VERSION ""

NS_ :

BS_:

BU_: Airbag Allrad EPS Teves_MK60_ESP LWS LWR Teves_MK70_MABS Waehlhebel EPB TRW_ESP ACC_Radar AFS Magne_Ride RKA_Plus Selespeed Waehlhebel_Sele PDC_PLA Lenkhilfe_APA VAQ Daempfer Hybrid_BMS Hybrid_PWR Hybrid_DQ200 EKlimakomp SWA HCA ACC_Lidar Lenkhilfe_ZF_3G FLA AG6 DQ Hybrid_MSG Diesel Otto Gateway_PQ35_A Gateway_PQ46_A Vector_XXX Fzg_CAN

BO_ 3221225472 VECTOR__INDEPENDENT_SIG_MSG: 0 Vector__XXX
 SG_ AL1_Begrenzungsmo : 0|8@1+ (0.39,0) [0|99.06] "%MDI" Vector__XXX
 SG_ BR2_Sta_BrAssi : 0|1@1+ (1,0) [0|1] "" Vector__XXX
 SG_ BR2_Zeitstemp : 0|16@1+ (1,0) [0|65535] "tics" Vector__XXX
 SG_ BR2_TTic_Skal : 0|8@1+ (0.04,0) [0|10.2] "µs" Vector__XXX
 SG_ BR2_Querb_TTic : 0|1@1+ (1,0) [0|1] "" Vector__XXX
 SG_ EP1_Verschleiss : 0|2@1+ (1,0) [0|3] "" Vector__XXX
 SG_ GE1_Code_MSG : 0|1@1+ (1,0) [0|1] "" Vector__XXX
 SG_ GE1_v_halten : 0|1@1+ (1,0) [0|1] "" Vector__XXX
 SG_ GE1_Mrad_Mk2 : 0|8@1+ (0.4,0) [0|101.6] "" Vector__XXX
 SG_ GH1_FreigabeSSK0 : 0|1@1+ (1,0) [0|1] "" Vector__XXX
 SG_ LDW_res_24 : 0|1@1+ (1,0) [0|1] "" Vector__XXX
 SG_ LDW_res_25 : 0|1@1+ (1,0) [0|1] "" Vector__XXX
 SG_ LDW_res_26 : 0|1@1+ (1,0) [0|1] "" Vector__XXX
 SG_ LDW_res_28 : 0|1@1+ (1,0) [0|1] "" Vector__XXX
 SG_ LDW_res_29 : 0|1@1+ (1,0) [0|1] "" Vector__XXX
 SG_ LDW_res_30 : 0|1@1+ (1,0) [0|1] "" Vector__XXX
 SG_ LDW_res_31 : 0|1@1+ (1,0) [0|1] "" Vector__XXX
 SG_ LDW_res_32 : 0|1@1+ (1,0) [0|1] "" Vector__XXX
 SG_ LDW_res_33 : 0|1@1+ (1,0) [0|1] "" Vector__XXX
 SG_ LDW_res_34 : 0|1@1+ (1,0) [0|1] "" Vector__XXX
 SG_ LDW_res_27 : 0|1@1+ (1,0) [0|1] "" Vector__XXX
 SG_ LDW_res_37 : 0|1@1+ (1,0) [0|1] "" Vector__XXX
 SG_ LDW_res_38 : 0|1@1+ (1,0) [0|1] "" Vector__XXX
 SG_ LDW_res_39 : 0|1@1+ (1,0) [0|1] "" Vector__XXX
 SG_ LDW_res_35 : 0|1@1+ (1,0) [0|1] "" Vector__XXX
 SG_ LDW_res_40 : 0|1@1+ (1,0) [0|1] "" Vector__XXX
 SG_ LDW_res_36 : 0|1@1+ (1,0) [0|1] "" Vector__XXX
 SG_ LDW_res_42 : 0|1@1+ (1,0) [0|1] "" Vector__XXX
 SG_ LDW_res_43 : 0|1@1+ (1,0) [0|1] "" Vector__XXX
 SG_ LDW_res_44 : 0|1@1+ (1,0) [0|1] "" Vector__XXX
 SG_ LDW_res_41 : 0|1@1+ (1,0) [0|1] "" Vector__XXX
 SG_ LDW_res_45 : 0|1@1+ (1,0) [0|1] "" Vector__XXX
 SG_ LDW_res_46 : 0|1@1+ (1,0) [0|1] "" Vector__XXX
 SG_ LDW_res_47 : 0|1@1+ (1,0) [0|1] "" Vector__XXX
 SG_ LDW_res_48 : 0|1@1+ (1,0) [0|1] "" Vector__XXX
 SG_ LDW_res_49 : 0|1@1+ (1,0) [0|1] "" Vector__XXX
 SG_ LDW_res_51 : 0|1@1+ (1,0) [0|1] "" Vector__XXX
 SG_ LDW_res_52 : 0|1@1+ (1,0) [0|1] "" Vector__XXX
 SG_ LDW_res_53 : 0|1@1+ (1,0) [0|1] "" Vector__XXX
 SG_ LDW_res_54 : 0|1@1+ (1,0) [0|1] "" Vector__XXX
 SG_ LDW_res_50 : 0|1@1+ (1,0) [0|1] "" Vector__XXX
 SG_ LDW_res_55 : 0|1@1+ (1,0) [0|1] "" Vector__XXX
 SG_ LDW_res_56 : 0|1@1+ (1,0) [0|1] "" Vector__XXX
 SG_ LDW_res_57 : 0|1@1+ (1,0) [0|1] "" Vector__XXX
 SG_ LDW_res_59 : 0|1@1+ (1,0) [0|1] "" Vector__XXX
 SG_ LDW_res_60 : 0|1@1+ (1,0) [0|1] "" Vector__XXX
 SG_ LDW_res_62 : 0|1@1+ (1,0) [0|1] "" Vector__XXX
 SG_ LDW_res_61 : 0|1@1+ (1,0) [0|1] "" Vector__XXX
 SG_ LDW_res_63 : 0|1@1+ (1,0) [0|1] "" Vector__XXX
 SG_ LDW_res_58 : 0|1@1+ (1,0) [0|1] "" Vector__XXX
 SG_ MO2_Freigabe_Sport : 0|1@1+ (1,0) [0|1] "" Vector__XXX
 SG_ MO7_Ladedruck : 0|8@1+ (0.01,0) [0|2.54] "bar" Vector__XXX
 SG_ KO1_Warn_Heiss : 0|1@1+ (1,0) [0|1] "" Vector__XXX
 SG_ KO2_AussT_FehArt : 0|3@1+ (1,0) [0|7] "" Vector__XXX
 SG_ KO2_Sta_KuehlT : 0|1@1+ (1,0) [0|1] "" Vector__XXX
 SG_ KO2_Sta_Oel_T : 0|1@1+ (1,0) [0|1] "" Vector__XXX
 SG_ GK1_RDWarn_VL : 0|1@1+ (1,0) [0|1] "" Vector__XXX
 SG_ GK1_RDWarn_VR : 0|1@1+ (1,0) [0|1] "" Vector__XXX
 SG_ GK1_RDWarn_HR : 0|1@1+ (1,0) [0|1] "" Vector__XXX
 SG_ GK1_RDWarn_Res : 0|1@1+ (1,0) [0|1] "" Vector__XXX
 SG_ GK1_RDWarn_HL : 0|1@1+ (1,0) [0|1] "" Vector__XXX
 SG_ GK1_RDWarn_1 : 0|1@1+ (1,0) [0|1] "" Vector__XXX
 SG_ GK1_RDK_System : 0|1@1+ (1,0) [0|1] "" Vector__XXX
 SG_ GK1_RDWarn_2 : 0|1@1+ (1,0) [0|1] "" Vector__XXX
 SG_ BSL_DFM : 0|8@1+ (0.4,0) [0|101.6] "%" Vector__XXX
 SG_ BSL_U_Start_BATT : 0|8@1+ (0.05,5) [5|17.7] "V" Vector__XXX

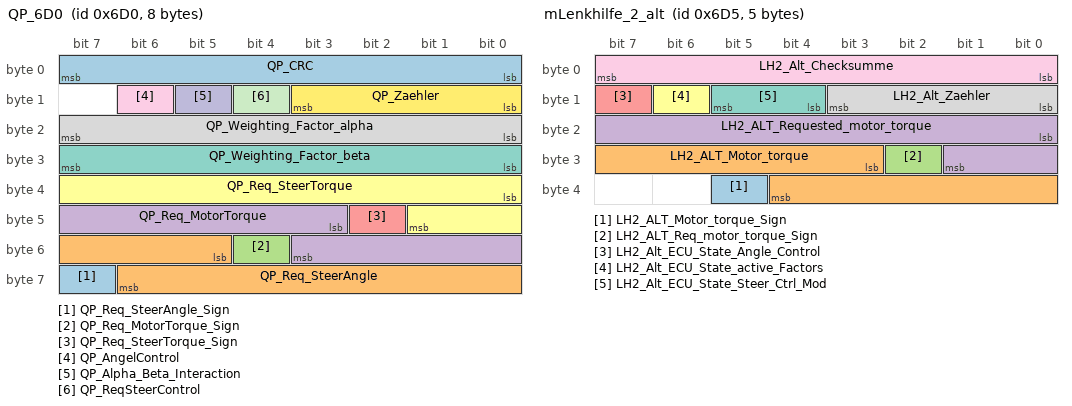
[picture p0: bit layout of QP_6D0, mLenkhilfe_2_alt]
BO_ 1744 QP_6D0: 8 Fzg_CAN
 SG_ QP_Req_SteerAngle_Sign : 63|1@1+ (1,0) [0|1] ""  EPS
 SG_ QP_Req_SteerAngle : 53|10@1+ (1,0) [0|1023] "°"  EPS
 SG_ QP_Req_MotorTorque_Sign : 52|1@1+ (1,0) [0|1] ""  EPS
 SG_ QP_Req_MotorTorque : 43|9@1+ (0.01,0) [0|5.11] "Nm"  EPS
 SG_ QP_Req_SteerTorque_Sign : 42|1@1+ (1,0) [0|1] ""  EPS
 SG_ QP_Req_SteerTorque : 32|10@1+ (0.01,0) [0|10.23] "Nm"  EPS
 SG_ QP_Weighting_Factor_beta : 24|8@1+ (1,0) [0|0] ""  EPS
 SG_ QP_Weighting_Factor_alpha : 16|8@1+ (1,0) [0|0] ""  EPS
 SG_ QP_AngelControl : 14|1@1+ (1,0) [0|0] ""  EPS
 SG_ QP_Alpha_Beta_Interaction : 13|1@1+ (1,0) [0|0] ""  EPS
 SG_ QP_ReqSteerControl : 12|1@1+ (1,0) [0|1] ""  EPS
 SG_ QP_Zaehler : 8|4@1+ (1,0) [0|0] ""  EPS
 SG_ QP_CRC : 0|8@1+ (1,0) [0|0] ""  EPS

 BO_ 1749 mLenkhilfe_2_alt: 5 EPS
 SG_ LH2_ALT_Motor_torque_Sign : 37|1@1+ (1,0) [0|1] ""  Fzg_CAN
 SG_ LH2_ALT_Motor_torque : 27|10@1+ (0.005,0) [0|5.115] "Nm"  Fzg_CAN
 SG_ LH2_ALT_Req_motor_torque_Sign : 26|1@1+ (1,0) [0|1] ""  Fzg_CAN
 SG_ LH2_ALT_Requested_motor_torque : 16|10@1+ (0.006,0) [0|6.138] "Nm"  Fzg_CAN
 SG_ LH2_Alt_ECU_State_Angle_Control : 15|1@1+ (1,0) [0|0] ""  Fzg_CAN
 SG_ LH2_Alt_ECU_State_active_Factors : 14|1@1+ (1,0) [0|0] ""  Fzg_CAN
 SG_ LH2_Alt_ECU_State_Steer_Ctrl_Mod : 12|2@1+ (1,0) [0|0] ""  Fzg_CAN
 SG_ LH2_Alt_Zaehler : 8|4@1+ (1,0) [0|0] ""  Fzg_CAN
 SG_ LH2_Alt_Checksumme : 0|8@1+ (1,0) [0|0] ""  Fzg_CAN

BO_ 80 mAirbag_1: 4 Airbag
 SG_ AB1_Front : 0|1@1+ (1,0) [0|1] ""  Gateway_PQ46_A,Diesel,EPB,TRW_ESP,Gateway_PQ35_A,Hybrid_PWR,Hybrid_BMS,Hybrid_MSG,HCA,SWA,Teves_MK60_ESP
 SG_ AB1_Heck : 1|1@1+ (1,0) [0|1] ""  Gateway_PQ46_A,Diesel,EPB,TRW_ESP,Gateway_PQ35_A,Hybrid_PWR,Hybrid_BMS,Hybrid_MSG,HCA,SWA,Teves_MK60_ESP
 SG_ AB1_Fa_Seite : 2|1@1+ (1,0) [0|1] ""  Gateway_PQ46_A,Diesel,EPB,TRW_ESP,Gateway_PQ35_A,Hybrid_PWR,Hybrid_BMS,Hybrid_MSG,HCA,SWA,Teves_MK60_ESP
 SG_ AB1_Bf_Seite : 3|1@1+ (1,0) [0|1] ""  Gateway_PQ46_A,Diesel,EPB,TRW_ESP,Gateway_PQ35_A,Hybrid_PWR,Hybrid_BMS,Hybrid_MSG,HCA,SWA,Teves_MK60_ESP
 SG_ AB1_Rollover : 4|1@1+ (1,0) [0|1] ""  Gateway_PQ46_A,Diesel,Teves_MK60_ESP,Teves_MK70_MABS,EPB,TRW_ESP,Gateway_PQ35_A,Hybrid_PWR,Hybrid_BMS,Hybrid_MSG,HCA
 SG_ AB1_Status : 9|1@1+ (1,0) [0|1] ""  Gateway_PQ46_A,EPB,TRW_ESP,Gateway_PQ35_A,Hybrid_BMS,Hybrid_MSG,Hybrid_PWR,HCA,Teves_MK60_ESP
 SG_ AB1_Lampe : 8|1@1+ (1,0) [0|1] ""  Gateway_PQ46_A,EPB,TRW_ESP,Gateway_PQ35_A,Hybrid_PWR,Hybrid_BMS,Hybrid_MSG,HCA,Teves_MK60_ESP
 SG_ AB1_Beifahrer : 10|1@1+ (1,0) [0|1] ""  Gateway_PQ46_A,EPB,TRW_ESP,Gateway_PQ35_A,Hybrid_BMS,Hybrid_PWR,Hybrid_MSG,HCA,Teves_MK60_ESP
 SG_ AB1_System : 11|1@1+ (1,0) [0|1] ""  Gateway_PQ46_A,EPB,TRW_ESP,Gateway_PQ35_A,Hybrid_PWR,Hybrid_BMS,Hybrid_MSG,HCA,Teves_MK60_ESP
 SG_ AB1_Gurt_Fa : 12|2@1+ (1,0) [0|3] ""  Gateway_PQ46_A,EPB,TRW_ESP,Gateway_PQ35_A,Hybrid_BMS,Hybrid_MSG,Hybrid_PWR,HCA,Teves_MK60_ESP,Diesel,Otto
 SG_ AB1_Gurt_Bf : 14|2@1+ (1,0) [0|3] ""  Gateway_PQ46_A,EPB,TRW_ESP,Gateway_PQ35_A,Hybrid_BMS,Hybrid_MSG,Hybrid_PWR,HCA,Teves_MK60_ESP
 SG_ AB1_Stellglied : 17|1@1+ (1,0) [0|1] ""  Gateway_PQ46_A,Diesel,EPB,TRW_ESP,Gateway_PQ35_A,Hybrid_BMS,Hybrid_PWR,Hybrid_MSG,HCA,Teves_MK60_ESP,Otto
 SG_ AB1_BF_Warnung : 18|1@1+ (1,0) [0|1] ""  Gateway_PQ46_A,EPB,TRW_ESP,Gateway_PQ35_A,Hybrid_BMS,Hybrid_PWR,Hybrid_MSG,HCA,Teves_MK60_ESP
 SG_ AB1_Diagnose : 16|1@1+ (1,0) [0|1] ""  Gateway_PQ46_A,Gateway_PQ35_A,Hybrid_MSG,HCA,Hybrid_PWR,Hybrid_BMS,TRW_ESP,EPB,Teves_MK60_ESP
 SG_ AB1_Zaehler : 20|4@1+ (1,0) [0|15] ""  Gateway_PQ46_A,Diesel,Otto,EPB,TRW_ESP,Gateway_PQ35_A,Hybrid_MSG,Hybrid_PWR,Hybrid_BMS,HCA,Teves_MK60_ESP
 SG_ AB1_Intens : 5|3@1+ (1,0) [0|7] ""  Gateway_PQ46_A,Diesel,Otto,Teves_MK60_ESP,Teves_MK70_MABS,EPB,TRW_ESP,Gateway_PQ35_A,Hybrid_MSG,Hybrid_PWR,Hybrid_BMS,HCA,SWA
 SG_ AB1_Fehlereintr : 19|1@1+ (1,0) [0|1] ""  Gateway_PQ46_A,EPB,TRW_ESP,Gateway_PQ35_A,Hybrid_BMS,Hybrid_PWR,Hybrid_MSG,HCA,Teves_MK60_ESP
 SG_ AB1_Checksumme : 24|8@1+ (1,0) [0|255] ""  Gateway_PQ46_A,Diesel,Otto,EPB,TRW_ESP,Gateway_PQ35_A,Hybrid_MSG,Hybrid_PWR,Hybrid_BMS,HCA,Teves_MK60_ESP

BO_ 1360 mAirbag_2: 8 Airbag
 SG_ AB2_Beleg_HBF : 10|2@1+ (1,0) [0|3] ""  Gateway_PQ46_A,Gateway_PQ35_A
 SG_ AB2_OOP_BF : 19|3@1+ (1,0) [0|7] ""  Gateway_PQ46_A,Gateway_PQ35_A
 SG_ AB2_Checksum : 0|8@1+ (1,0) [0|255] ""  Gateway_PQ46_A,Gateway_PQ35_A
 SG_ AB2_Beleg_HM : 12|2@1+ (1,0) [0|3] ""  Gateway_PQ46_A,Gateway_PQ35_A
 SG_ AB2_Beleg_HF : 8|2@1+ (1,0) [0|3] ""  Gateway_PQ46_A,Gateway_PQ35_A
 SG_ AB2_Beleg_BF : 14|2@1+ (1,0) [0|3] ""  Gateway_PQ46_A,Gateway_PQ35_A
 SG_ AB2_OOP_Fa : 16|3@1+ (1,0) [0|7] ""  Gateway_PQ46_A,Gateway_PQ35_A
 SG_ AB2_Sta_BF : 22|2@1+ (1,0) [0|3] ""  Gateway_PQ46_A,Gateway_PQ35_A
 SG_ AB2_Gurt_2FaS : 24|2@1+ (1,0) [0|3] ""  Gateway_PQ35_A,Gateway_PQ46_A
 SG_ AB2_Gurt_2BfS : 26|2@1+ (1,0) [0|3] ""  Gateway_PQ35_A,Gateway_PQ46_A
 SG_ AB2_Gurt_2Mi : 28|2@1+ (1,0) [0|3] ""  Gateway_PQ35_A,Gateway_PQ46_A
 SG_ AB2_Gurt_3BfS : 32|2@1+ (1,0) [0|3] ""  Gateway_PQ35_A,Gateway_PQ46_A
 SG_ AB2_Gurt_3FaS : 30|2@1+ (1,0) [0|3] ""  Gateway_PQ35_A,Gateway_PQ46_A
 SG_ AB2_Reserve2 : 36|4@1+ (1,0) [0|15] ""  Gateway_PQ46_A,Gateway_PQ35_A
 SG_ AB2_Gurt_3Mi : 34|2@1+ (1,0) [0|3] ""  Gateway_PQ35_A,Gateway_PQ46_A
 SG_ AB2_Reserve3 : 40|8@1+ (1,0) [0|255] ""  Gateway_PQ46_A,Gateway_PQ35_A
 SG_ AB2_Reserve4 : 48|8@1+ (1,0) [0|255] ""  Gateway_PQ46_A,Gateway_PQ35_A
 SG_ AB2_Reserve5 : 56|8@1+ (1,0) [0|255] ""  Gateway_PQ46_A,Gateway_PQ35_A

BO_ 517 mTP_Er_Airbag: 7 Airbag
 SG_ Airbag_TP_Er : 0|56@1+ (1,0) [0|7.2057594038E+016] ""  Gateway_PQ46_A,Gateway_PQ35_A

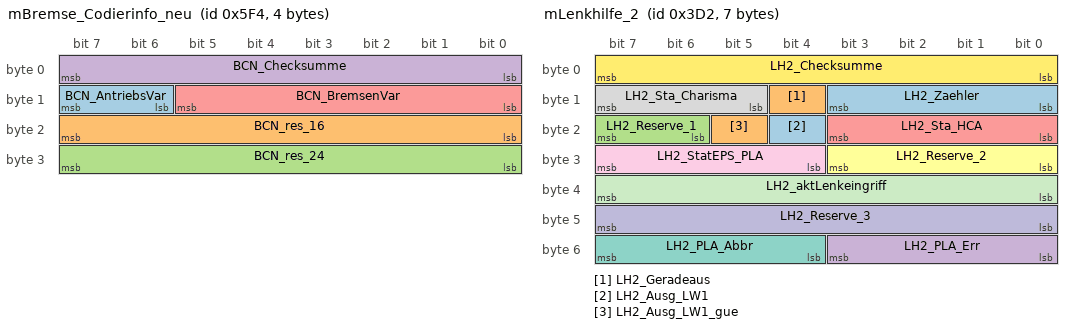
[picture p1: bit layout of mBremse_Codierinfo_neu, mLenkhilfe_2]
BO_ 1524 mBremse_Codierinfo_neu: 4 Airbag
 SG_ BCN_AntriebsVar : 14|2@1+ (1,0) [0|3] ""  Teves_MK60_ESP
 SG_ BCN_res_16 : 16|8@1+ (1,0) [0|255] ""  Teves_MK60_ESP
 SG_ BCN_res_24 : 24|8@1+ (1,0) [0|255] ""  Teves_MK60_ESP
 SG_ BCN_Checksumme : 0|8@1+ (1,0) [0|255] ""  Teves_MK60_ESP
 SG_ BCN_BremsenVar : 8|6@1+ (1,0) [0|63] ""  Teves_MK60_ESP

BO_ 1919 ISO_Airbag_01_Resp: 8 Airbag
 SG_ ISO_Airbag_01_Resp_Data : 0|64@1+ (1,0) [0|1.8446744074E+019] ""  Gateway_PQ46_A,Gateway_PQ35_A

BO_ 2041 Resp_Airbag_Deployment: 8 Airbag
 SG_ Resp_Airbag_Deployment : 0|64@1+ (1,0) [0|1.8446744074E+019] ""  Gateway_PQ46_A,Gateway_PQ35_A

BO_ 522 mTP_Er_Allrad: 7 Allrad
 SG_ Allrad_TP_Er : 0|56@1+ (1,0) [0|7.2057594038E+016] ""  Gateway_PQ46_A,Gateway_PQ35_A

BO_ 704 mAllrad_1: 8 Allrad
 SG_ AL1_Sta_Kup : 2|1@1+ (1,0) [0|1] ""  Gateway_PQ46_A,TRW_ESP,Gateway_PQ35_A,Teves_MK60_ESP
 SG_ AL1_Uebertemp : 1|1@1+ (1,0) [0|1] ""  Gateway_PQ46_A,TRW_ESP,Gateway_PQ35_A
 SG_ AL1_Kup_offen : 3|1@1+ (1,0) [0|1] ""  Gateway_PQ46_A,TRW_ESP,Gateway_PQ35_A,RKA_Plus
 SG_ AL1_Fehler : 0|1@1+ (1,0) [0|1] ""  Gateway_PQ46_A,TRW_ESP,Gateway_PQ35_A,RKA_Plus,Teves_MK60_ESP
 SG_ AL1_Einheit M : 7|1@1+ (1,0) [0|1] ""  Gateway_PQ46_A,Teves_MK60_ESP,Teves_MK70_MABS,TRW_ESP,Gateway_PQ35_A,RKA_Plus
 SG_ AL1_Warnlampe : 5|1@1+ (1,0) [0|1] ""  Gateway_PQ46_A,TRW_ESP,Gateway_PQ35_A
 SG_ AL1_Limiter : 6|1@1+ (1,0) [0|1] ""  Gateway_PQ46_A,Gateway_PQ35_A
 SG_ AL1_Ist_Proz m1 : 8|8@1+ (0.794,-101.632) [0|100.044] "%"  Gateway_PQ46_A,Teves_MK60_ESP,Teves_MK70_MABS,TRW_ESP,Gateway_PQ35_A,RKA_Plus
 SG_ AL1_Notlauf : 4|1@1+ (1,0) [0|1] ""  Gateway_PQ46_A,TRW_ESP,Gateway_PQ35_A
 SG_ AL1_Sta_PNG : 16|3@1+ (1,0) [0|7] ""  Gateway_PQ46_A,Gateway_PQ35_A,AFS,Teves_MK60_ESP
 SG_ AL1_Schalten : 24|1@1+ (1,0) [0|1] ""  Gateway_PQ46_A,Gateway_PQ35_A
 SG_ AL1_Quersp_Sta : 46|2@1+ (1,0) [0|3] ""  Gateway_PQ46_A,Gateway_PQ35_A
 SG_ AL1_Vorwarnung : 25|1@1+ (1,0) [0|1] ""  Gateway_PQ46_A,Gateway_PQ35_A
 SG_ AL1_Fehlereintr : 31|1@1+ (1,0) [0|1] ""  Gateway_PQ46_A,Gateway_PQ35_A
 SG_ AL1_Anz_blinken : 19|1@1+ (1,0) [0|1] ""  Gateway_PQ46_A,Gateway_PQ35_A
 SG_ AL1_Sta_Laengssp : 20|2@1+ (1,0) [0|3] ""  Gateway_PQ46_A,Gateway_PQ35_A
 SG_ AL1_Ist_Nm m0 : 8|8@1+ (7,-896) [-896|882] "Nm"  Gateway_PQ46_A,TRW_ESP,Gateway_PQ35_A,RKA_Plus
 SG_ AL1_Diff_Verbau : 56|1@1+ (1,0) [0|1] ""  Gateway_PQ46_A,Gateway_PQ35_A
 SG_ AL1_AnfVerteiler : 27|1@1+ (1,0) [0|1] ""  Gateway_PQ46_A,Gateway_PQ35_A
 SG_ AL1_FaWu_Laengs : 40|2@1+ (1,0) [0|3] ""  Gateway_PQ46_A,Gateway_PQ35_A
 SG_ AL1_FaWu_HA : 42|2@1+ (1,0) [0|3] ""  Gateway_PQ46_A,Gateway_PQ35_A
 SG_ AL1_Limit_maxkmh : 48|8@1+ (1,0) [0|254] ""  Gateway_PQ46_A,Gateway_PQ35_A
 SG_ AL1_KupSteifig_F : 30|1@1+ (1,0) [0|1] ""  Gateway_PQ46_A,Gateway_PQ35_A
 SG_ AL1_FaWu_VA : 44|2@1+ (1,0) [0|3] ""  Gateway_PQ46_A,Gateway_PQ35_A
 SG_ AL1_Sta_VA : 28|2@1+ (1,0) [0|3] ""  Gateway_PQ46_A,Gateway_PQ35_A
 SG_ AL1_Sta_Quersp : 22|2@1+ (1,0) [0|3] ""  Gateway_PQ46_A,Gateway_PQ35_A
 SG_ AL1_Warnton : 59|1@1+ (1,0) [0|1] ""  Gateway_PQ46_A,Gateway_PQ35_A
 SG_ AL1_Stellung_Getr : 26|1@1+ (1,0) [0|1] ""  Gateway_PQ46_A,Gateway_PQ35_A,Teves_MK60_ESP
 SG_ AL1_KupplTemp : 32|8@1+ (1,-60) [-60|193] "°C"  Gateway_PQ46_A,Gateway_PQ35_A
 SG_ AL1_Diff_Lampe : 57|1@1+ (1,0) [0|1] ""  Gateway_PQ46_A,Gateway_PQ35_A
 SG_ AL1_Zaehler : 60|4@1+ (1,0) [0|15] ""  Gateway_PQ46_A,Gateway_PQ35_A,TRW_ESP
 SG_ AL1_Diff_Gong : 58|1@1+ (1,0) [0|1] ""  Gateway_PQ46_A,Gateway_PQ35_A

BO_ 978 mLenkhilfe_2: 7 EPS
 SG_ LH2_Zaehler : 8|4@1+ (1,0) [0|15] ""  PDC_PLA,HCA
 SG_ LH2_Geradeaus : 12|1@1+ (1,0) [0|1] ""  LWS,Magne_Ride,PDC_PLA,HCA
 SG_ LH2_Reserve_1 : 22|2@1+ (1,0) [0|3] ""  HCA,PDC_PLA
 SG_ LH2_PLA_Err : 48|4@1+ (1,0) [0|15] ""  PDC_PLA,HCA
 SG_ LH2_Sta_HCA : 16|4@1+ (1,0) [0|15] ""  PDC_PLA,HCA
 SG_ LH2_Reserve_2 : 24|4@1+ (1,0) [0|15] ""  HCA,PDC_PLA
 SG_ LH2_PLA_Abbr : 52|4@1+ (1,0) [0|15] ""  PDC_PLA,HCA
 SG_ LH2_Sta_Charisma : 13|3@1+ (1,0) [0|3] ""  PDC_PLA,HCA
 SG_ LH2_StatEPS_PLA : 28|4@1+ (1,0) [0|15] ""  PDC_PLA,HCA
 SG_ LH2_Reserve_3 : 40|8@1+ (1,0) [0|255] ""  HCA,PDC_PLA
 SG_ LH2_aktLenkeingriff : 32|8@1+ (1,0) [0|255] ""  PDC_PLA,HCA
 SG_ LH2_Checksumme : 0|8@1+ (1,0) [0|255] ""  PDC_PLA,HCA
 SG_ LH2_Ausg_LW1 : 20|1@1+ (1,0) [0|1] "" Vector__XXX
 SG_ LH2_Ausg_LW1_gue : 21|1@1+ (1,0) [0|1] "" Vector__XXX

BO_ 976 mLenkhilfe_1: 6 EPS
 SG_ LH1_Sicherheitslamp : 8|1@1+ (1,0) [0|1] ""  Gateway_PQ46_A,Gateway_PQ35_A
 SG_ LH1_Lastinfo : 0|7@1+ (1,0) [0|127] "A"  Gateway_PQ46_A,Gateway_PQ35_A
 SG_ LH1_Reserve1 : 22|2@1+ (1,0) [0|3] ""  Gateway_PQ46_A,Gateway_PQ35_A
 SG_ LH1_Fehlereintr : 15|1@1+ (1,0) [0|1] ""  Gateway_PQ46_A,Gateway_PQ35_A
 SG_ LH1_SleepInd : 14|1@1+ (1,0) [0|1] ""  Gateway_PQ46_A,Gateway_PQ35_A
 SG_ LH1_Fehler_LI : 7|1@1+ (1,0) [0|1] ""  Gateway_PQ46_A,Gateway_PQ35_A
 SG_ LH1_Akustiksign : 13|1@1+ (1,0) [0|1] ""  Gateway_PQ46_A,Gateway_PQ35_A
 SG_ LH1_ULeistung : 32|8@1+ (0.5,0) [0|100] "%"  Gateway_PQ46_A,Gateway_PQ35_A
 SG_ LH1_NL_LeistDichte : 31|1@1+ (1,0) [0|1] ""  Gateway_PQ46_A,Gateway_PQ35_A
 SG_ LH1_EPS_Diagmode : 16|1@1+ (1,0) [0|1] ""  Gateway_PQ46_A,Gateway_PQ35_A
 SG_ LH1_NL_ECU : 29|1@1+ (1,0) [0|1] ""  Gateway_PQ46_A,Gateway_PQ35_A
 SG_ LH1_Textbits : 10|3@1+ (1,0) [0|7] ""  Gateway_PQ46_A,Gateway_PQ35_A
 SG_ LH1_NL_Motor : 30|1@1+ (1,0) [0|1] ""  Gateway_PQ46_A,Gateway_PQ35_A
 SG_ LH1_NL_CAN_SS : 28|1@1+ (1,0) [0|1] ""  Gateway_PQ46_A,Gateway_PQ35_A
 SG_ LH1_NL_Sensor : 27|1@1+ (1,0) [0|1] ""  Gateway_PQ46_A,Gateway_PQ35_A
 SG_ LH1_NL_Uebertemp : 26|1@1+ (1,0) [0|1] ""  Gateway_PQ46_A,Gateway_PQ35_A
 SG_ LH1_NL_Uebersp : 25|1@1+ (1,0) [0|1] ""  Gateway_PQ46_A,Gateway_PQ35_A
 SG_ LH1_NL_Untersp : 24|1@1+ (1,0) [0|1] ""  Gateway_PQ46_A,Gateway_PQ35_A
 SG_ LH1_res_18 : 18|1@1+ (1,0) [0|1] ""  Gateway_PQ46_A,Gateway_PQ35_A
 SG_ LH1_Fehlerlampe : 9|1@1+ (1,0) [0|1] ""  Gateway_PQ46_A,Gateway_PQ35_A
 SG_ LH1_res_17 : 17|1@1+ (1,0) [0|1] ""  Gateway_PQ46_A,Gateway_PQ35_A
 SG_ LH1_gue_ECU_Temp : 19|1@1+ (1,0) [0|1] ""  Gateway_PQ46_A,Gateway_PQ35_A
 SG_ LH1_Kuehlung : 20|1@1+ (1,0) [0|1] ""  Gateway_PQ46_A,Gateway_PQ35_A
 SG_ LH1_ECU_Temp : 40|8@1+ (1,-70) [-70|185] "°C"  Gateway_PQ46_A,Gateway_PQ35_A
 SG_ LH1_Mode_Hybrid : 21|1@1+ (1,0) [0|1] ""  Gateway_PQ46_A,Gateway_PQ35_A

BO_ 521 mTP_Er_Lenkhilfe: 7 EPS
 SG_ Lenkhilfe_TP_Er : 0|56@1+ (1,0) [0|7.2057594038E+016] ""  Gateway_PQ46_A,Gateway_PQ35_A

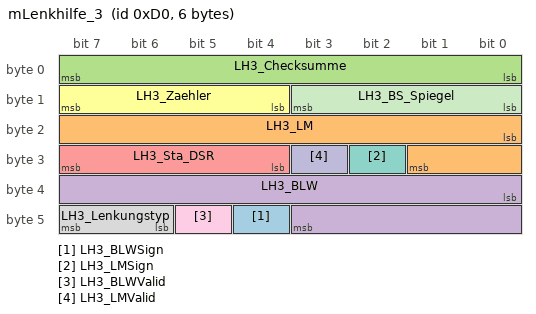
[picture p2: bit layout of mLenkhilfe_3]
BO_ 208 mLenkhilfe_3: 6 EPS
 SG_ LH3_BLWSign : 44|1@1+ (1,0) [0|1] ""  Teves_MK60_ESP,TRW_ESP,HCA,PDC_PLA
 SG_ LH3_LM : 16|10@1+ (0.0147,0) [0|15.0381] "Nm"  Teves_MK60_ESP,TRW_ESP,PDC_PLA,HCA,Diesel,Otto
 SG_ LH3_Checksumme : 0|8@1+ (1,0) [0|255] ""  Teves_MK60_ESP,TRW_ESP,HCA,PDC_PLA
 SG_ LH3_BLW : 32|12@1+ (0.15,0) [0|614.25] "°"  Teves_MK60_ESP,TRW_ESP,HCA,PDC_PLA
 SG_ LH3_Sta_DSR : 28|4@1+ (1,0) [0|15] ""  Teves_MK60_ESP,TRW_ESP,HCA,PDC_PLA
 SG_ LH3_Zaehler : 12|4@1+ (1,0) [0|15] ""  Teves_MK60_ESP,TRW_ESP,HCA,PDC_PLA
 SG_ LH3_LMSign : 26|1@1+ (1,0) [0|1] ""  Teves_MK60_ESP,TRW_ESP,HCA,PDC_PLA,Diesel,Otto
 SG_ LH3_Lenkungstyp : 46|2@1+ (1,0) [0|3] ""  Teves_MK60_ESP,TRW_ESP,HCA,PDC_PLA
 SG_ LH3_BLWValid : 45|1@1+ (1,0) [0|1] ""  Teves_MK60_ESP,TRW_ESP,HCA,PDC_PLA
 SG_ LH3_LMValid : 27|1@1+ (1,0) [0|1] ""  Teves_MK60_ESP,TRW_ESP,HCA,PDC_PLA,Diesel,Otto
 SG_ LH3_BS_Spiegel : 8|4@1+ (1,0) [0|15] ""  Teves_MK60_ESP,TRW_ESP,HCA,PDC_PLA

BO_ 416 mBremse_1: 8 Teves_MK60_ESP
 SG_ BR1_MSR_Anf M : 1|1@1+ (1,0) [0|1] ""  Airbag,Gateway_PQ46_A,Diesel,Otto,DQ,ACC_Radar,Gateway_PQ35_A,RKA_Plus,PDC_PLA,Hybrid_MSG,Hybrid_DQ200,ACC_Lidar,Lenkhilfe_APA
 SG_ BR1_ESP_Eingr : 4|1@1+ (1,0) [0|1] ""  AG6,Airbag,Gateway_PQ46_A,Allrad,Diesel,Otto,DQ,EPB,ACC_Radar,AFS,Gateway_PQ35_A,RKA_Plus,PDC_PLA,Daempfer,Hybrid_MSG,Hybrid_DQ200,HCA,SWA,Selespeed,ACC_Lidar,Lenkhilfe_APA,EPS,Lenkhilfe_ZF_3G
 SG_ BR1_ABS_Brems : 2|1@1+ (1,0) [0|1] ""  Airbag,Gateway_PQ46_A,Allrad,Diesel,DQ,EPB,ACC_Radar,Gateway_PQ35_A,Magne_Ride,RKA_Plus,PDC_PLA,Daempfer,Hybrid_DQ200,HCA,ACC_Lidar,Lenkhilfe_APA
 SG_ BR1_ASR_Anf : 0|1@1+ (1,0) [0|1] ""  Airbag,Gateway_PQ46_A,Diesel,Otto,DQ,ACC_Radar,Gateway_PQ35_A,RKA_Plus,PDC_PLA,Hybrid_MSG,Hybrid_DQ200,ACC_Lidar,Lenkhilfe_APA
 SG_ BR1_ASR_Eingr : 5|2@1+ (1,0) [0|3] ""  AG6,Gateway_PQ46_A,DQ,Gateway_PQ35_A,Hybrid_DQ200,Lenkhilfe_APA
 SG_ BR1_EBV_Eingr : 7|1@1+ (1,0) [0|1] ""  Gateway_PQ46_A,Gateway_PQ35_A,RKA_Plus,Daempfer,Lenkhilfe_APA
 SG_ BR1_StaDruckschw : 12|1@1+ (1,0) [0|1] ""  Gateway_PQ46_A,Diesel,Otto,Gateway_PQ35_A,Hybrid_MSG
 SG_ BR1_Lampe_ASR : 9|1@1+ (1,0) [0|1] ""  Gateway_PQ46_A,Gateway_PQ35_A
 SG_ BR1_Lampe_BK : 10|1@1+ (1,0) [0|1] ""  Gateway_PQ46_A,Gateway_PQ35_A
 SG_ BR1_Lichtschalt : 11|1@1+ (1,0) [0|1] ""  Gateway_PQ46_A,Diesel,Otto,AFS,Gateway_PQ35_A,RKA_Plus,Hybrid_MSG,Lenkhilfe_APA,EPS,Lenkhilfe_ZF_3G
 SG_ BR1_Lampe_ABS : 8|1@1+ (1,0) [0|1] ""  Gateway_PQ46_A,Gateway_PQ35_A
 SG_ BR1_MAD : 13|1@1+ (1,0) [0|1] ""  Gateway_PQ46_A,Gateway_PQ35_A
 SG_ BR1_Sta_MAD : 14|1@1+ (1,0) [0|1] ""  Gateway_PQ46_A,Gateway_PQ35_A
 SG_ BR1_ASRMo_sl : 32|8@1+ (0.39,0) [0|99.06] "%MDI"  Gateway_PQ46_A,Otto,Gateway_PQ35_A,Hybrid_MSG
 SG_ BR1_Diagnose : 15|1@1+ (1,0) [0|1] ""  Gateway_PQ46_A,Gateway_PQ35_A,Airbag
 SG_ BR1_ASRMo_fa m0 : 40|8@1+ (0.39,0) [0|99.06] "%MDI"  Gateway_PQ46_A,Diesel,Otto,Gateway_PQ35_A,Hybrid_MSG
 SG_ BR1_MSR_Mo : 48|8@1+ (0.39,0) [0|99.06] "%MDI"  Gateway_PQ46_A,Diesel,Otto,Gateway_PQ35_A,Hybrid_MSG
 SG_ BR1_BKV_aktiv : 16|1@1+ (1,0) [0|1] ""  Gateway_PQ46_A,Gateway_PQ35_A,Otto,Diesel,Hybrid_MSG
 SG_ BR1_Rad_kmh : 17|15@1+ (0.01,0) [0|326.39] "km/h"  AG6,Airbag,Gateway_PQ46_A,Diesel,EPS,Otto,EPB,ACC_Radar,Gateway_PQ35_A,Magne_Ride,PDC_PLA,Lenkhilfe_APA,Daempfer,Hybrid_MSG,Hybrid_BMS,HCA,SWA,Selespeed,ACC_Lidar,Lenkhilfe_ZF_3G,Hybrid_PWR,FLA
 SG_ BR1_ESPASR_passiv : 61|1@1+ (1,0) [0|1] ""  Gateway_PQ46_A,DQ,ACC_Radar,Gateway_PQ35_A,Magne_Ride,PDC_PLA,Hybrid_DQ200,Selespeed,HCA,ACC_Lidar,Otto,Diesel
 SG_ BR1_Sta_ESP : 62|1@1+ (1,0) [0|1] ""  AG6,Gateway_PQ46_A,Diesel,DQ,ACC_Radar,Gateway_PQ35_A,Magne_Ride,RKA_Plus,Hybrid_DQ200,PDC_PLA,Otto,ACC_Lidar
 SG_ BR1_ASR_ESP : 60|1@1+ (1,0) [0|1] ""  Gateway_PQ46_A,Otto,Gateway_PQ35_A,Hybrid_MSG,Diesel
 SG_ BR1_Zaehler : 56|4@1+ (1,0) [0|15] ""  AG6,Airbag,Gateway_PQ46_A,Diesel,Otto,EPB,ACC_Radar,Gateway_PQ35_A,Magne_Ride,PDC_PLA,Daempfer,Hybrid_MSG,HCA,SWA,ACC_Lidar,Lenkhilfe_APA,EPS,Lenkhilfe_ZF_3G
 SG_ BR1_Ersatz_Kmh : 63|1@1+ (1,0) [0|1] ""  Airbag,Gateway_PQ46_A,Otto,Gateway_PQ35_A,PDC_PLA,Hybrid_MSG,HCA,Lenkhilfe_APA,EPS,Lenkhilfe_ZF_3G
 SG_ BR1_MSR_Mo_inv m1 : 40|8@1+ (-0.39,99.45) [0|99.06] "%MDI"  Gateway_PQ46_A,Diesel,Otto,Gateway_PQ35_A,Hybrid_MSG
 SG_ BR1_EDS_Eingr : 3|1@1+ (1,0) [0|1] ""  Airbag,Gateway_PQ46_A,Diesel,DQ,ACC_Radar,Gateway_PQ35_A,RKA_Plus,PDC_PLA,Daempfer,Hybrid_DQ200,ACC_Lidar,Lenkhilfe_APA

BO_ 1440 mBremse_2: 8 Teves_MK60_ESP
 SG_ BR2_mi_Radgeschw : 9|15@1+ (0.002,0) [0|65.278] "1/s"  Gateway_PQ46_A,DQ,Gateway_PQ35_A,Hybrid_DQ200
 SG_ BR2_QB_Querbeschl m0 : 54|1@1+ (1,0) [0|1] ""  Gateway_PQ46_A,Gateway_PQ35_A,Magne_Ride,RKA_Plus,Allrad,HCA,Diesel,Otto
 SG_ BR2_Querb_Zahn M : 8|1@1+ (1,0) [0|1] ""  Gateway_PQ46_A,Diesel,DQ,Gateway_PQ35_A,Magne_Ride,RKA_Plus,PDC_PLA,Daempfer,Hybrid_DQ200,Otto,HCA,Selespeed,Allrad
 SG_ BR2_Querbeschl m0 : 0|8@1+ (0.01,-1.27) [-1.27|1.27] "g"  Gateway_PQ46_A,Diesel,DQ,Gateway_PQ35_A,Magne_Ride,RKA_Plus,Daempfer,Hybrid_DQ200,Otto,HCA,Selespeed,Allrad
 SG_ BR2_Ueberl_Imp : 51|1@1+ (1,0) [0|1] ""  Gateway_PQ46_A,ACC_Radar,Gateway_PQ35_A,SWA,ACC_Lidar
 SG_ BR2_Fehlereintr : 52|1@1+ (1,0) [0|1] ""  Gateway_PQ46_A,Gateway_PQ35_A
 SG_ BR2_Impulszahl : 56|6@1+ (1,0) [0|63] ""  Gateway_PQ46_A,Gateway_PQ35_A,SWA
 SG_ BR2_LampeHDC : 53|1@1+ (1,0) [0|1] ""  Gateway_PQ46_A,Gateway_PQ35_A
 SG_ BR2_Sta_Imp : 55|1@1+ (1,0) [0|1] ""  Gateway_PQ46_A,ACC_Radar,Gateway_PQ35_A,SWA,ACC_Lidar
 SG_ BR2_Lampe_ASR : 25|1@1+ (1,0) [0|1] ""  Gateway_PQ46_A,Gateway_PQ35_A
 SG_ BR2_SleepInd : 62|1@1+ (1,0) [0|1] ""  Gateway_PQ46_A,Gateway_PQ35_A
 SG_ BR2_Sta_Quer : 63|1@1+ (1,0) [0|1] ""  Gateway_PQ46_A,DQ,Gateway_PQ35_A,Hybrid_DQ200
 SG_ BR2_Wegimpulse : 40|11@1+ (1,0) [0|2047] ""  Gateway_PQ46_A,ACC_Radar,Gateway_PQ35_A,SWA,ACC_Lidar
 SG_ BR2_Aku_Warn : 36|2@1+ (1,0) [0|3] ""  Gateway_PQ46_A,Gateway_PQ35_A
 SG_ BR2_Zahnzahl m1 : 0|6@1+ (1,0) [0|63] ""  Gateway_PQ46_A,Gateway_PQ35_A,RKA_Plus,PDC_PLA
 SG_ BR2_Lampe_ABS : 24|1@1+ (1,0) [0|1] ""  Gateway_PQ46_A,Gateway_PQ35_A,Airbag
 SG_ BR2_Lampe_BK : 26|1@1+ (1,0) [0|1] ""  Gateway_PQ46_A,Gateway_PQ35_A
 SG_ BR2_HDC_aktiv : 38|1@1+ (1,0) [0|1] ""  Gateway_PQ46_A,Diesel,Otto,Gateway_PQ35_A,Hybrid_MSG
 SG_ BR2_Lampe_RKA : 27|1@1+ (1,0) [0|1] ""  Gateway_PQ46_A,Gateway_PQ35_A
 SG_ BR2_Zaehler : 28|4@1+ (1,0) [0|15] ""  Gateway_PQ46_A,Gateway_PQ35_A,Magne_Ride,Daempfer,HCA
 SG_ BR2_Blinkmode : 39|1@1+ (1,0) [0|1] ""  Gateway_PQ46_A,Gateway_PQ35_A
 SG_ BR2_Text : 32|4@1+ (1,0) [0|15] ""  Gateway_PQ46_A,Gateway_PQ35_A

BO_TX_BU_ 978 : Lenkhilfe_ZF_3G,Lenkhilfe_APA,EPS;
BO_TX_BU_ 976 : Lenkhilfe_ZF_3G,Lenkhilfe_APA,EPS;
BO_TX_BU_ 521 : Lenkhilfe_APA,EPS;
BO_TX_BU_ 208 : Lenkhilfe_ZF_3G,Lenkhilfe_APA,EPS;
BO_TX_BU_ 416 : TRW_ESP,Teves_MK70_MABS,Teves_MK60_ESP;
BO_TX_BU_ 1440 : TRW_ESP,Teves_MK70_MABS,Teves_MK60_ESP;

CM_ BO_ 3221225472 "This is a message for not used signals, created by Vector CANdb++ DBC OLE DB Provider.";
CM_ SG_ 3221225472 AL1_Begrenzungsmo "Verteiler Begrenzungsmoment
Der Wert ist gültig, wenn das Bit Verteiler-Anforderung (Byte 4, Bit 3) gesetzt ist. Zum Schutze des VA-Getriebes gibt dieser Wert das max. zulässige Motormoment vor.  Diese Momentenvorgabe  soll analog zum Motoreingriff durch ESP oder Getriebe  in die Min-Auswertung der Motorsteueurng einfließen. ";
CM_ SG_ 3221225472 BR2_Sta_BrAssi "Status Bremsassistent
Textbit: Bremsassistent ausgefallen (nicht VW D1, nicht PQ35/46, nicht D1GP/BY61x) (abwärtskompatibel im Colorado/Colorado GP)Textbit: ´Anfahrhilfe Fehler Werkstatt´ (nur noch T5 alt)";
CM_ SG_ 3221225472 BR2_Zeitstemp "Zeitstempel
Zeitstempel für Geschwindigkeit (mittlere Raddrehzahl) in Timer Tics, z. B. von 20 MHz abgeleitet, und für die Wegimpulse (nur D1GP/BY61x und MK70 alt)";
CM_ SG_ 3221225472 BR2_TTic_Skal "Timer-Skalierung
Wenn Byte 2, Bit 0 = 1: Skalierung des Zeitstempels in den Byte 4 und 5 (nur D1GP/BY61x und MK70 alt)";
CM_ SG_ 3221225472 BR2_Querb_TTic "Querbeschl./TimerTic
Byte 1 hat in der Hochlaufphase eine alternative Bedeutung zur Skalierung des Zeitstempels in den Bytes 4 und 5 (nur D1GP/BY61x und MK70 alt)";
CM_ SG_ 3221225472 EP1_Verschleiss "Verschleissanzeige
00: Belagstärke > x mm10: Belagstärke < y mmes wird der höhere Verschleiss zur Anzeige gebracht (nur Audi D3)";
CM_ SG_ 3221225472 GE1_Code_MSG "Kodierung im MSG
Getriebe-Kodierung im Motor-Steuergerät ist in Ordnung";
CM_ SG_ 3221225472 GE1_v_halten "Geschwindigkeit halten
Bremse verhindert, dass das Fahrzeug beim Schalten des Längsgetriebes zu schnell wird. Nur Colorado!";
CM_ SG_ 3221225472 GE1_Mrad_Mk2 "Übertragungsfunktion
Mrad / Mkurbelwelle für Colorado";
CM_ SG_ 3221225472 GH1_FreigabeSSK0 "Freigabe schnelles Schließen K0
PL71 Hybrid: GSG zeigt an, dass K0 bei Wiederstart schnell geschlossen werden soll (Zweck: Verwendung des folgenden DZ-Sprunges zur Synchronisierung)";
CM_ SG_ 3221225472 LDW_res_24 " 
 ";
CM_ SG_ 3221225472 LDW_res_25 " 
 ";
CM_ SG_ 3221225472 LDW_res_26 " 
 ";
CM_ SG_ 3221225472 LDW_res_28 " 
 ";
CM_ SG_ 3221225472 LDW_res_29 " 
 ";
CM_ SG_ 3221225472 LDW_res_30 " 
 ";
CM_ SG_ 3221225472 LDW_res_31 " 
 ";
CM_ SG_ 3221225472 LDW_res_32 " 
 ";
CM_ SG_ 3221225472 LDW_res_33 " 
 ";
CM_ SG_ 3221225472 LDW_res_34 " 
 ";
CM_ SG_ 3221225472 LDW_res_27 " 
 ";
CM_ SG_ 3221225472 LDW_res_37 " 
 ";
CM_ SG_ 3221225472 LDW_res_38 " 
 ";
CM_ SG_ 3221225472 LDW_res_39 " 
 ";
CM_ SG_ 3221225472 LDW_res_35 " 
 ";
CM_ SG_ 3221225472 LDW_res_40 " 
 ";
CM_ SG_ 3221225472 LDW_res_36 " 
 ";
CM_ SG_ 3221225472 LDW_res_42 " 
 ";
CM_ SG_ 3221225472 LDW_res_43 " 
 ";
CM_ SG_ 3221225472 LDW_res_44 " 
 ";
CM_ SG_ 3221225472 LDW_res_41 " 
 ";
CM_ SG_ 3221225472 LDW_res_45 " 
 ";
CM_ SG_ 3221225472 LDW_res_46 " 
 ";
CM_ SG_ 3221225472 LDW_res_47 " 
 ";
CM_ SG_ 3221225472 LDW_res_48 " 
 ";
CM_ SG_ 3221225472 LDW_res_49 " 
 ";
CM_ SG_ 3221225472 LDW_res_51 " 
 ";
CM_ SG_ 3221225472 LDW_res_52 " 
 ";
CM_ SG_ 3221225472 LDW_res_53 " 
 ";
CM_ SG_ 3221225472 LDW_res_54 " 
 ";
CM_ SG_ 3221225472 LDW_res_50 " 
 ";
CM_ SG_ 3221225472 LDW_res_55 " 
 ";
CM_ SG_ 3221225472 LDW_res_56 " 
 ";
CM_ SG_ 3221225472 LDW_res_57 " 
 ";
CM_ SG_ 3221225472 LDW_res_59 " 
 ";
CM_ SG_ 3221225472 LDW_res_60 " 
 ";
CM_ SG_ 3221225472 LDW_res_62 " 
 ";
CM_ SG_ 3221225472 LDW_res_61 " 
 ";
CM_ SG_ 3221225472 LDW_res_63 " 
 ";
CM_ SG_ 3221225472 LDW_res_58 " 
 ";
CM_ SG_ 3221225472 MO2_Freigabe_Sport "Freigabe Sport
Bit wird gesetzt, wenn die Funktion ´Sport´ bei fehlerfreiem System durch das Motor SG realisiert werden kann (nur Otto im Porsche Cayenne)";
CM_ SG_ 3221225472 MO7_Ladedruck "Ladedruck
Zur Anzeige im Kombi (z.Zt. nur Porsche Colorado, PQ35 Bi-Turbo, Audi RS6)Kombi im PQ35-Bi-Turbo und Audi RS6 interpretiert die normierten CAN-Werte (0-254) als 0-100% der Anzeigeskala";
CM_ SG_ 3221225472 KO1_Warn_Heiss "Heißleuchten-Vorwarnung
Heißleuchtenvorwarnung 5 Grad (applizierbar) vor Erreichen der Warnschwelle für die Heißleuchte (nur PQ24/25/T5)";
CM_ SG_ 3221225472 KO2_AussT_FehArt "Fehlerart Aussentemperatur
Die Motorsteuerung muss bei einem Sensorfehler zwischen Min-Fehler (Kurzschluss gegen Masse) und Max-Fehler (Kurzschluss UBat oder Unterbrechung) unterscheiden können (CARB-Forderung)(Porsche Cayenne)";
CM_ SG_ 3221225472 KO2_Sta_KuehlT "Fehlerstatus Kühlmitteltemperatur (Kombi 2)
n.i.O. steht für Fehlerwert, außerhalb des Meßbereichs (ungenau); nicht verbaut oder noch kein aktueller Wert (nur Porsche Cayenne, BY61x abwärtskompatibel)";
CM_ SG_ 3221225472 KO2_Sta_Oel_T "Fehlerstatus Öltemperatur
n.i.O. steht für Fehlerwert, außerhalb des Meßbereichs (ungenau), nicht verbaut oder noch kein aktueller Wert (nur Porsche Cayenne, BY61x abwärtskompatibel)";
CM_ SG_ 3221225472 GK1_RDWarn_VL "Reifendruckwarnung vorne links
Info aus 'mRDK2/mRDK_Status, Byte 1, Bit 0'";
CM_ SG_ 3221225472 GK1_RDWarn_VR "Reifendruckwarnung vorne rechts
Info aus 'mRDK2/mRDK_Status, Byte 1, Bit 1'";
CM_ SG_ 3221225472 GK1_RDWarn_HR "Reifendruckwarnung Hinten rechts
Info aus 'mRDK2/mRDK_Status, Byte 1, Bit 3'";
CM_ SG_ 3221225472 GK1_RDWarn_Res "Reifendruckwarnung Reserverad
Info aus 'mRDK2/mRDK_Status, Byte 1, Bit 4'";
CM_ SG_ 3221225472 GK1_RDWarn_HL "Reifendruckwarnung Hinten links
Info aus 'mRDK2/mRDK_Status, Byte 1, Bit 2'";
CM_ SG_ 3221225472 GK1_RDWarn_1 "RDK-Warnstufe 1
Info aus 'mRDK2/mRDK_Status, Byte 1, Bit 6'; Warnung erster Priorität";
CM_ SG_ 3221225472 GK1_RDK_System "RDK-Systemfehler
Info aus 'mRDK2/mRDK_Status, Byte 1, Bit 7'";
CM_ SG_ 3221225472 GK1_RDWarn_2 "RDK-Warnstufe 2
Info aus 'mRDK2/mRDK_Status, Byte 1, Bit 5'; Warnung zweiter Priorität";
CM_ SG_ 3221225472 BSL_DFM "Klemme DFM
Messwert Tastverhältnis DFM-Signal (z. Zt. nur Cayenne/Touareg GP, D1GP/BY61x, Phaeton ab MJ07) Info aus mBSG_3, Byte 5";
CM_ SG_ 3221225472 BSL_U_Start_BATT "Starter_Batterie_Spannung
Spannungsmessung vom Lastmanagement (Starterbatterie) (im Touareg GP für V10TDI; Phaeton ab MJ07) Info aus mBSG_2, Byte 3";
CM_ SG_ 80 AB1_Front "Front-Crash
Bit wird bei Überschreitung der Gurtstraffer, US-Schwelle und RDW-Schwelle gesetzt";
CM_ SG_ 80 AB1_Heck "Heck-Crash
wird für neu anlaufende Projekte umgesetzt: AB8.4, Audi8/VW8";
CM_ SG_ 80 AB1_Fa_Seite "Seiten-Crash Fahrer
z. Zt. Nur in Verbindung mit Crash-Intensität 100b (Kraftstoffpumpenabsch.) verwendet";
CM_ SG_ 80 AB1_Bf_Seite "Seiten-Crash Beifahrer
z. Zt. Nur in Verbindung mit Crash-Intensität 100b (Kraftstoffpumpenabsch.) verwendet";
CM_ SG_ 80 AB1_Rollover "Rollover
wird im B6 Cabrio und New Beetle Cabrio, Touareg GP und VW465 bedient";
CM_ SG_ 80 AB1_Status "Airbag deaktiviert
Airbag oder Gurtstraffer wurden per Anpassung deaktiviert: Aktualisierung erst nach Selbsttest";
CM_ SG_ 80 AB1_Lampe "Airbag-Lampe
Sicherheitswarnlampe im Kombi wird vom Airbag-SG angesteuert; Zustand der Lampe wird auf dem CAN-Bus ausgegeben (auch Blinkinformation)";
CM_ SG_ 80 AB1_Beifahrer "Beifahrerairbag deaktiviert
Als Option vorgehalten, Beifahrerairbag wurden per Schlüsselschalter oder Insassenerkennung deaktiviert";
CM_ SG_ 80 AB1_System "Airbag-Systemfehler
Warnlampe (Byte 2, Bit 0) wird dauernd angeschaltet";
CM_ SG_ 80 AB1_Gurt_Fa "Gurtschlossabfrage Fahrer
über Schalter im Gurtschloss";
CM_ SG_ 80 AB1_Gurt_Bf "Gurtschlossabfrage Beifahrer
über Schalter im Gurtschloss";
CM_ SG_ 80 AB1_Stellglied "Airbag im Stellgliedtest
zur Unterdrückung einer Notrufauslösung";
CM_ SG_ 80 AB1_BF_Warnung "Gurtwarnung Beifahrer
im Kombi wird eine Gurtwarnung für den Beifahrer ausgelöst (z. B. Beifahrersitz belegt, Gurt nicht angelegt)";
CM_ SG_ 80 AB1_Diagnose "Airbag in Diagnose
Bei Diagnose über UDS nicht mehr bedient";
CM_ SG_ 80 AB1_Zaehler "Zähler (Airbag 1)
überlaufender Botschaftszähler zur Lebenderkennung";
CM_ SG_ 80 AB1_Intens "Crash-Intensität (Airbag 1)
Die folgende Auswertung ist bei VW geplant: ; >= 001: ZV auf, Innenlicht u. Warnblinker ein ; >= 010: Notruf ausgelöst ; >= 100: Kraftstoffabschaltung (mit RDW-Schwelle aktiviert, d.h.Bit 7 = 1);  ; Information bleibt bei jeder Schwellwert-überschreitung für ca. 10 sec bestehen(Achtung: Energiereserve bei abgetrennter Batterie reicht worstcase nur für 150 msec)Anmerkung: Bosch gibt bei Überschreitung der RDW-Schwelle 111b aus";
CM_ SG_ 80 AB1_Fehlereintr "Fehlerspeichereintrag (Airbag 1)
Bei gesetztem Bit ist mindestens ein Kundendienstfehler eingetragen";
CM_ SG_ 80 AB1_Checksumme "Checksumme (Airbag 1)
Prüfsumme, Definition im CAN Lastenheft";
CM_ SG_ 1360 AB2_Beleg_HBF "Belegungserkennung hinten Beifahrer
über Gurt-Wickelband";
CM_ SG_ 1360 AB2_OOP_BF "OOP Beifahrer (reserviert)
00000101X (z.Zt. Vorhalt)100 Ausl. mit 100 %101 Ausl. mit 70 %110 Ausl. mit 30 %111 (z.Zt. Vorhalt)";
CM_ SG_ 1360 AB2_Checksum "Checksumme
Prüfsumme, Definition im CAN Lastenheft";
CM_ SG_ 1360 AB2_Beleg_HM "Belegungserkennung hinten Mitte
über Gurt-Wickelband";
CM_ SG_ 1360 AB2_Beleg_HF "Belegungserkennung hinten Fahrer
über Gurt-Wickelband";
CM_ SG_ 1360 AB2_Beleg_BF "Belegungserkennung Beifahrersitz
Wird in US-Steuergeräten Audi8R/VW8R/AB8.4E++ bedient, optional bei der RdW, falls SBE-EuroNCAP entschieden wird";
CM_ SG_ 1360 AB2_OOP_Fa "OOP Fahrer (reserviert)
00000101X (z.Zt. Vorhalt)100 Ausl. mit 100 %101 Ausl. mit 70 %110 Ausl. mit 30 %111 (z.Zt. Vorhalt)";
CM_ SG_ 1360 AB2_Sta_BF "Aufmerksamkeitserhöhung Beifahrerairbagstatus
Der Fahrer soll bei einem Statuswechsel des Beifahrerairbags (ausgelöst durch die Beifahrerinsassenerkennung oder den Schlüsselschloßschalter) aufmerksam gemacht werden durch eine Anzeige im Kombi!Nur Audi, gültig für: AB2 (4-Türer AU352), B7, C6, D3";
CM_ SG_ 1360 AB2_Gurt_2FaS "Gurtschlossabfrage 2. Reihe Fahrerseite
Gurtwarnung 2. Reihe Fahrerseite für EuroNCAP 6. Stern";
CM_ SG_ 1360 AB2_Gurt_2BfS "Gurtschlossabfrage 2. Reihe Beifahrerseite
Gurtwarnung 2. Reihe Beifahrerseite für EuroNCAP 6. Stern";
CM_ SG_ 1360 AB2_Gurt_2Mi "Gurtschlossabfrage 2. Reihe Mitte
Gurtwarnung 2. Reihe Mitte für EuroNCAP 6. Stern";
CM_ SG_ 1360 AB2_Gurt_3BfS "Gurtschlossabfrage 3. Reihe Beifahrerseite
Gurtwarnung 3. Reihe Beifahrerseite für EuroNCAP 6. Stern";
CM_ SG_ 1360 AB2_Gurt_3FaS "Gurtschlossabfrage 3. Reihe Fahrerseite
Gurtwarnung 3. Reihe Fahrerseite für EuroNCAP 6. Stern";
CM_ SG_ 1360 AB2_Reserve2 " 
 ";
CM_ SG_ 1360 AB2_Gurt_3Mi "Gurtschlossabfrage 3. Reihe Mitte
Gurtwarnung 3. Reihe Mitte für EuroNCAP 6. Stern";
CM_ SG_ 1360 AB2_Reserve3 " 
 ";
CM_ SG_ 1360 AB2_Reserve4 " 
 ";
CM_ SG_ 1360 AB2_Reserve5 " 
 ";
CM_ SG_ 517 Airbag_TP_Er "TP 2.0 Eroeffnungskanal
 ";
CM_ SG_ 1524 BCN_AntriebsVar "Antriebsvariante
Ausgegeben wird die Antriebsvariante zur Codierplausibilisierung im ESP-Steuergerät";
CM_ SG_ 1524 BCN_res_16 " 
 ";
CM_ SG_ 1524 BCN_res_24 " 
 ";
CM_ SG_ 1524 BCN_Checksumme "Checksumme (Bremse Codierinfo neu)
Prüfsumme, Definition im CAN-Lastenheft";
CM_ SG_ 1524 BCN_BremsenVar "Bremsenvariante
Bremsenvariante00H  keine Variante hinterlegt";
CM_ SG_ 1919 ISO_Airbag_01_Resp_Data "ISO Response Kanal
 ";
CM_ SG_ 2041 Resp_Airbag_Deployment " 
 ";
CM_ SG_ 522 Allrad_TP_Er "TP 2.0 Eroeffnungskanal
 ";
CM_ SG_ 704 AL1_Sta_Kup "Fehlerstatus Kupplungssteifigkeit
Vorgabe des ABS-Steuergerätes ist zur Zeit nicht ausführbar, weil ein Fehler vorliegt oder die aktuelle Vorgabe nicht möglich ist:wird gesetzt, wenn Kupplung fehlerhaft nicht öffnet (nur dann) oder Bremse 4-Botschaft nicht empfangen wird";
CM_ SG_ 704 AL1_Uebertemp "Übertemperaturschutz (Allrad 1)
Kupplung wegen Übertemperatur geöffnet (Elektronikschutz)";
CM_ SG_ 704 AL1_Kup_offen "Kupplung komplett offen
Ventil ist vollständig geöffnet";
CM_ SG_ 704 AL1_Fehler "Fehler Allrad-Kupplung
Systemfehler (Sammelmeldung für alle statischen Fehlerzustände)";
CM_ SG_ 704 AL1_Einheit "Einheit des Kupplungs-Wertes
Kupplungsmoment in Byte 2 erhält eine andere Einheit";
CM_ SG_ 704 AL1_Warnlampe "Allrad-Warnlampe
Vorhalt für zukünftige Projekte (auch für PNG)RPU: Als Kontroll-Symbol Längssperre genutzt";
CM_ SG_ 704 AL1_Limiter "Geschwindigkeitsbegrenzung
Begrenzung der Fahrzeuggeschwindigkeit durch das Motor-SG (Wert muß im MSG appliziert sein). ; Grund kann z.B. verringerte Fahrzeugstabilität bei Geländeuntersetzung sein (nicht PQ35/46)";
CM_ SG_ 704 AL1_Ist_Proz "Kupplungssteifigkeit Mitte (Ist-Wert)
nur wenn Einheit der Kupplungssteifigkeit in Prozente";
CM_ SG_ 704 AL1_Notlauf "Notlauf
Bit wird gesetzt, wenn Irgendein Problem erkannt wurde (auch Time Out-Fehler)";
CM_ SG_ 704 AL1_Sta_PNG "PNG-Status
Als Info für andere Systeme (ADR, 4CL, ...) ob die Geländeuntersetzung aktiv ist.";
CM_ SG_ 704 AL1_Schalten "Schaltung aktiv (Allrad 1)
Aktion wird ausgeführt (nicht bei Audi)";
CM_ SG_ 704 AL1_Quersp_Sta "Quersperren-Status
Quersperre nur im Haldex T5 an Allrad angeschlossen (Init im T5/PQ35/PQ46: 3)";
CM_ SG_ 704 AL1_Vorwarnung "Schaltung Vorwarnung
Schaltung wird demnächst eingeleitet; Bit bleibt bis zum Ende der Schaltung gesetzt (nicht bei Audi)";
CM_ SG_ 704 AL1_Fehlereintr "Fehlerspeichereintrag (Allrad 1)
Bei gesetztem Bit ist mindestens ein Kundendienstfehler eingetragen";
CM_ SG_ 704 AL1_Anz_blinken "PNG-Anzeige blinkend
Vorhalt für PNGRPU: Längssperren-Symbole blinken";
CM_ SG_ 704 AL1_Sta_Laengssp "Längssperren Status
Gibt den Status der Längssperre für andere Systeme an (z.B. ESP, ACC,..)";
CM_ SG_ 704 AL1_Ist_Nm "Kupplungsmoment (Ist-Wert)
Ist-Moment berechnet aus der Drucksensorinformation; 'Kupplung schnell offen heißt, daß der Befehl vom Bremsen-Steuergerät ausgeführt wird (d.h. Sollzustand, kein Istwert !), ; der Arbeitsbereich geht von 0 (=80H) Nm (Kupplung gesteuert offen) bis 882 (=FEH) Nm (gant geschlossen); ; negativer Wertebereich praktisch nicht möglichACHTUNG im T5GP noch alte Auflösung: aus der Radgeschwindigkeitsdifferenz Vorder- zu Hinterachse, der Ventilspannung und der Temperatur errechneter Wert";
CM_ SG_ 704 AL1_Diff_Verbau "Differentialsperre verbaut
Nur im T5: Differentialsperre ist an Allrad-SG angeschlossen (Init im T5/PQ35/PQ46: 1)";
CM_ SG_ 704 AL1_AnfVerteiler "Verteiler-Anforderung
Im PQ35/46 mit 0 belegt, wenn in Byte 5 die Kupplungstemperatur gesendet wird.Wenn dieses Bit gesetzt ist, soll das Motormoment auf den im Byte 5 gesendeten Wert reduziert werden.";
CM_ SG_ 704 AL1_FaWu_Laengs "Fahrerwunsch Längssperre
Während im Längssperren Status (Byte 3) der tatsächliche Sperrenzustand angegeben wird, werden diese Bits gesetzt, sobald der Fahrwerksschalter entsprechend bedient wird.";
CM_ SG_ 704 AL1_FaWu_HA "Fahrerwunsch Hinterachssperre
Während im Hinterachs Status (Byte 3) der tatsächliche Sperrenzustand angegeben wird, werden diese Bits gesetzt, sobald der Fahrwerksschalter entsprechend bedient wird.";
CM_ SG_ 704 AL1_Limit_maxkmh "Zulässige Geschwindigkeit bei Begrenzung
Höchstgeschwindigkeitsbegrenzung im Motorsteuergerät, aktiviert durch Bit 6 in Byte 1(Signalbeschreibung muß nachgereicht werden)";
CM_ SG_ 704 AL1_KupSteifig_F "Kupplungssteifigkeit im Fehlerzustand
Zusatzinfo, falls im Byte 2 der Fehlerwert FFhex gesendet wird (nur bei Colorado)";
CM_ SG_ 704 AL1_FaWu_VA "Fahrerwunsch Vorderachssperre
Während im Vorderachs Status (Byte 4) der tatsächliche Sperrenzustand angegeben wird, werden diese Bits gesetzt, sobald der Fahrwerksschalter entsprechend bedient wird.";
CM_ SG_ 704 AL1_Sta_VA "Vorderachs Status
Gibt den Status der Vorderachs-Quersperre für andere Systeme an (z.B. ESP, ACC,..)(zur Zeit nur Vorhalt)";
CM_ SG_ 704 AL1_Sta_Quersp "Hinterachs Status
Gibt den Status der Hinterachs-Quersperre für andere Systeme an (z.B. ESP, ACC,..)";
CM_ SG_ 704 AL1_Warnton "Warnton
Warnton Längssperre im RPU0 = kein Warnton1 = Warnton (Summer 2 bzw. Gong1000 als Dauerton)";
CM_ SG_ 704 AL1_Stellung_Getr "Schaltung Neutralstellung
Neutralinformation wird vom Verteilergetriebe eingelesen";
CM_ SG_ 704 AL1_KupplTemp "Kupplungstemperatur
Der Wert ist gültig, wenn das Bit 'Verteiler-Anforderung' (Byte 4, Bit 3) mit 0 belegt ist:Sensorwert Kupplungsöltemperatur";
CM_ SG_ 704 AL1_Diff_Lampe "Differentialsperren-Lampe
Nur im T5 (Init im T5/PQ35/PQ46: 1)";
CM_ SG_ 704 AL1_Zaehler "Botschaftszähler
Botschaftszähler, Definition im CAN-Lastenheft";
CM_ SG_ 704 AL1_Diff_Gong "Differentialsperren-Gong
Bei v > 45 km/h wird Gong angesteuert, wenn Differentialsperre eingelegt ist";
CM_ SG_ 978 LH2_Zaehler "Botschaftszähler
Freilaufender Botschaftszähler, Definition nach CAN-Lastenheft";
CM_ SG_ 978 LH2_Geradeaus "Geradeausfahrt
Geradeausfahrt wird angezeigt, wenn sichergestellt ist, dass sich der Lenkwinkel im Sektor +-180° befindet (Mittensektoranzeige)(nur der LWS empfängt dieses Bit noch)";
CM_ SG_ 978 LH2_Reserve_1 " 
 ";
CM_ SG_ 978 LH2_PLA_Err "PLA Fehler ohne Eintrag
Art des Fehlers ohne Eintrag, 16 Werte möglich (siehe LH EPS/PLA)";
CM_ SG_ 978 LH2_Sta_HCA "Status HCA
Bedeutung der Status-Indizes:0: HCA in der EPS deaktiviert1: HCA Anforderung nicht ausführbar aufgrund von Init-Phase o.Ä. ohne Fehlerspeichereintrag in der Lenkung (Initialisierung, Ausschaltphase, &)2: HCA Anforderung nicht ausführbar aufgrund eines Fehlers mit Fehlerspeichereintrag in der Lenkung (z.B. Kommunikation zum HCA-SG gestört, &)3: EPS bzgl. HCA funktionsbereit4: HCA Anforderung abgewiesen5: HCA Momenteneingriff aktiv, Active Return aktiv7: HCA Momenteneingriff aktiv, Active Return ";
CM_ SG_ 978 LH2_Reserve_2 " 
 ";
CM_ SG_ 978 LH2_PLA_Abbr "PLA Abbruch
Grund des PLA-Abbruchs, 16 Werte möglich (siehe LH EPS/PLA) ";
CM_ SG_ 978 LH2_Sta_Charisma "Status Charisma
Bedeutung der Status-Indices:0: Charisma in der EPS deaktiviert1: Sonderkennung mit Komfort-Charakteristik2: Default: Standardkennung der EPS3: Sonderkennung mit Sport-Charakteristik";
CM_ SG_ 978 LH2_StatEPS_PLA "Status EPS PLA
16 Statuswerte (siehe LH PLA/EPS)";
CM_ SG_ 978 LH2_Reserve_3 " 
 ";
CM_ SG_ 978 LH2_aktLenkeingriff "Lenkeingriff aktiv
Indikation, welcher Eingriff in dieMomentenschnittstelle der EPS in der Umsetzung ist.Bitfeldreihenfolge entspricht Priorität, EPS priorisiert bei zeitgleicher AnforderungBit 0: kein EingriffBit 1: DSRBit 3: Heading ControlBit 5: Torque SteerBit 6: PLA";
CM_ SG_ 978 LH2_Checksumme "Checksumme
Prüfsumme, Definition im CAN-Lastenheft";
CM_ SG_ 978 LH2_Ausg_LW1 "Ausgabe LW1
Steht dieser Wert auf 1, gibt die Lenkhilfe die Lenkwinkelbotschaft Lenkwinkel1 aus. Die Ausgabe ist über den Tester aktivierbar. Dies setzt voraus, dass der Lenkstockschalter diese Botschaft nicht ausgibt.";
CM_ SG_ 978 LH2_Ausg_LW1_gue "Gültigkeit Ausgabe LW1
Signal Ausgabe LW1 darf nur ausgewertet warden, wenn das Gültigkeitsbit gesetzt ist.";
CM_ SG_ 976 LH1_Sicherheitslamp "Sicherheits-Warnlampe Lenkhilfe rot
steuert direkt die Sicherheitswarnlampe Lenkhilfe (rot) an";
CM_ SG_ 976 LH1_Lastinfo "Lastinformation
reale Auflösung z. Zt. 5 Ampere";
CM_ SG_ 976 LH1_Reserve1 " 
 ";
CM_ SG_ 976 LH1_Fehlereintr "Fehlerspeichereintrag (Lenkhilfe 1)
Bei gesetztem Bit ist mindestens ein Kundendienstfehler eingetragen";
CM_ SG_ 976 LH1_SleepInd "Sleep-Indication (Lenkhilfe 1)
Die Sleep-Bereitschaft wird nach Klemme 15 aus durch Setzen dieses Bits signalisiertNMHigh-Teilnehmer der PQ35/46 müssen das Signal nach Kl.-15 aus weiterhin bedienen oder dauerhaft auf 1 = Sleep bereit setzen!";
CM_ SG_ 976 LH1_Fehler_LI "Fehlerstatus Lastinformation
n.i.O. steht für Fehlerwert oder Lastinformation noch nicht verfügbar ";
CM_ SG_ 976 LH1_Akustiksign "Akustiksignal
Ansteuerung eines Akustiksignals (Summer) im Kombi (optional vorgehalten)";
CM_ SG_ 976 LH1_ULeistung "Unterstützungsleistung
Die Unterstützungsleistung gibt prozentual an, in welchem Verhältnis die tatsächlich abgegebene Leistung zur Nominalleistung steht, d.h.:0%    : keine Servounterstützung100%: maximale Servounterstützung (Nominalleistung)0% < Unterstützungsleistung < 100%: Leistungsreduzierungaufgrund eines NotlaufprogrammesHier muß mindestens ein Bit im Bit-Feld Notlauf gesetzt sein";
CM_ SG_ 976 LH1_NL_LeistDichte "Notlauf Leistungsdichte
Bit-Feld zeigt an, dass sich die Lenkhilfe in einem Notlaufprogramm befindet und durch welche Ursache dieses aktiviert wurde:0: ist nicht Auslöser eines Notlaufes1: ist Auslöser eines NotlaufesDas Betriebsverhalten der Lenkhilfe wird an das bestehende Defizit angepasst.1 -> Leistungsdichtebegrenzung bei Mißbrauch";
CM_ SG_ 976 LH1_EPS_Diagmode "EPS Diagnosemode
Anzeige, ob sich die Lenkhilfe in einem Diagnose Mode befindet.";
CM_ SG_ 976 LH1_NL_ECU "Notlauf ECU intern
Bit-Feld zeigt an, dass sich die Lenkhilfe in einem Notlaufprogramm befindet und durch welche Ursache dieses aktiviert wurde:0: ist nicht Auslöser eines Notlaufes1: ist Auslöser eines NotlaufesDas Betriebsverhalten der Lenkhilfe wird an das bestehende Defizit angepasst.1 -> Steuergeräteinterner Defekt";
CM_ SG_ 976 LH1_Textbits "Textbits
Diese Textbits werden verwendet, um im Kombi Texte oder Bilder für die Lenkhilfe darzustellenHybrid:Text 1 (ID_TXT_1026.1): Ausfall LenkunterstützungText 2 (ID_TXT_1026.2): Fehler LenkunterstützungText 3 (ID_TXT_1026.3): Kurzzeitige Störung Lenkunterstützung";
CM_ SG_ 976 LH1_NL_Motor "Notlauf Motor
Bit-Feld zeigt an, dass sich die Lenkhilfe in einem Notlaufprogramm befindet und durch welche Ursache dieses aktiviert wurde:0: ist nicht Auslöser eines Notlaufes1: ist Auslöser eines NotlaufesDas Betriebsverhalten der Lenkhilfe wird an das bestehende Defizit angepasst.1 -> Defekt am Lenkhilfe-Servo-Motor";
CM_ SG_ 976 LH1_NL_CAN_SS "Notlauf CAN-Schnittstelle
Bit-Feld zeigt an, dass sich die Lenkhilfe in einem Notlaufprogramm befindet und durch welche Ursache dieses aktiviert wurde:0: ist nicht Auslöser eines Notlaufes1: ist Auslöser eines NotlaufesDas Betriebsverhalten der Lenkhilfe wird an das bestehende Defizit angepasst.1 -> Die notwendigen Daten aus der CAN-Schnittstelle werden nicht empfangen oder sind fehlerhaft/ungültig.";
CM_ SG_ 976 LH1_NL_Sensor "Notlauf Sensorik
Bit-Feld zeigt an, dass sich die Lenkhilfe in einem Notlaufprogramm befindet und durch welche Ursache dieses aktiviert wurde:0: ist nicht Auslöser eines Notlaufes1: ist Auslöser eines NotlaufesDas Betriebsverhalten der Lenkhilfe wird an das bestehende Defizit angepasst.1 -> Interne Sensorik (z.B. Momentensensor) liefert keine gültigen oder eingeschränkt gültige Signale";
CM_ SG_ 976 LH1_NL_Uebertemp "Notlauf Übertemperatur
Bit-Feld zeigt an, dass sich die Lenkhilfe in einem Notlaufprogramm befindet und durch welche Ursache dieses aktiviert wurde:0: ist nicht Auslöser eines Notlaufes1: ist Auslöser eines NotlaufesDas Betriebsverhalten der Lenkhilfe wird an das bestehende Defizit angepasst.1 -> Interner Temperatursensor hat Überschreitung der zulässigen Höchsttemperatur erkannt";
CM_ SG_ 976 LH1_NL_Uebersp "Notlauf Überspannung
Bit-Feld zeigt an, dass sich die Lenkhilfe in einem Notlaufprogramm befindet und durch welche Ursache dieses aktiviert wurde:0: ist nicht Auslöser eines Notlaufes1: ist Auslöser eines NotlaufesDas Betriebsverhalten der Lenkhilfe wird an das bestehende Defizit angepasst.1 -> Versorgungsspannung Lenkhilfe hat Schwelle Überspannung überschritten";
CM_ SG_ 976 LH1_NL_Untersp "Notlauf Unterspannung
Bit-Feld zeigt an, dass sich die Lenkhilfe in einem Notlaufprogramm befindet und durch welche Ursache dieses aktiviert wurde:0: ist nicht Auslöser eines Notlaufes1: ist Auslöser eines NotlaufesDas Betriebsverhalten der Lenkhilfe wird an das bestehende Defizit angepasst.1 -> Versorgungsspannung Lenkhilfe hat Schwelle Unterspannung unterschritten";
CM_ SG_ 976 LH1_res_18 " 
(war Batterie ab gültig)";
CM_ SG_ 976 LH1_Fehlerlampe "Fehlerlampe Lenkhilfe gelb
steuert direkt die Fehlerlampe Lenkhilfe (gelb); kein Aufprüfen bei Neustart, keine Rückleseinformation in Kombi-Botschaft";
CM_ SG_ 976 LH1_res_17 " 
(war Batterie ab)";
CM_ SG_ 976 LH1_gue_ECU_Temp "ECU-Temperatur Valid
(war: Bordnetzwelligkeit gültig)Gültigkeit der Signale ECU-Temperatur";
CM_ SG_ 976 LH1_Kuehlung "Anforderung Kühlung
nach Überschreiten einer oberen Grenztemperatur fordert die EPS die Zuschaltung einer externen Kühlung, z. B. durch den Kühlerlüfter";
CM_ SG_ 976 LH1_ECU_Temp "ECU_Temperatur
(war: Bordnetzwelligkeit)Temperatur innerhalb der ECU";
CM_ SG_ 976 LH1_Mode_Hybrid "Mode Hybrid-Antrieb
Reserviert für Hybrid-Modus (kodierbar)";
CM_ SG_ 521 Lenkhilfe_TP_Er "TP 2.0 Eroeffnungskanal
 ";
CM_ SG_ 208 LH3_BLWSign "BLW Sign
Vorzeichen ´Berechneter Lenkwinkel´";
CM_ SG_ 208 LH3_LM "Lenkmoment
Gibt das durch den Momentensensor detektiertes Lenkhandmoment (Absolutmoment) aus";
CM_ SG_ 208 LH3_Checksumme "Checksumme (Lenkhilfe 3)
Prüfsumme, Definition im CAN-Lastenheft";
CM_ SG_ 208 LH3_BLW "BLW
Berechneter Lenkradwinkel (BLW)Ausgabe des berechneten Lenkwinkel mit Geradeauslaufkorrektur aus der Position des Lenkmotors (Absolutwert)(nur zur festgelegten Nutzung im ESP, PLA, HCA freigegeben)";
CM_ SG_ 208 LH3_Sta_DSR "Status DSR
0 DSR deaktiviert1 DSR Anforderung nicht ausführbar (ESP Fehlerstatus)2 Kommunikation zum ESP-SG gestört3 EPS bzgl. DSR funktionsbereit4 DSR Anforderung abgewiesen5 externer Momenteneingriff aktiv6 externer Lenkwinkeleingriff aktiv7 externer Momenten und Lenkwinkeleingriff aktiv8..15 reserviert";
CM_ SG_ 208 LH3_Zaehler "Botschaftszähler (Lenkhilfe 3)
Freilaufender Botschaftszähler, dient als Quelle des Botschaftsspiegels in Lenkhilfe_3 Botschaft";
CM_ SG_ 208 LH3_LMSign "Lenkmoment Sign
Vorzeichen Lenkhandmoment";
CM_ SG_ 208 LH3_Lenkungstyp "Lenkungstyp
0 Elektrik Power Steering mit DSR1 (Version ab KW22/05)1 Achsparalleler Antrieb2 Active Dynamik Steering3 Elektrik Power Steering mit DSR2 (Version ab KW22/07)";
CM_ SG_ 208 LH3_BLWValid "BLW Valid
Gültigkeit der Signale ´Berechneter Lenkwinkel´ (BLW und BLW Sign)";
CM_ SG_ 208 LH3_LMValid "Lenkmoment Valid
Gültigkeit der Signale Lenkhandmoment und Vorzeichen Lenkhandmoment";
CM_ SG_ 208 LH3_BS_Spiegel "Botschaftsspiegel
Der Botschaftsspiegel reflektiert die zuletzt empfangene Botschaft der mBremse_9, d. h. der zuletzt empfangene Wert des Botschaftszählers aus der mBremse_9 wird zurückgesendet";
CM_ SG_ 416 BR1_MSR_Anf "MSR Anforderung
Anforderung in Byte 7 ist auszuführen; Byte 6 ändert seine Bedeutung, wenn dieses Bit gesetzt ist";
CM_ SG_ 416 BR1_ESP_Eingr "ESP Eingriff
Fahrdynamikregelung";
CM_ SG_ 416 BR1_ABS_Brems "ABS Bremsung
Antiblockiersystem, Bit zeigt auch Druckabbau an (z.B. ESP hat zuviel Druck aufgebaut oder ungebremste Regelung auf Bahnübergang)";
CM_ SG_ 416 BR1_ASR_Anf "ASR Anforderung
Anforderungen in Byte 5 und 6 sind auszuführen";
CM_ SG_ 416 BR1_ASR_Eingr "ASR-Schaltbeeinflussung
Wunsch an das Getriebe während einer ASR Regelung, bei Audi nur 00 und 01 genutzt";
CM_ SG_ 416 BR1_EBV_Eingr "EBV Eingriff
Elektronische Bremskraftverteilung, aktueller Eingriff (Druckhalten, Druckabbau), kein ABS / ESP-Eingriff";
CM_ SG_ 416 BR1_StaDruckschw "Bremstestschalter / Druckschwellenstatus nicht verfügbar / Status aktiver BKV
beim Bosch-ABS wird der Bremstestschalter (0 kein Bremsen, 1 Bremse betätigt) übertragen (D1GP/BY61x u. T5GP/RPU(MK25A XT)ab PQ46: Druckschwelleninformation (Byte 2, Bit 3) kann noch nicht oder aufgrund eines Fehlers nicht ausgegeben werden (nicht Colorado)Bei einem aktiven BKV wird im angesteuerten Zustand (z.B. bei ESP-Eingriff oder ADR-Bremsung) ohne Beeinflussung des Fahrers das Bremspedal betätigt. In Byte 2, Bit 3 ist ersi";
CM_ SG_ 416 BR1_Lampe_ASR "Lampe ASR / ESP
Zustand der Lampe wird auf dem CAN-Bus ausgegeben (auch Blinkinformation)Fahrzeuge mit ASR/ESP/MABS-Funktionalität bedienen die SicherheitswarnlampeInit: 0/1(SILA)";
CM_ SG_ 416 BR1_Lampe_BK "Bremskontroll-Lampe
rote Lampe wird angesteuert, z. B. bei EBV-Ausfall(Sicherheitswarnlampe im Audi C6/D3, AU716 mit Initwert 1)";
CM_ SG_ 416 BR1_Lichtschalt "Bremslichtschalter / Bremsdruckschwelle überschritten
ohne aktiven BKV wird hier der Bremslichtschalter (0 kein Bremsen, 1 Bremse betätigt) übertragen (ESP5.7, ESP 8, Mk60, T5GP/RPU(MK25A XT));ab PQ46 (mit Einsatz des einkanaligen Hall-BLS):  Fahrer hat durch Pedalbetätigung die Bremsdruckschwelle überschritten (nicht ACC oder EPB-Bremsung)Im Colorado: Info wird erkannt, wenn der Fahrer einen aktiven BKV übertritt (Löseschalterinformation plus Plausibilität); Nur im Porsche Cayenne wird das Bit auch bei G";
CM_ SG_ 416 BR1_Lampe_ABS "Lampe ABS
Sicherheitswarnlampe";
CM_ SG_ 416 BR1_MAD "Schlechtwegausblendung
OBD-Funktion (MAD-Signal), wird bei Teves / TRW z.Zt. nicht ausgegeben";
CM_ SG_ 416 BR1_Sta_MAD "Fehlerstatus Schlechtwegausblendung
ESP 5.7: Im ESP-Fehlerfall ist Bit ´ungültig´ESP 8: Im ESP-Fehler ist Bit weiterhin ´gültig´Initwert 1 wird gesendet, wenn Funktion nicht umgesetzt";
CM_ SG_ 416 BR1_ASRMo_sl "ASR Eingriffsmoment langsam
wird im PQ46 nicht bedient (PQ46 sendet 0)Hybrid:Interpretiert als Reduktion Summenmoment VM+EM";
CM_ SG_ 416 BR1_Diagnose "ABS-Diagnose
Kombi unterdrückt z.B. den Gong";
CM_ SG_ 416 BR1_ASRMo_fa "ASR Eingriffsmoment schnell
falls Byte 1, Bit 1 gleich 0Achtung: Fehlerwert FFH wird nur benutzt, wenn es ein ASR-Eingriffsmoment ist - nicht beim bitinvertierten MSR-MomentHinweis T5GP/RPU: Bei zweikanaliger Anforderung muss Bremsensteuergerät die Zündwinkelreserve aus mMotor_2 Byte 8 auswerten.Hybrid:Interpretiert als Reduktion Summenmoment VM+EM";
CM_ SG_ 416 BR1_MSR_Mo "MSR Eingriffsmoment
Hybrid:Interpretiert als Summenmoment VM+EM";
CM_ SG_ 416 BR1_BKV_aktiv "Aktiver Bremskraftverstärker
neues Status-Bit zur Vermeidung von Problemen während der Übergangszeit auf die neue Definition (BKV) und zur Darstellung des Fehlerzustandes: nur noch in T5 und im Colorado";
CM_ SG_ 416 BR1_Rad_kmh "Geschwindigkeit (Bremse 1)
Low Byte 3, High Byte 4 (Auflösung 1,28 km/h);  ; Bremse holt sich den Radumfang aus der Botschaft 'Kombi_3; ; generell wird Mittelwert (alle außer B6/D3) der permanent angetriebenen Räder ausgegeben (d.h. bei Frontantrieb und gesteuertem Allrad (Haldex) Mittelwert der Vorderräder, bei Allrad Mittelwert der 4 Räder) oder bei Audi B6/D3 die Geschwindigkeit des linken Vorderrades, bei MSR oder ABS Eingriffen wird die ABS-Referenzgeschwindigkeit für >=200 msec eingespiegelt (Zeit ";
CM_ SG_ 416 BR1_ESPASR_passiv "ESP_ASR Passiv getastet
ESP oder ASR (oder beides, oder Teilfunktionen, solange Fahrer nicht bremst) vom Fahrer passiv getastet";
CM_ SG_ 416 BR1_Sta_ESP "ESP-Systemstatus
Fehler steht für Stillegung ESP mit Fehlereintrag";
CM_ SG_ 416 BR1_ASR_ESP "ASR/ESP-Steuergerät
Kombi kann ggfs. die Lampe ansteuern";
CM_ SG_ 416 BR1_Zaehler "Zähler (Bremse 1)
überlaufender Botschaftszähler, um Eingriffsmoment als aktualisiert zu kennzeichnen";
CM_ SG_ 416 BR1_Ersatz_Kmh "Geschwindigkeits-Ersatzwert
Geschwindigkeit wird als Ersatzwert ausgegeben (z.B. ein Sensor defekt, kein Radumfang gelernt, kein oder fehlerhafter Radumfang vom Kombi empfangen oder bei Contiteves und passiven Sensoren wird Hinterrad eingespiegelt)";
CM_ SG_ 416 BR1_MSR_Mo_inv "inverses MSR Eingriffsmoment
falls Byte 1, Bit 1 gleich 1";
CM_ SG_ 416 BR1_EDS_Eingr "EDS Eingriff
Elektronische Differentialsperre";
CM_ SG_ 1440 BR2_mi_Radgeschw "mittlere Raddrehzahl (Bremse 2)
Radumdrehungen / Sekunde sind Eingangsgröße für die Geschwin-digkeitsberechnung im Kombi; es wird der Mittelwert der permanent angetriebenen Räder (alle außer Audi B6/D3) ausgegeben oder bei Audi B6/D3 die Geschwindigkeit des linken Vorderrades; im Kombi wird aus dieser Raddrehzahl und dem Radumfang die Fahrzeuggeschwindigkeit errechnetRPU: 4*2 Mittelwert HA , 4*4 zuschaltbar (starr) Mittelwert der HA , 4*4 Torsen Mittelwert aller RäderT5GP: 4*2 Mittelwert VA, 4*4 Haldex Mi";
CM_ SG_ 1440 BR2_QB_Querbeschl "Qualifizierungsbit Querbeschleunigung
Definition nach CAN-LastenheftHinweis zu CT-ESP: Bit wird auch gesetzt, wenn Querbeschl. bei ESP errechnet statt gemessen wird (nicht Colorado/Colorado GP, nicht D1GP/BY61x)(ACHTUNG: war Summer Reifendruckwarnung RB im PQ24)";
CM_ SG_ 1440 BR2_Querb_Zahn "Querbeschl./Zähnezahl
Byte 1 hat in der Hochlaufphase (Boschsystem: ca. 2s, Contisystem: ca. 1,7s) eine alternative Bedeutung: Zähnezahl der Impulsräder werden übertragen";
CM_ SG_ 1440 BR2_Querbeschl "Querbeschleunigung
Wenn Byte 2, Bit 0 = 0: errechnete Größe (vorläufig) zur Kurvenfahrterkennung für das Getriebe, oder gemessener Sensorwert (siehe Byte 8, Bit 7) (im PQ35 kein Rohwert). Bei Linkskurve positives Vorzeichen.Achtung: Die Güte bei errechneten Größen (z. B. bei MK70 neu) kann situationsbedingt sehr schlecht sein!FFH bedeutet hier die Größe kann nicht berechnet werden, oder Sensor defekt";
CM_ SG_ 1440 BR2_Ueberl_Imp "Wegimpulszählerstatus
der Wegimpuls-Zähler ist mindestens einmal übergelaufen (Reset des ABS-Steuergerätes) kann damit erkannt werden ";
CM_ SG_ 1440 BR2_Fehlereintr "Fehlerspeichereintrag (Bremse 2)
Bei gesetztem Bit ist mindestens ein Kundendienstfehler eingetragen";
CM_ SG_ 1440 BR2_Impulszahl "Impulszahl
Zähnezahl des verwendeten ImpulsradesBei Neuentwicklungen muss die Impulszahl aus Byte 1 (Ausgabe während der Hochlaufphase) verwendet werden";
CM_ SG_ 1440 BR2_LampeHDC "Funktionslampe HDC
Funktionslampe Bergabfahrassistent (HDC nur im VW416 / im RPU geplant)(ACHTUNG: war Lampe Reifendruckwarnung RB im PQ24)";
CM_ SG_ 1440 BR2_Sta_Imp "Fehlerstatus Wegimpulse
Fehler wird gesetzt, wenn beide ABS-Drehzahlfühler an der Vorderachse defekt sind";
CM_ SG_ 1440 BR2_Lampe_ASR "Lampe ASR / ESP
Zustand der Lampe wird auf dem CAN-Bus ausgegeben (auch Blinkinformation)Fahrzeuge mit ASR/ESP/MABS-Funktionalität bedienen die SicherheitswarnlampeInit: 0 (ABS)/1 (ASR/ESP SILA), siehe Bremse_1 Byte 2, Bit 1 (nicht D1GP/BY61x/MK70 alt)";
CM_ SG_ 1440 BR2_SleepInd "Sleep-Indication
Die Sleep-Bereitschaft wird nach Klemme 15 aus durch Setzen dieses Bits signalisiert (nicht VW D1/Colorado, nicht D1GP/BY61x, nicht RB PQ25)NMHigh-Teilnehmer der PQ35/46 müssen das Signal nach Kl.-15 aus weiterhin bedienen oder dauerhaft auf 1 = Sleep bereit setzen!";
CM_ SG_ 1440 BR2_Sta_Quer "gemessene Querbeschleunigung
Querbeschleunigung in Byte 1 wird errechnet oder beim ESP gemessen";
CM_ SG_ 1440 BR2_Wegimpulse "Wegimpulse Vorderachse
Low Byte 6, High Byte 7 (3 Bits genutzt); Anzahl der Raddrehzahl-impulse (steigende und fallende Flanke) der Vorderachse (gemittelt) zur Wegstreckenzählung; bei Ausfall eines Drehzahlfühlers wird der funktionsfähige Sensor zur Ausgabe verwendet";
CM_ SG_ 1440 BR2_Aku_Warn "Akustische Warnung
1: Bremse steuert den Gong im Kombi ein Mal an (nicht VW)2: Bremse steuert den Gong (Summer bei VW) im Kombi drei Mal an, z. Zt. nur in Kombination mit Text ´Werkstatt Bremse´ (Ausfall der EBV)3: Summeransteuerung ist durch Kombi auf 1 Sekunde festgelegt. Auslösung durch 0 -> 1 Flanke. (bei VW: gelbe Warnung)(nicht D1GP/BY61x/MK70 alt)";
CM_ SG_ 1440 BR2_Zahnzahl "Zähnezahl
Wenn Byte 2, Bit 0 = 1: Zähnezahl des verwendeten Impulsrades";
CM_ SG_ 1440 BR2_Lampe_ABS "Lampe ABS
Sicherheitswarnlampe, siehe Bremse_1 Byte 2, Bit 0 (nicht D1GP/BY61x/MK70 alt)";
CM_ SG_ 1440 BR2_Lampe_BK "Bremskontroll-Lampe
(Blinktakt wird nur bei Audi wie bisher vom Kombi generiert)Separate Bremskontroll-Lampe (Audi ab D3/C6) wird als Sicherheitswarnlampe aufgeprüft (Initwert 1); Kombinierte Bremskontroll-Lampe (VW) wird aufgeprüft, siehe Bremse_1 Byte 2, Bit 2 Zustand der Lampe wird auf dem CAN-Bus ausgegeben (auch Blinkinformation)Fahrzeuge mit ASR/ESP/MABS-Funktionalität bedienen die SicherheitswarnlampeInit: 0 (ABS)/1 (ASR/ESP SILA), siehe Bremse_1 Byte 2, Bit 1 (nicht D1GP/BY61x/MK70 alt)";
CM_ SG_ 1440 BR2_HDC_aktiv "HDC aktiv
Die Funktion Bergabfahrassistent ist bei gesetztem Bit aktiv. Das Motor SG nutzt Info zum Umschalten der GRA Funktion. (nur im VW416 / im RPU geplant)(nicht D1GP/BY61x)";
CM_ SG_ 1440 BR2_Lampe_RKA "Warnlampe RKA
Reifen-Kontroll-Anzeige (indirekt messende Reifendrucküberwachung): siehe Bremse_4 Byte 4, Bit 0 Zustand der Lampe wird auf dem CAN-Bus ausgegeben (auch Blinkinformation)Fahrzeuge mit ASR/ESP/MABS-Funktionalität bedienen die SicherheitswarnlampeInit: 0 (ABS)/1 (ASR/ESP SILA), siehe Bremse_1 Byte 2, Bit 1 (nicht D1GP/BY61x/MK70 alt)";
CM_ SG_ 1440 BR2_Zaehler "Zähler Bremse2
Überlaufender Zähler (nicht D1GP/BY61x/MK70 alt)";
CM_ SG_ 1440 BR2_Blinkmode "Bremskontroll-Blinkmode
Bremskontroll-Lampe soll im Warnfall mit 1Hz blinken, wenn das Bit gesetzt ist (z. Zt. nur bei VW)  (nicht D1GP/BY61x/MK70 alt)";
CM_ SG_ 1440 BR2_Text "Textausgabe
0 Kein Text1 ´ESP Störung´2 ´ABS Störung´3 ´ESP/ABS Störung´4 ´Werkstatt Bremse´5 ´ASR Störung´6 ´ESP Deaktiviert´7 ´ASR Deaktiviert´8 ´ESP Aktiviert´9 ´Störung Hillholder´ (PQ46) ´Anfahrhilfe Fehler Werkstatt´ (T5GP)10 ´Keine Bremskraftverstärkung´11 ´ASR aktiviert´12 ´ABS/ASR Störung´13 ´Bitte Reifen prüfen´14...15 Reserviert(nicht D1GP/BY61x/MK70 alt)";
BA_DEF_  "NmType" STRING ;
BA_DEF_  "NmBaseAddress" HEX 0 2047;
BA_DEF_  "NmhBaseAddress" HEX 0 2047;
BA_DEF_  "Manufacturer" STRING ;
BA_DEF_  "NmMessageCount" INT 1 255;
BA_DEF_  "NmhMessageCount" INT 1 255;
BA_DEF_ BU_  "NmStationAddress" HEX 0 99;
BA_DEF_ BU_  "NmNode" ENUM  "No","Yes";
BA_DEF_ BU_  "NmhNode" ENUM  "No","Yes";
BA_DEF_ BU_  "NodeLayerModules" STRING ;
BA_DEF_ BU_  "GenNodSleepTime" INT 0 1000000;
BA_DEF_ BU_  "GenNodAutoGenSnd" ENUM  "Yes","No";
BA_DEF_ BU_  "GenNodAutoGenDsp" ENUM  "Yes","No";
BA_DEF_ BU_  "VAGTP20_TargetAddress" HEX 0 127;
BA_DEF_ BO_  "VAGTP20_API" HEX 0 255;
BA_DEF_ BO_  "VAGTP20_StatConnection" ENUM  "No","Yes";
BA_DEF_ BO_  "VAGTP20_DynConnection" ENUM  "No","Yes";
BA_DEF_ BO_  "VAGTP20_DynSetup" ENUM  "No","Yes";
BA_DEF_ BO_  "NmMessage" ENUM  "No","Yes";
BA_DEF_ BO_  "NmhMessage" ENUM  "No","Yes";
BA_DEF_ BO_  "GenMsgCycleTime" INT 0 65535;
BA_DEF_ BO_  "GenMsgSendType" ENUM  "cyclicX","spontanX","cyclicIfActiveX","spontanWithDelay","cyclicAndSpontanX","cyclicAndSpontanWithDelay","spontanWithRepitition","cyclicIfActiveAndSpontanWD","NoMsgSendType","cyclicWithRepeatOnDemand";
BA_DEF_ BO_  "GenMsgCycleTimeFast" INT 0 65535;
BA_DEF_ BO_  "GenMsgNrOfRepetition" INT 0 255;
BA_DEF_ BO_  "GenMsgDelayTime" INT 0 100000;
BA_DEF_ BO_  "GenMsgILSupport" ENUM  "No","Yes";
BA_DEF_ BO_  "GenMsgTimeoutTime" INT 0 100000;
BA_DEF_ BO_  "GenMsgAutoGenDsp" ENUM  "No","Yes";
BA_DEF_ BO_  "GenMsgAutoGenSnd" ENUM  "No","Yes";
BA_DEF_ BO_  "DiagRequest" ENUM  "No","Yes";
BA_DEF_ BO_  "DiagResponse" ENUM  "No","Yes";
BA_DEF_ BO_  "DiagState" ENUM  "No","Yes";
BA_DEF_ SG_  "GenSigSendType" ENUM  "Cyclic","OnWrite","OnWriteWithRepetition","OnChange","OnChangeWithRepetition","IfActive","IfActiveWithRepetition","NoSigSendType";
BA_DEF_ SG_  "GenSigStartValue" INT 0 4294967295;
BA_DEF_ SG_  "GenSigInactiveValue" INT 0 2147483647;
BA_DEF_ SG_  "GenSigAutoGenDsp" ENUM  "No","Yes";
BA_DEF_ SG_  "GenSigAutoGenSnd" ENUM  "No","Yes";
BA_DEF_ SG_  "GenSigEnvVarType" STRING ;
BA_DEF_ SG_  "GenSigFuncType" ENUM  "NoFunction","MsgCounter","CRC-8","XOR","XOR-2","DatedBit","SW-Kl15","CHK","Constant","Protokoll";
BA_DEF_ SG_  "NWM-WakeUpAllowed" ENUM  "No","Yes";
BA_DEF_ SG_  "INIT" STRING ;
BA_DEF_ SG_  "GenSigTimeoutMsg_Airbag" HEX 0 2047;
BA_DEF_ SG_  "GenSigTimeoutTime_Airbag" INT 0 65535;
BA_DEF_ SG_  "GenSigTimeoutMsg_Allrad" HEX 0 2047;
BA_DEF_ SG_  "GenSigTimeoutTime_Allrad" INT 0 65535;
BA_DEF_ SG_  "GenSigTimeoutMsg_Lenkhilfe_ZF_2" HEX 0 2047;
BA_DEF_ SG_  "GenSigTimeoutTime_Lenkhilfe_ZF_2" INT 0 65535;
BA_DEF_ SG_  "GenSigTimeoutMsg_Teves_MK60_ESP" HEX 0 2047;
BA_DEF_ SG_  "GenSigTimeoutTime_Teves_MK60_ESP" INT 0 65535;
BA_DEF_ SG_  "GenSigTimeoutMsg_LWS" HEX 0 2047;
BA_DEF_ SG_  "GenSigTimeoutTime_LWS" INT 0 65535;
BA_DEF_ SG_  "GenSigTimeoutMsg_LWR" HEX 0 2047;
BA_DEF_ SG_  "GenSigTimeoutTime_LWR" INT 0 65535;
BA_DEF_ SG_  "GenSigTimeoutMsg_Teves_MK70_MAB" HEX 0 2047;
BA_DEF_ SG_  "GenSigTimeoutTime_Teves_MK70_MAB" INT 0 65535;
BA_DEF_ SG_  "GenSigTimeoutMsg_Waehlhebel" HEX 0 2047;
BA_DEF_ SG_  "GenSigTimeoutTime_Waehlhebel" INT 0 65535;
BA_DEF_ SG_  "GenSigTimeoutMsg_EPB" HEX 0 2047;
BA_DEF_ SG_  "GenSigTimeoutTime_EPB" INT 0 65535;
BA_DEF_ SG_  "GenSigTimeoutMsg_TRW_ESP" HEX 0 2047;
BA_DEF_ SG_  "GenSigTimeoutTime_TRW_ESP" INT 0 65535;
BA_DEF_ SG_  "GenSigTimeoutMsg_ACC_Radar" HEX 0 2047;
BA_DEF_ SG_  "GenSigTimeoutTime_ACC_Radar" INT 0 65535;
BA_DEF_ SG_  "GenSigTimeoutMsg_AFS" HEX 0 2047;
BA_DEF_ SG_  "GenSigTimeoutTime_AFS" INT 0 65535;
BA_DEF_ SG_  "GenSigTimeoutMsg_Magne_Ride" HEX 0 2047;
BA_DEF_ SG_  "GenSigTimeoutTime_Magne_Ride" INT 0 65535;
BA_DEF_ SG_  "GenSigTimeoutMsg_RKA_Plus" HEX 0 2047;
BA_DEF_ SG_  "GenSigTimeoutTime_RKA_Plus" INT 0 65535;
BA_DEF_ SG_  "GenSigTimeoutMsg_Selespeed" HEX 0 2047;
BA_DEF_ SG_  "GenSigTimeoutTime_Selespeed" INT 0 65535;
BA_DEF_ SG_  "GenSigTimeoutMsg_Waehlhebel_Sel" HEX 0 2047;
BA_DEF_ SG_  "GenSigTimeoutTime_Waehlhebel_Sel" INT 0 65535;
BA_DEF_ SG_  "GenSigTimeoutMsg_PDC_PLA" HEX 0 2047;
BA_DEF_ SG_  "GenSigTimeoutTime_PDC_PLA" INT 0 65535;
BA_DEF_ SG_  "GenSigTimeoutMsg_Lenkhilfe_APA" HEX 0 2047;
BA_DEF_ SG_  "GenSigTimeoutTime_Lenkhilfe_APA" INT 0 65535;
BA_DEF_ SG_  "GenSigTimeoutMsg_VAQ" HEX 0 2047;
BA_DEF_ SG_  "GenSigTimeoutTime_VAQ" INT 0 65535;
BA_DEF_ SG_  "GenSigTimeoutMsg_Daempfer" HEX 0 2047;
BA_DEF_ SG_  "GenSigTimeoutTime_Daempfer" INT 0 65535;
BA_DEF_ SG_  "GenSigTimeoutMsg_Hybrid_BMS" HEX 0 2047;
BA_DEF_ SG_  "GenSigTimeoutTime_Hybrid_BMS" INT 0 65535;
BA_DEF_ SG_  "GenSigTimeoutMsg_Hybrid_PWR" HEX 0 2047;
BA_DEF_ SG_  "GenSigTimeoutTime_Hybrid_PWR" INT 0 65535;
BA_DEF_ SG_  "GenSigTimeoutMsg_Hybrid_DQ200" HEX 0 2047;
BA_DEF_ SG_  "GenSigTimeoutTime_Hybrid_DQ200" INT 0 65535;
BA_DEF_ SG_  "GenSigTimeoutMsg_EKlimakomp" HEX 0 2047;
BA_DEF_ SG_  "GenSigTimeoutTime_EKlimakomp" INT 0 65535;
BA_DEF_ SG_  "GenSigTimeoutMsg_SWA" HEX 0 2047;
BA_DEF_ SG_  "GenSigTimeoutTime_SWA" INT 0 65535;
BA_DEF_ SG_  "GenSigTimeoutMsg_HCA" HEX 0 2047;
BA_DEF_ SG_  "GenSigTimeoutTime_HCA" INT 0 65535;
BA_DEF_ SG_  "GenSigTimeoutMsg_ACC_Lidar" HEX 0 2047;
BA_DEF_ SG_  "GenSigTimeoutTime_ACC_Lidar" INT 0 65535;
BA_DEF_ SG_  "GenSigTimeoutMsg_Lenkhilfe_ZF_3" HEX 0 2047;
BA_DEF_ SG_  "GenSigTimeoutTime_Lenkhilfe_ZF_3" INT 0 65535;
BA_DEF_ SG_  "GenSigTimeoutMsg_FLA" HEX 0 2047;
BA_DEF_ SG_  "GenSigTimeoutTime_FLA" INT 0 65535;
BA_DEF_ SG_  "GenSigTimeoutMsg_AG6" HEX 0 2047;
BA_DEF_ SG_  "GenSigTimeoutTime_AG6" INT 0 65535;
BA_DEF_ SG_  "GenSigTimeoutMsg_DQ" HEX 0 2047;
BA_DEF_ SG_  "GenSigTimeoutTime_DQ" INT 0 65535;
BA_DEF_ SG_  "GenSigTimeoutMsg_Hybrid_MSG" HEX 0 2047;
BA_DEF_ SG_  "GenSigTimeoutTime_Hybrid_MSG" INT 0 65535;
BA_DEF_ SG_  "GenSigTimeoutMsg_Diesel" HEX 0 2047;
BA_DEF_ SG_  "GenSigTimeoutTime_Diesel" INT 0 65535;
BA_DEF_ SG_  "GenSigTimeoutMsg_Otto" HEX 0 2047;
BA_DEF_ SG_  "GenSigTimeoutTime_Otto" INT 0 65535;
BA_DEF_ SG_  "GenSigTimeoutMsg_Gateway_PQ35_A" HEX 0 2047;
BA_DEF_ SG_  "GenSigTimeoutTime_Gateway_PQ35_A" INT 0 65535;
BA_DEF_ SG_  "GenSigTimeoutMsg_Gateway_PQ46_A" HEX 0 2047;
BA_DEF_ SG_  "GenSigTimeoutTime_Gateway_PQ46_A" INT 0 65535;
BA_DEF_DEF_  "NmType" "None";
BA_DEF_DEF_  "NmBaseAddress" 1024;
BA_DEF_DEF_  "NmhBaseAddress" 1824;
BA_DEF_DEF_  "Manufacturer" "VAG";
BA_DEF_DEF_  "NmMessageCount" 64;
BA_DEF_DEF_  "NmhMessageCount" 32;
BA_DEF_DEF_  "NmStationAddress" 0;
BA_DEF_DEF_  "NmNode" "No";
BA_DEF_DEF_  "NmhNode" "No";
BA_DEF_DEF_  "NodeLayerModules" "";
BA_DEF_DEF_  "GenNodSleepTime" 5000;
BA_DEF_DEF_  "GenNodAutoGenSnd" "Yes";
BA_DEF_DEF_  "GenNodAutoGenDsp" "Yes";
BA_DEF_DEF_  "VAGTP20_TargetAddress" 0;
BA_DEF_DEF_  "VAGTP20_API" 0;
BA_DEF_DEF_  "VAGTP20_StatConnection" "No";
BA_DEF_DEF_  "VAGTP20_DynConnection" "No";
BA_DEF_DEF_  "VAGTP20_DynSetup" "No";
BA_DEF_DEF_  "NmMessage" "No";
BA_DEF_DEF_  "NmhMessage" "No";
BA_DEF_DEF_  "GenMsgCycleTime" 0;
BA_DEF_DEF_  "GenMsgSendType" "NoMsgSendType";
BA_DEF_DEF_  "GenMsgCycleTimeFast" 0;
BA_DEF_DEF_  "GenMsgNrOfRepetition" 0;
BA_DEF_DEF_  "GenMsgDelayTime" 0;
BA_DEF_DEF_  "GenMsgILSupport" "No";
BA_DEF_DEF_  "GenMsgTimeoutTime" 0;
BA_DEF_DEF_  "GenMsgAutoGenDsp" "Yes";
BA_DEF_DEF_  "GenMsgAutoGenSnd" "Yes";
BA_DEF_DEF_  "DiagRequest" "No";
BA_DEF_DEF_  "DiagResponse" "No";
BA_DEF_DEF_  "DiagState" "No";
BA_DEF_DEF_  "GenSigSendType" "NoSigSendType";
BA_DEF_DEF_  "GenSigStartValue" 0;
BA_DEF_DEF_  "GenSigInactiveValue" 0;
BA_DEF_DEF_  "GenSigAutoGenDsp" "Yes";
BA_DEF_DEF_  "GenSigAutoGenSnd" "Yes";
BA_DEF_DEF_  "GenSigEnvVarType" "Undef";
BA_DEF_DEF_  "GenSigFuncType" "NoFunction";
BA_DEF_DEF_  "NWM-WakeUpAllowed" "No";
BA_DEF_DEF_  "INIT" "";
BA_DEF_DEF_  "GenSigTimeoutMsg_Airbag" 0;
BA_DEF_DEF_  "GenSigTimeoutTime_Airbag" 0;
BA_DEF_DEF_  "GenSigTimeoutMsg_Allrad" 0;
BA_DEF_DEF_  "GenSigTimeoutTime_Allrad" 0;
BA_DEF_DEF_  "GenSigTimeoutMsg_Lenkhilfe_ZF_2" 0;
BA_DEF_DEF_  "GenSigTimeoutTime_Lenkhilfe_ZF_2" 0;
BA_DEF_DEF_  "GenSigTimeoutMsg_Teves_MK60_ESP" 0;
BA_DEF_DEF_  "GenSigTimeoutTime_Teves_MK60_ESP" 0;
BA_DEF_DEF_  "GenSigTimeoutMsg_LWS" 0;
BA_DEF_DEF_  "GenSigTimeoutTime_LWS" 0;
BA_DEF_DEF_  "GenSigTimeoutMsg_LWR" 0;
BA_DEF_DEF_  "GenSigTimeoutTime_LWR" 0;
BA_DEF_DEF_  "GenSigTimeoutMsg_Teves_MK70_MAB" 0;
BA_DEF_DEF_  "GenSigTimeoutTime_Teves_MK70_MAB" 0;
BA_DEF_DEF_  "GenSigTimeoutMsg_Waehlhebel" 0;
BA_DEF_DEF_  "GenSigTimeoutTime_Waehlhebel" 0;
BA_DEF_DEF_  "GenSigTimeoutMsg_EPB" 0;
BA_DEF_DEF_  "GenSigTimeoutTime_EPB" 0;
BA_DEF_DEF_  "GenSigTimeoutMsg_TRW_ESP" 0;
BA_DEF_DEF_  "GenSigTimeoutTime_TRW_ESP" 0;
BA_DEF_DEF_  "GenSigTimeoutMsg_ACC_Radar" 0;
BA_DEF_DEF_  "GenSigTimeoutTime_ACC_Radar" 0;
BA_DEF_DEF_  "GenSigTimeoutMsg_AFS" 0;
BA_DEF_DEF_  "GenSigTimeoutTime_AFS" 0;
BA_DEF_DEF_  "GenSigTimeoutMsg_Magne_Ride" 0;
BA_DEF_DEF_  "GenSigTimeoutTime_Magne_Ride" 0;
BA_DEF_DEF_  "GenSigTimeoutMsg_RKA_Plus" 0;
BA_DEF_DEF_  "GenSigTimeoutTime_RKA_Plus" 0;
BA_DEF_DEF_  "GenSigTimeoutMsg_Selespeed" 0;
BA_DEF_DEF_  "GenSigTimeoutTime_Selespeed" 0;
BA_DEF_DEF_  "GenSigTimeoutMsg_Waehlhebel_Sel" 0;
BA_DEF_DEF_  "GenSigTimeoutTime_Waehlhebel_Sel" 0;
BA_DEF_DEF_  "GenSigTimeoutMsg_PDC_PLA" 0;
BA_DEF_DEF_  "GenSigTimeoutTime_PDC_PLA" 0;
BA_DEF_DEF_  "GenSigTimeoutMsg_Lenkhilfe_APA" 0;
BA_DEF_DEF_  "GenSigTimeoutTime_Lenkhilfe_APA" 0;
BA_DEF_DEF_  "GenSigTimeoutMsg_VAQ" 0;
BA_DEF_DEF_  "GenSigTimeoutTime_VAQ" 0;
BA_DEF_DEF_  "GenSigTimeoutMsg_Daempfer" 0;
BA_DEF_DEF_  "GenSigTimeoutTime_Daempfer" 0;
BA_DEF_DEF_  "GenSigTimeoutMsg_Hybrid_BMS" 0;
BA_DEF_DEF_  "GenSigTimeoutTime_Hybrid_BMS" 0;
BA_DEF_DEF_  "GenSigTimeoutMsg_Hybrid_PWR" 0;
BA_DEF_DEF_  "GenSigTimeoutTime_Hybrid_PWR" 0;
BA_DEF_DEF_  "GenSigTimeoutMsg_Hybrid_DQ200" 0;
BA_DEF_DEF_  "GenSigTimeoutTime_Hybrid_DQ200" 0;
BA_DEF_DEF_  "GenSigTimeoutMsg_EKlimakomp" 0;
BA_DEF_DEF_  "GenSigTimeoutTime_EKlimakomp" 0;
BA_DEF_DEF_  "GenSigTimeoutMsg_SWA" 0;
BA_DEF_DEF_  "GenSigTimeoutTime_SWA" 0;
BA_DEF_DEF_  "GenSigTimeoutMsg_HCA" 0;
BA_DEF_DEF_  "GenSigTimeoutTime_HCA" 0;
BA_DEF_DEF_  "GenSigTimeoutMsg_ACC_Lidar" 0;
BA_DEF_DEF_  "GenSigTimeoutTime_ACC_Lidar" 0;
BA_DEF_DEF_  "GenSigTimeoutMsg_Lenkhilfe_ZF_3" 0;
BA_DEF_DEF_  "GenSigTimeoutTime_Lenkhilfe_ZF_3" 0;
BA_DEF_DEF_  "GenSigTimeoutMsg_FLA" 0;
BA_DEF_DEF_  "GenSigTimeoutTime_FLA" 0;
BA_DEF_DEF_  "GenSigTimeoutMsg_AG6" 0;
BA_DEF_DEF_  "GenSigTimeoutTime_AG6" 0;
BA_DEF_DEF_  "GenSigTimeoutMsg_DQ" 0;
BA_DEF_DEF_  "GenSigTimeoutTime_DQ" 0;
BA_DEF_DEF_  "GenSigTimeoutMsg_Hybrid_MSG" 0;
BA_DEF_DEF_  "GenSigTimeoutTime_Hybrid_MSG" 0;
BA_DEF_DEF_  "GenSigTimeoutMsg_Diesel" 0;
BA_DEF_DEF_  "GenSigTimeoutTime_Diesel" 0;
BA_DEF_DEF_  "GenSigTimeoutMsg_Otto" 0;
BA_DEF_DEF_  "GenSigTimeoutTime_Otto" 0;
BA_DEF_DEF_  "GenSigTimeoutMsg_Gateway_PQ35_A" 0;
BA_DEF_DEF_  "GenSigTimeoutTime_Gateway_PQ35_A" 0;
BA_DEF_DEF_  "GenSigTimeoutMsg_Gateway_PQ46_A" 0;
BA_DEF_DEF_  "GenSigTimeoutTime_Gateway_PQ46_A" 0;
BA_ "NmType" "NM-High";
BA_ "VAGTP20_TargetAddress" BU_ Airbag 5;
BA_ "NodeLayerModules" BU_ Airbag "CANoeILNLVAG.dll";
BA_ "VAGTP20_TargetAddress" BU_ Allrad 10;
BA_ "NodeLayerModules" BU_ Allrad "CANoeILNLVAG.dll";
BA_ "VAGTP20_TargetAddress" BU_ EPS 9;
BA_ "NodeLayerModules" BU_ EPS "CANoeILNLVAG.dll";
BA_ "VAGTP20_TargetAddress" BU_ Teves_MK60_ESP 3;
BA_ "NodeLayerModules" BU_ Teves_MK60_ESP "CANoeILNLVAG.dll,NMHigh.dll";
BA_ "NmhNode" BU_ Teves_MK60_ESP 1;
BA_ "VAGTP20_TargetAddress" BU_ LWS 19;
BA_ "NodeLayerModules" BU_ LWS "CANoeILNLVAG.dll";
BA_ "VAGTP20_TargetAddress" BU_ LWR 6;
BA_ "NodeLayerModules" BU_ LWR "CANoeILNLVAG.dll";
BA_ "VAGTP20_TargetAddress" BU_ Teves_MK70_MABS 3;
BA_ "NodeLayerModules" BU_ Teves_MK70_MABS "CANoeILNLVAG.dll,NMHigh.dll";
BA_ "NmhNode" BU_ Teves_MK70_MABS 1;
BA_ "NodeLayerModules" BU_ Waehlhebel "CANoeILNLVAG.dll";
BA_ "VAGTP20_TargetAddress" BU_ EPB 25;
BA_ "NodeLayerModules" BU_ EPB "CANoeILNLVAG.dll";
BA_ "VAGTP20_TargetAddress" BU_ TRW_ESP 3;
BA_ "NodeLayerModules" BU_ TRW_ESP "CANoeILNLVAG.dll,NMHigh.dll";
BA_ "NmhNode" BU_ TRW_ESP 1;
BA_ "VAGTP20_TargetAddress" BU_ ACC_Radar 11;
BA_ "NodeLayerModules" BU_ ACC_Radar "CANoeILNLVAG.dll";
BA_ "VAGTP20_TargetAddress" BU_ AFS 6;
BA_ "NodeLayerModules" BU_ AFS "CANoeILNLVAG.dll";
BA_ "VAGTP20_TargetAddress" BU_ Magne_Ride 12;
BA_ "NodeLayerModules" BU_ Magne_Ride "CANoeILNLVAG.dll";
BA_ "VAGTP20_TargetAddress" BU_ RKA_Plus 8;
BA_ "NodeLayerModules" BU_ RKA_Plus "CANoeILNLVAG.dll";
BA_ "VAGTP20_TargetAddress" BU_ Selespeed 2;
BA_ "NodeLayerModules" BU_ Selespeed "CANoeILNLVAG.dll";
BA_ "NodeLayerModules" BU_ Waehlhebel_Sele "CANoeILNLVAG.dll";
BA_ "VAGTP20_TargetAddress" BU_ PDC_PLA 29;
BA_ "NodeLayerModules" BU_ PDC_PLA "CANoeILNLVAG.dll";
BA_ "VAGTP20_TargetAddress" BU_ Lenkhilfe_APA 9;
BA_ "NodeLayerModules" BU_ Lenkhilfe_APA "CANoeILNLVAG.dll";
BA_ "VAGTP20_TargetAddress" BU_ VAQ 24;
BA_ "NodeLayerModules" BU_ VAQ "CANoeILNLVAG.dll";
BA_ "VAGTP20_TargetAddress" BU_ Daempfer 12;
BA_ "NodeLayerModules" BU_ Daempfer "CANoeILNLVAG.dll";
BA_ "NodeLayerModules" BU_ Hybrid_BMS "CANoeILNLVAG.dll";
BA_ "NodeLayerModules" BU_ Hybrid_PWR "CANoeILNLVAG.dll";
BA_ "VAGTP20_TargetAddress" BU_ Hybrid_DQ200 2;
BA_ "NodeLayerModules" BU_ Hybrid_DQ200 "CANoeILNLVAG.dll";
BA_ "NodeLayerModules" BU_ EKlimakomp "CANoeILNLVAG.dll";
BA_ "VAGTP20_TargetAddress" BU_ SWA 28;
BA_ "NodeLayerModules" BU_ SWA "CANoeILNLVAG.dll";
BA_ "VAGTP20_TargetAddress" BU_ HCA 26;
BA_ "NodeLayerModules" BU_ HCA "CANoeILNLVAG.dll";
BA_ "NodeLayerModules" BU_ ACC_Lidar "CANoeILNLVAG.dll";
BA_ "NodeLayerModules" BU_ Lenkhilfe_ZF_3G "CANoeILNLVAG.dll";
BA_ "VAGTP20_TargetAddress" BU_ FLA 22;
BA_ "NodeLayerModules" BU_ FLA "CANoeILNLVAG.dll";
BA_ "VAGTP20_TargetAddress" BU_ AG6 2;
BA_ "NodeLayerModules" BU_ AG6 "CANoeILNLVAG.dll";
BA_ "VAGTP20_TargetAddress" BU_ DQ 2;
BA_ "NodeLayerModules" BU_ DQ "CANoeILNLVAG.dll";
BA_ "VAGTP20_TargetAddress" BU_ Hybrid_MSG 1;
BA_ "NodeLayerModules" BU_ Hybrid_MSG "CANoeILNLVAG.dll";
BA_ "VAGTP20_TargetAddress" BU_ Diesel 1;
BA_ "NodeLayerModules" BU_ Diesel "CANoeILNLVAG.dll";
BA_ "VAGTP20_TargetAddress" BU_ Otto 1;
BA_ "NodeLayerModules" BU_ Otto "CANoeILNLVAG.dll";
BA_ "NodeLayerModules" BU_ Gateway_PQ35_A "CANoeILNLVAG.dll,NMHigh.dll";
BA_ "NmhNode" BU_ Gateway_PQ35_A 1;
BA_ "NodeLayerModules" BU_ Gateway_PQ46_A "CANoeILNLVAG.dll,NMHigh.dll";
BA_ "NmhNode" BU_ Gateway_PQ46_A 1;
BA_ "GenMsgTimeoutTime" BO_ 80 500;
BA_ "GenMsgSendType" BO_ 80 5;
BA_ "GenMsgCycleTime" BO_ 80 20;
BA_ "GenMsgTimeoutTime" BO_ 1360 2000;
BA_ "GenMsgSendType" BO_ 1360 0;
BA_ "GenMsgCycleTime" BO_ 1360 200;
BA_ "GenMsgSendType" BO_ 517 1;
BA_ "VAGTP20_DynSetup" BO_ 517 1;
BA_ "GenMsgTimeoutTime" BO_ 1524 5000;
BA_ "GenMsgSendType" BO_ 1524 0;
BA_ "GenMsgCycleTime" BO_ 1524 1000;
BA_ "DiagResponse" BO_ 1919 1;
BA_ "GenMsgSendType" BO_ 1919 1;
BA_ "GenMsgSendType" BO_ 2041 1;
BA_ "GenMsgSendType" BO_ 522 1;
BA_ "VAGTP20_DynSetup" BO_ 522 1;
BA_ "GenMsgTimeoutTime" BO_ 704 500;
BA_ "GenMsgSendType" BO_ 704 0;
BA_ "GenMsgCycleTime" BO_ 704 10;
BA_ "GenMsgTimeoutTime" BO_ 978 500;
BA_ "GenMsgSendType" BO_ 978 0;
BA_ "GenMsgCycleTime" BO_ 978 50;
BA_ "GenMsgTimeoutTime" BO_ 976 500;
BA_ "GenMsgSendType" BO_ 976 0;
BA_ "GenMsgCycleTime" BO_ 976 20;
BA_ "GenMsgSendType" BO_ 521 1;
BA_ "VAGTP20_DynSetup" BO_ 521 1;
BA_ "GenMsgTimeoutTime" BO_ 208 500;
BA_ "GenMsgSendType" BO_ 208 0;
BA_ "GenMsgCycleTime" BO_ 208 10;
BA_ "GenMsgTimeoutTime" BO_ 416 500;
BA_ "GenMsgSendType" BO_ 416 0;
BA_ "GenMsgCycleTime" BO_ 416 10;
BA_ "GenMsgTimeoutTime" BO_ 1440 500;
BA_ "GenMsgSendType" BO_ 1440 0;
BA_ "GenMsgCycleTime" BO_ 1440 20;
BA_ "GenSigSendType" SG_ 3221225472 AL1_Begrenzungsmo 0;
BA_ "GenSigStartValue" SG_ 3221225472 AL1_Begrenzungsmo 254;
BA_ "GenSigSendType" SG_ 3221225472 BR2_Sta_BrAssi 0;
BA_ "GenSigSendType" SG_ 3221225472 BR2_Zeitstemp 0;
BA_ "GenSigSendType" SG_ 3221225472 BR2_TTic_Skal 0;
BA_ "GenSigSendType" SG_ 3221225472 BR2_Querb_TTic 0;
BA_ "GenSigStartValue" SG_ 3221225472 BR2_Querb_TTic 1;
BA_ "GenSigSendType" SG_ 3221225472 EP1_Verschleiss 0;
BA_ "INIT" SG_ 3221225472 EP1_Verschleiss "alt";
BA_ "GenSigTimeoutTime_TRW_ESP" SG_ 3221225472 GE1_Code_MSG 500;
BA_ "GenSigTimeoutMsg_TRW_ESP" SG_ 3221225472 GE1_Code_MSG 1088;
BA_ "GenSigTimeoutTime_Diesel" SG_ 3221225472 GE1_Code_MSG 500;
BA_ "GenSigTimeoutMsg_Diesel" SG_ 3221225472 GE1_Code_MSG 1088;
BA_ "GenSigSendType" SG_ 3221225472 GE1_Code_MSG 0;
BA_ "GenSigSendType" SG_ 3221225472 GE1_v_halten 0;
BA_ "GenSigSendType" SG_ 3221225472 GE1_Mrad_Mk2 0;
BA_ "GenSigSendType" SG_ 3221225472 GH1_FreigabeSSK0 0;
BA_ "GenSigSendType" SG_ 3221225472 LDW_res_24 0;
BA_ "GenSigSendType" SG_ 3221225472 LDW_res_25 0;
BA_ "GenSigSendType" SG_ 3221225472 LDW_res_26 0;
BA_ "GenSigSendType" SG_ 3221225472 LDW_res_28 0;
BA_ "GenSigSendType" SG_ 3221225472 LDW_res_29 0;
BA_ "GenSigSendType" SG_ 3221225472 LDW_res_30 0;
BA_ "GenSigSendType" SG_ 3221225472 LDW_res_31 0;
BA_ "GenSigSendType" SG_ 3221225472 LDW_res_32 0;
BA_ "GenSigSendType" SG_ 3221225472 LDW_res_33 0;
BA_ "GenSigSendType" SG_ 3221225472 LDW_res_34 0;
BA_ "GenSigSendType" SG_ 3221225472 LDW_res_27 0;
BA_ "GenSigSendType" SG_ 3221225472 LDW_res_37 0;
BA_ "GenSigSendType" SG_ 3221225472 LDW_res_38 0;
BA_ "GenSigSendType" SG_ 3221225472 LDW_res_39 0;
BA_ "GenSigSendType" SG_ 3221225472 LDW_res_35 0;
BA_ "GenSigSendType" SG_ 3221225472 LDW_res_40 0;
BA_ "GenSigSendType" SG_ 3221225472 LDW_res_36 0;
BA_ "GenSigSendType" SG_ 3221225472 LDW_res_42 0;
BA_ "GenSigSendType" SG_ 3221225472 LDW_res_43 0;
BA_ "GenSigSendType" SG_ 3221225472 LDW_res_44 0;
BA_ "GenSigSendType" SG_ 3221225472 LDW_res_41 0;
BA_ "GenSigSendType" SG_ 3221225472 LDW_res_45 0;
BA_ "GenSigSendType" SG_ 3221225472 LDW_res_46 0;
BA_ "GenSigSendType" SG_ 3221225472 LDW_res_47 0;
BA_ "GenSigSendType" SG_ 3221225472 LDW_res_48 0;
BA_ "GenSigSendType" SG_ 3221225472 LDW_res_49 0;
BA_ "GenSigSendType" SG_ 3221225472 LDW_res_51 0;
BA_ "GenSigSendType" SG_ 3221225472 LDW_res_52 0;
BA_ "GenSigSendType" SG_ 3221225472 LDW_res_53 0;
BA_ "GenSigSendType" SG_ 3221225472 LDW_res_54 0;
BA_ "GenSigSendType" SG_ 3221225472 LDW_res_50 0;
BA_ "GenSigSendType" SG_ 3221225472 LDW_res_55 0;
BA_ "GenSigSendType" SG_ 3221225472 LDW_res_56 0;
BA_ "GenSigSendType" SG_ 3221225472 LDW_res_57 0;
BA_ "GenSigSendType" SG_ 3221225472 LDW_res_59 0;
BA_ "GenSigSendType" SG_ 3221225472 LDW_res_60 0;
BA_ "GenSigSendType" SG_ 3221225472 LDW_res_62 0;
BA_ "GenSigSendType" SG_ 3221225472 LDW_res_61 0;
BA_ "GenSigSendType" SG_ 3221225472 LDW_res_63 0;
BA_ "GenSigSendType" SG_ 3221225472 LDW_res_58 0;
BA_ "GenSigSendType" SG_ 3221225472 MO2_Freigabe_Sport 0;
BA_ "GenSigSendType" SG_ 3221225472 MO7_Ladedruck 0;
BA_ "GenSigSendType" SG_ 3221225472 KO1_Warn_Heiss 0;
BA_ "GenSigSendType" SG_ 3221225472 KO2_AussT_FehArt 0;
BA_ "GenSigSendType" SG_ 3221225472 KO2_Sta_KuehlT 0;
BA_ "INIT" SG_ 3221225472 KO2_Sta_KuehlT "0/1";
BA_ "GenSigSendType" SG_ 3221225472 KO2_Sta_Oel_T 0;
BA_ "INIT" SG_ 3221225472 KO2_Sta_Oel_T "0/1";
BA_ "GenSigSendType" SG_ 3221225472 GK1_RDWarn_VL 0;
BA_ "GenSigSendType" SG_ 3221225472 GK1_RDWarn_VR 0;
BA_ "GenSigSendType" SG_ 3221225472 GK1_RDWarn_HR 0;
BA_ "GenSigSendType" SG_ 3221225472 GK1_RDWarn_Res 0;
BA_ "GenSigSendType" SG_ 3221225472 GK1_RDWarn_HL 0;
BA_ "GenSigSendType" SG_ 3221225472 GK1_RDWarn_1 0;
BA_ "GenSigSendType" SG_ 3221225472 GK1_RDK_System 0;
BA_ "GenSigSendType" SG_ 3221225472 GK1_RDWarn_2 0;
BA_ "GenSigSendType" SG_ 3221225472 BSL_DFM 0;
BA_ "GenSigSendType" SG_ 3221225472 BSL_U_Start_BATT 0;
BA_ "GenSigTimeoutTime_Teves_MK60_ESP" SG_ 80 AB1_Front 500;
BA_ "GenSigTimeoutMsg_Teves_MK60_ESP" SG_ 80 AB1_Front 80;
BA_ "GenSigTimeoutTime_SWA" SG_ 80 AB1_Front 500;
BA_ "GenSigTimeoutMsg_SWA" SG_ 80 AB1_Front 80;
BA_ "GenSigTimeoutTime_HCA" SG_ 80 AB1_Front 500;
BA_ "GenSigTimeoutMsg_HCA" SG_ 80 AB1_Front 80;
BA_ "GenSigTimeoutTime_Hybrid_MSG" SG_ 80 AB1_Front 500;
BA_ "GenSigTimeoutMsg_Hybrid_MSG" SG_ 80 AB1_Front 80;
BA_ "GenSigTimeoutTime_Hybrid_BMS" SG_ 80 AB1_Front 500;
BA_ "GenSigTimeoutMsg_Hybrid_BMS" SG_ 80 AB1_Front 80;
BA_ "GenSigTimeoutTime_Hybrid_PWR" SG_ 80 AB1_Front 500;
BA_ "GenSigTimeoutMsg_Hybrid_PWR" SG_ 80 AB1_Front 80;
BA_ "GenSigTimeoutTime_Gateway_PQ35_A" SG_ 80 AB1_Front 500;
BA_ "GenSigTimeoutMsg_Gateway_PQ35_A" SG_ 80 AB1_Front 80;
BA_ "GenSigTimeoutTime_TRW_ESP" SG_ 80 AB1_Front 500;
BA_ "GenSigTimeoutMsg_TRW_ESP" SG_ 80 AB1_Front 80;
BA_ "GenSigTimeoutTime_EPB" SG_ 80 AB1_Front 500;
BA_ "GenSigTimeoutMsg_EPB" SG_ 80 AB1_Front 80;
BA_ "GenSigTimeoutTime_Diesel" SG_ 80 AB1_Front 500;
BA_ "GenSigTimeoutMsg_Diesel" SG_ 80 AB1_Front 80;
BA_ "GenSigTimeoutTime_Gateway_PQ46_A" SG_ 80 AB1_Front 500;
BA_ "GenSigTimeoutMsg_Gateway_PQ46_A" SG_ 80 AB1_Front 80;
BA_ "GenSigSendType" SG_ 80 AB1_Front 3;
BA_ "GenSigTimeoutTime_Teves_MK60_ESP" SG_ 80 AB1_Heck 500;
BA_ "GenSigTimeoutMsg_Teves_MK60_ESP" SG_ 80 AB1_Heck 80;
BA_ "GenSigTimeoutTime_SWA" SG_ 80 AB1_Heck 500;
BA_ "GenSigTimeoutMsg_SWA" SG_ 80 AB1_Heck 80;
BA_ "GenSigTimeoutTime_HCA" SG_ 80 AB1_Heck 500;
BA_ "GenSigTimeoutMsg_HCA" SG_ 80 AB1_Heck 80;
BA_ "GenSigTimeoutTime_Hybrid_MSG" SG_ 80 AB1_Heck 500;
BA_ "GenSigTimeoutMsg_Hybrid_MSG" SG_ 80 AB1_Heck 80;
BA_ "GenSigTimeoutTime_Hybrid_BMS" SG_ 80 AB1_Heck 500;
BA_ "GenSigTimeoutMsg_Hybrid_BMS" SG_ 80 AB1_Heck 80;
BA_ "GenSigTimeoutTime_Hybrid_PWR" SG_ 80 AB1_Heck 500;
BA_ "GenSigTimeoutMsg_Hybrid_PWR" SG_ 80 AB1_Heck 80;
BA_ "GenSigTimeoutTime_Gateway_PQ35_A" SG_ 80 AB1_Heck 500;
BA_ "GenSigTimeoutMsg_Gateway_PQ35_A" SG_ 80 AB1_Heck 80;
BA_ "GenSigTimeoutTime_TRW_ESP" SG_ 80 AB1_Heck 500;
BA_ "GenSigTimeoutMsg_TRW_ESP" SG_ 80 AB1_Heck 80;
BA_ "GenSigTimeoutTime_EPB" SG_ 80 AB1_Heck 500;
BA_ "GenSigTimeoutMsg_EPB" SG_ 80 AB1_Heck 80;
BA_ "GenSigTimeoutTime_Diesel" SG_ 80 AB1_Heck 500;
BA_ "GenSigTimeoutMsg_Diesel" SG_ 80 AB1_Heck 80;
BA_ "GenSigTimeoutTime_Gateway_PQ46_A" SG_ 80 AB1_Heck 500;
BA_ "GenSigTimeoutMsg_Gateway_PQ46_A" SG_ 80 AB1_Heck 80;
BA_ "GenSigSendType" SG_ 80 AB1_Heck 3;
BA_ "GenSigTimeoutTime_Teves_MK60_ESP" SG_ 80 AB1_Fa_Seite 500;
BA_ "GenSigTimeoutMsg_Teves_MK60_ESP" SG_ 80 AB1_Fa_Seite 80;
BA_ "GenSigTimeoutTime_SWA" SG_ 80 AB1_Fa_Seite 500;
BA_ "GenSigTimeoutMsg_SWA" SG_ 80 AB1_Fa_Seite 80;
BA_ "GenSigTimeoutTime_HCA" SG_ 80 AB1_Fa_Seite 500;
BA_ "GenSigTimeoutMsg_HCA" SG_ 80 AB1_Fa_Seite 80;
BA_ "GenSigTimeoutTime_Hybrid_MSG" SG_ 80 AB1_Fa_Seite 500;
BA_ "GenSigTimeoutMsg_Hybrid_MSG" SG_ 80 AB1_Fa_Seite 80;
BA_ "GenSigTimeoutTime_Hybrid_BMS" SG_ 80 AB1_Fa_Seite 500;
BA_ "GenSigTimeoutMsg_Hybrid_BMS" SG_ 80 AB1_Fa_Seite 80;
BA_ "GenSigTimeoutTime_Hybrid_PWR" SG_ 80 AB1_Fa_Seite 500;
BA_ "GenSigTimeoutMsg_Hybrid_PWR" SG_ 80 AB1_Fa_Seite 80;
BA_ "GenSigTimeoutTime_Gateway_PQ35_A" SG_ 80 AB1_Fa_Seite 500;
BA_ "GenSigTimeoutMsg_Gateway_PQ35_A" SG_ 80 AB1_Fa_Seite 80;
BA_ "GenSigTimeoutTime_TRW_ESP" SG_ 80 AB1_Fa_Seite 500;
BA_ "GenSigTimeoutMsg_TRW_ESP" SG_ 80 AB1_Fa_Seite 80;
BA_ "GenSigTimeoutTime_EPB" SG_ 80 AB1_Fa_Seite 500;
BA_ "GenSigTimeoutMsg_EPB" SG_ 80 AB1_Fa_Seite 80;
BA_ "GenSigTimeoutTime_Diesel" SG_ 80 AB1_Fa_Seite 500;
BA_ "GenSigTimeoutMsg_Diesel" SG_ 80 AB1_Fa_Seite 80;
BA_ "GenSigTimeoutTime_Gateway_PQ46_A" SG_ 80 AB1_Fa_Seite 500;
BA_ "GenSigTimeoutMsg_Gateway_PQ46_A" SG_ 80 AB1_Fa_Seite 80;
BA_ "GenSigSendType" SG_ 80 AB1_Fa_Seite 3;
BA_ "GenSigTimeoutTime_Teves_MK60_ESP" SG_ 80 AB1_Bf_Seite 500;
BA_ "GenSigTimeoutMsg_Teves_MK60_ESP" SG_ 80 AB1_Bf_Seite 80;
BA_ "GenSigTimeoutTime_SWA" SG_ 80 AB1_Bf_Seite 500;
BA_ "GenSigTimeoutMsg_SWA" SG_ 80 AB1_Bf_Seite 80;
BA_ "GenSigTimeoutTime_HCA" SG_ 80 AB1_Bf_Seite 500;
BA_ "GenSigTimeoutMsg_HCA" SG_ 80 AB1_Bf_Seite 80;
BA_ "GenSigTimeoutTime_Hybrid_MSG" SG_ 80 AB1_Bf_Seite 500;
BA_ "GenSigTimeoutMsg_Hybrid_MSG" SG_ 80 AB1_Bf_Seite 80;
BA_ "GenSigTimeoutTime_Hybrid_BMS" SG_ 80 AB1_Bf_Seite 500;
BA_ "GenSigTimeoutMsg_Hybrid_BMS" SG_ 80 AB1_Bf_Seite 80;
BA_ "GenSigTimeoutTime_Hybrid_PWR" SG_ 80 AB1_Bf_Seite 500;
BA_ "GenSigTimeoutMsg_Hybrid_PWR" SG_ 80 AB1_Bf_Seite 80;
BA_ "GenSigTimeoutTime_Gateway_PQ35_A" SG_ 80 AB1_Bf_Seite 500;
BA_ "GenSigTimeoutMsg_Gateway_PQ35_A" SG_ 80 AB1_Bf_Seite 80;
BA_ "GenSigTimeoutTime_TRW_ESP" SG_ 80 AB1_Bf_Seite 500;
BA_ "GenSigTimeoutMsg_TRW_ESP" SG_ 80 AB1_Bf_Seite 80;
BA_ "GenSigTimeoutTime_EPB" SG_ 80 AB1_Bf_Seite 500;
BA_ "GenSigTimeoutMsg_EPB" SG_ 80 AB1_Bf_Seite 80;
BA_ "GenSigTimeoutTime_Diesel" SG_ 80 AB1_Bf_Seite 500;
BA_ "GenSigTimeoutMsg_Diesel" SG_ 80 AB1_Bf_Seite 80;
BA_ "GenSigTimeoutTime_Gateway_PQ46_A" SG_ 80 AB1_Bf_Seite 500;
BA_ "GenSigTimeoutMsg_Gateway_PQ46_A" SG_ 80 AB1_Bf_Seite 80;
BA_ "GenSigSendType" SG_ 80 AB1_Bf_Seite 3;
BA_ "GenSigTimeoutTime_HCA" SG_ 80 AB1_Rollover 500;
BA_ "GenSigTimeoutMsg_HCA" SG_ 80 AB1_Rollover 80;
BA_ "GenSigTimeoutTime_Hybrid_MSG" SG_ 80 AB1_Rollover 500;
BA_ "GenSigTimeoutMsg_Hybrid_MSG" SG_ 80 AB1_Rollover 80;
BA_ "GenSigTimeoutTime_Hybrid_BMS" SG_ 80 AB1_Rollover 500;
BA_ "GenSigTimeoutMsg_Hybrid_BMS" SG_ 80 AB1_Rollover 80;
BA_ "GenSigTimeoutTime_Hybrid_PWR" SG_ 80 AB1_Rollover 500;
BA_ "GenSigTimeoutMsg_Hybrid_PWR" SG_ 80 AB1_Rollover 80;
BA_ "GenSigTimeoutTime_Gateway_PQ35_A" SG_ 80 AB1_Rollover 500;
BA_ "GenSigTimeoutMsg_Gateway_PQ35_A" SG_ 80 AB1_Rollover 80;
BA_ "GenSigTimeoutTime_TRW_ESP" SG_ 80 AB1_Rollover 500;
BA_ "GenSigTimeoutMsg_TRW_ESP" SG_ 80 AB1_Rollover 80;
BA_ "GenSigTimeoutTime_EPB" SG_ 80 AB1_Rollover 500;
BA_ "GenSigTimeoutMsg_EPB" SG_ 80 AB1_Rollover 80;
BA_ "GenSigTimeoutTime_Teves_MK70_MAB" SG_ 80 AB1_Rollover 500;
BA_ "GenSigTimeoutMsg_Teves_MK70_MAB" SG_ 80 AB1_Rollover 80;
BA_ "GenSigTimeoutTime_Teves_MK60_ESP" SG_ 80 AB1_Rollover 500;
BA_ "GenSigTimeoutMsg_Teves_MK60_ESP" SG_ 80 AB1_Rollover 80;
BA_ "GenSigTimeoutTime_Diesel" SG_ 80 AB1_Rollover 500;
BA_ "GenSigTimeoutMsg_Diesel" SG_ 80 AB1_Rollover 80;
BA_ "GenSigTimeoutTime_Gateway_PQ46_A" SG_ 80 AB1_Rollover 500;
BA_ "GenSigTimeoutMsg_Gateway_PQ46_A" SG_ 80 AB1_Rollover 80;
BA_ "GenSigSendType" SG_ 80 AB1_Rollover 3;
BA_ "GenSigTimeoutTime_Teves_MK60_ESP" SG_ 80 AB1_Status 500;
BA_ "GenSigTimeoutMsg_Teves_MK60_ESP" SG_ 80 AB1_Status 80;
BA_ "GenSigTimeoutTime_HCA" SG_ 80 AB1_Status 500;
BA_ "GenSigTimeoutMsg_HCA" SG_ 80 AB1_Status 80;
BA_ "GenSigTimeoutTime_Hybrid_PWR" SG_ 80 AB1_Status 500;
BA_ "GenSigTimeoutMsg_Hybrid_PWR" SG_ 80 AB1_Status 80;
BA_ "GenSigTimeoutTime_Hybrid_MSG" SG_ 80 AB1_Status 500;
BA_ "GenSigTimeoutMsg_Hybrid_MSG" SG_ 80 AB1_Status 80;
BA_ "GenSigTimeoutTime_Hybrid_BMS" SG_ 80 AB1_Status 500;
BA_ "GenSigTimeoutMsg_Hybrid_BMS" SG_ 80 AB1_Status 80;
BA_ "GenSigTimeoutTime_Gateway_PQ35_A" SG_ 80 AB1_Status 500;
BA_ "GenSigTimeoutMsg_Gateway_PQ35_A" SG_ 80 AB1_Status 80;
BA_ "GenSigTimeoutTime_TRW_ESP" SG_ 80 AB1_Status 500;
BA_ "GenSigTimeoutMsg_TRW_ESP" SG_ 80 AB1_Status 80;
BA_ "GenSigTimeoutTime_EPB" SG_ 80 AB1_Status 500;
BA_ "GenSigTimeoutMsg_EPB" SG_ 80 AB1_Status 80;
BA_ "GenSigTimeoutTime_Gateway_PQ46_A" SG_ 80 AB1_Status 500;
BA_ "GenSigTimeoutMsg_Gateway_PQ46_A" SG_ 80 AB1_Status 80;
BA_ "GenSigSendType" SG_ 80 AB1_Status 0;
BA_ "GenSigTimeoutTime_Teves_MK60_ESP" SG_ 80 AB1_Lampe 500;
BA_ "GenSigTimeoutMsg_Teves_MK60_ESP" SG_ 80 AB1_Lampe 80;
BA_ "GenSigTimeoutTime_HCA" SG_ 80 AB1_Lampe 500;
BA_ "GenSigTimeoutMsg_HCA" SG_ 80 AB1_Lampe 80;
BA_ "GenSigTimeoutTime_Hybrid_MSG" SG_ 80 AB1_Lampe 500;
BA_ "GenSigTimeoutMsg_Hybrid_MSG" SG_ 80 AB1_Lampe 80;
BA_ "GenSigTimeoutTime_Hybrid_BMS" SG_ 80 AB1_Lampe 500;
BA_ "GenSigTimeoutMsg_Hybrid_BMS" SG_ 80 AB1_Lampe 80;
BA_ "GenSigTimeoutTime_Hybrid_PWR" SG_ 80 AB1_Lampe 500;
BA_ "GenSigTimeoutMsg_Hybrid_PWR" SG_ 80 AB1_Lampe 80;
BA_ "GenSigTimeoutTime_Gateway_PQ35_A" SG_ 80 AB1_Lampe 500;
BA_ "GenSigTimeoutMsg_Gateway_PQ35_A" SG_ 80 AB1_Lampe 80;
BA_ "GenSigTimeoutTime_TRW_ESP" SG_ 80 AB1_Lampe 500;
BA_ "GenSigTimeoutMsg_TRW_ESP" SG_ 80 AB1_Lampe 80;
BA_ "GenSigTimeoutTime_EPB" SG_ 80 AB1_Lampe 500;
BA_ "GenSigTimeoutMsg_EPB" SG_ 80 AB1_Lampe 80;
BA_ "GenSigTimeoutTime_Gateway_PQ46_A" SG_ 80 AB1_Lampe 500;
BA_ "GenSigTimeoutMsg_Gateway_PQ46_A" SG_ 80 AB1_Lampe 80;
BA_ "GenSigSendType" SG_ 80 AB1_Lampe 0;
BA_ "GenSigStartValue" SG_ 80 AB1_Lampe 1;
BA_ "GenSigTimeoutTime_Teves_MK60_ESP" SG_ 80 AB1_Beifahrer 500;
BA_ "GenSigTimeoutMsg_Teves_MK60_ESP" SG_ 80 AB1_Beifahrer 80;
BA_ "GenSigTimeoutTime_HCA" SG_ 80 AB1_Beifahrer 500;
BA_ "GenSigTimeoutMsg_HCA" SG_ 80 AB1_Beifahrer 80;
BA_ "GenSigTimeoutTime_Hybrid_MSG" SG_ 80 AB1_Beifahrer 500;
BA_ "GenSigTimeoutMsg_Hybrid_MSG" SG_ 80 AB1_Beifahrer 80;
BA_ "GenSigTimeoutTime_Hybrid_PWR" SG_ 80 AB1_Beifahrer 500;
BA_ "GenSigTimeoutMsg_Hybrid_PWR" SG_ 80 AB1_Beifahrer 80;
BA_ "GenSigTimeoutTime_Hybrid_BMS" SG_ 80 AB1_Beifahrer 500;
BA_ "GenSigTimeoutMsg_Hybrid_BMS" SG_ 80 AB1_Beifahrer 80;
BA_ "GenSigTimeoutTime_Gateway_PQ35_A" SG_ 80 AB1_Beifahrer 500;
BA_ "GenSigTimeoutMsg_Gateway_PQ35_A" SG_ 80 AB1_Beifahrer 80;
BA_ "GenSigTimeoutTime_TRW_ESP" SG_ 80 AB1_Beifahrer 500;
BA_ "GenSigTimeoutMsg_TRW_ESP" SG_ 80 AB1_Beifahrer 80;
BA_ "GenSigTimeoutTime_EPB" SG_ 80 AB1_Beifahrer 500;
BA_ "GenSigTimeoutMsg_EPB" SG_ 80 AB1_Beifahrer 80;
BA_ "GenSigTimeoutTime_Gateway_PQ46_A" SG_ 80 AB1_Beifahrer 500;
BA_ "GenSigTimeoutMsg_Gateway_PQ46_A" SG_ 80 AB1_Beifahrer 80;
BA_ "GenSigSendType" SG_ 80 AB1_Beifahrer 0;
BA_ "GenSigStartValue" SG_ 80 AB1_Beifahrer 1;
BA_ "GenSigTimeoutTime_Teves_MK60_ESP" SG_ 80 AB1_System 500;
BA_ "GenSigTimeoutMsg_Teves_MK60_ESP" SG_ 80 AB1_System 80;
BA_ "GenSigTimeoutTime_HCA" SG_ 80 AB1_System 500;
BA_ "GenSigTimeoutMsg_HCA" SG_ 80 AB1_System 80;
BA_ "GenSigTimeoutTime_Hybrid_MSG" SG_ 80 AB1_System 500;
BA_ "GenSigTimeoutMsg_Hybrid_MSG" SG_ 80 AB1_System 80;
BA_ "GenSigTimeoutTime_Hybrid_BMS" SG_ 80 AB1_System 500;
BA_ "GenSigTimeoutMsg_Hybrid_BMS" SG_ 80 AB1_System 80;
BA_ "GenSigTimeoutTime_Hybrid_PWR" SG_ 80 AB1_System 500;
BA_ "GenSigTimeoutMsg_Hybrid_PWR" SG_ 80 AB1_System 80;
BA_ "GenSigTimeoutTime_Gateway_PQ35_A" SG_ 80 AB1_System 500;
BA_ "GenSigTimeoutMsg_Gateway_PQ35_A" SG_ 80 AB1_System 80;
BA_ "GenSigTimeoutTime_TRW_ESP" SG_ 80 AB1_System 500;
BA_ "GenSigTimeoutMsg_TRW_ESP" SG_ 80 AB1_System 80;
BA_ "GenSigTimeoutTime_EPB" SG_ 80 AB1_System 500;
BA_ "GenSigTimeoutMsg_EPB" SG_ 80 AB1_System 80;
BA_ "GenSigTimeoutTime_Gateway_PQ46_A" SG_ 80 AB1_System 500;
BA_ "GenSigTimeoutMsg_Gateway_PQ46_A" SG_ 80 AB1_System 80;
BA_ "GenSigSendType" SG_ 80 AB1_System 0;
BA_ "GenSigTimeoutTime_Otto" SG_ 80 AB1_Gurt_Fa 500;
BA_ "GenSigTimeoutMsg_Otto" SG_ 80 AB1_Gurt_Fa 80;
BA_ "GenSigTimeoutTime_Diesel" SG_ 80 AB1_Gurt_Fa 500;
BA_ "GenSigTimeoutMsg_Diesel" SG_ 80 AB1_Gurt_Fa 80;
BA_ "GenSigTimeoutTime_Teves_MK60_ESP" SG_ 80 AB1_Gurt_Fa 500;
BA_ "GenSigTimeoutMsg_Teves_MK60_ESP" SG_ 80 AB1_Gurt_Fa 80;
BA_ "GenSigTimeoutTime_HCA" SG_ 80 AB1_Gurt_Fa 500;
BA_ "GenSigTimeoutMsg_HCA" SG_ 80 AB1_Gurt_Fa 80;
BA_ "GenSigTimeoutTime_Hybrid_PWR" SG_ 80 AB1_Gurt_Fa 500;
BA_ "GenSigTimeoutMsg_Hybrid_PWR" SG_ 80 AB1_Gurt_Fa 80;
BA_ "GenSigTimeoutTime_Hybrid_MSG" SG_ 80 AB1_Gurt_Fa 500;
BA_ "GenSigTimeoutMsg_Hybrid_MSG" SG_ 80 AB1_Gurt_Fa 80;
BA_ "GenSigTimeoutTime_Hybrid_BMS" SG_ 80 AB1_Gurt_Fa 500;
BA_ "GenSigTimeoutMsg_Hybrid_BMS" SG_ 80 AB1_Gurt_Fa 80;
BA_ "GenSigTimeoutTime_Gateway_PQ35_A" SG_ 80 AB1_Gurt_Fa 500;
BA_ "GenSigTimeoutMsg_Gateway_PQ35_A" SG_ 80 AB1_Gurt_Fa 80;
BA_ "GenSigTimeoutTime_TRW_ESP" SG_ 80 AB1_Gurt_Fa 500;
BA_ "GenSigTimeoutMsg_TRW_ESP" SG_ 80 AB1_Gurt_Fa 80;
BA_ "GenSigTimeoutTime_EPB" SG_ 80 AB1_Gurt_Fa 500;
BA_ "GenSigTimeoutMsg_EPB" SG_ 80 AB1_Gurt_Fa 80;
BA_ "GenSigTimeoutTime_Gateway_PQ46_A" SG_ 80 AB1_Gurt_Fa 500;
BA_ "GenSigTimeoutMsg_Gateway_PQ46_A" SG_ 80 AB1_Gurt_Fa 80;
BA_ "GenSigSendType" SG_ 80 AB1_Gurt_Fa 0;
BA_ "GenSigTimeoutTime_Teves_MK60_ESP" SG_ 80 AB1_Gurt_Bf 500;
BA_ "GenSigTimeoutMsg_Teves_MK60_ESP" SG_ 80 AB1_Gurt_Bf 80;
BA_ "GenSigTimeoutTime_HCA" SG_ 80 AB1_Gurt_Bf 500;
BA_ "GenSigTimeoutMsg_HCA" SG_ 80 AB1_Gurt_Bf 80;
BA_ "GenSigTimeoutTime_Hybrid_PWR" SG_ 80 AB1_Gurt_Bf 500;
BA_ "GenSigTimeoutMsg_Hybrid_PWR" SG_ 80 AB1_Gurt_Bf 80;
BA_ "GenSigTimeoutTime_Hybrid_MSG" SG_ 80 AB1_Gurt_Bf 500;
BA_ "GenSigTimeoutMsg_Hybrid_MSG" SG_ 80 AB1_Gurt_Bf 80;
BA_ "GenSigTimeoutTime_Hybrid_BMS" SG_ 80 AB1_Gurt_Bf 500;
BA_ "GenSigTimeoutMsg_Hybrid_BMS" SG_ 80 AB1_Gurt_Bf 80;
BA_ "GenSigTimeoutTime_Gateway_PQ35_A" SG_ 80 AB1_Gurt_Bf 500;
BA_ "GenSigTimeoutMsg_Gateway_PQ35_A" SG_ 80 AB1_Gurt_Bf 80;
BA_ "GenSigTimeoutTime_TRW_ESP" SG_ 80 AB1_Gurt_Bf 500;
BA_ "GenSigTimeoutMsg_TRW_ESP" SG_ 80 AB1_Gurt_Bf 80;
BA_ "GenSigTimeoutTime_EPB" SG_ 80 AB1_Gurt_Bf 500;
BA_ "GenSigTimeoutMsg_EPB" SG_ 80 AB1_Gurt_Bf 80;
BA_ "GenSigTimeoutTime_Gateway_PQ46_A" SG_ 80 AB1_Gurt_Bf 500;
BA_ "GenSigTimeoutMsg_Gateway_PQ46_A" SG_ 80 AB1_Gurt_Bf 80;
BA_ "GenSigSendType" SG_ 80 AB1_Gurt_Bf 0;
BA_ "GenSigTimeoutTime_Otto" SG_ 80 AB1_Stellglied 500;
BA_ "GenSigTimeoutMsg_Otto" SG_ 80 AB1_Stellglied 80;
BA_ "GenSigTimeoutTime_Teves_MK60_ESP" SG_ 80 AB1_Stellglied 500;
BA_ "GenSigTimeoutMsg_Teves_MK60_ESP" SG_ 80 AB1_Stellglied 80;
BA_ "GenSigTimeoutTime_HCA" SG_ 80 AB1_Stellglied 500;
BA_ "GenSigTimeoutMsg_HCA" SG_ 80 AB1_Stellglied 80;
BA_ "GenSigTimeoutTime_Hybrid_MSG" SG_ 80 AB1_Stellglied 500;
BA_ "GenSigTimeoutMsg_Hybrid_MSG" SG_ 80 AB1_Stellglied 80;
BA_ "GenSigTimeoutTime_Hybrid_PWR" SG_ 80 AB1_Stellglied 500;
BA_ "GenSigTimeoutMsg_Hybrid_PWR" SG_ 80 AB1_Stellglied 80;
BA_ "GenSigTimeoutTime_Hybrid_BMS" SG_ 80 AB1_Stellglied 500;
BA_ "GenSigTimeoutMsg_Hybrid_BMS" SG_ 80 AB1_Stellglied 80;
BA_ "GenSigTimeoutTime_Gateway_PQ35_A" SG_ 80 AB1_Stellglied 500;
BA_ "GenSigTimeoutMsg_Gateway_PQ35_A" SG_ 80 AB1_Stellglied 80;
BA_ "GenSigTimeoutTime_TRW_ESP" SG_ 80 AB1_Stellglied 500;
BA_ "GenSigTimeoutMsg_TRW_ESP" SG_ 80 AB1_Stellglied 80;
BA_ "GenSigTimeoutTime_EPB" SG_ 80 AB1_Stellglied 500;
BA_ "GenSigTimeoutMsg_EPB" SG_ 80 AB1_Stellglied 80;
BA_ "GenSigTimeoutTime_Diesel" SG_ 80 AB1_Stellglied 500;
BA_ "GenSigTimeoutMsg_Diesel" SG_ 80 AB1_Stellglied 80;
BA_ "GenSigTimeoutTime_Gateway_PQ46_A" SG_ 80 AB1_Stellglied 500;
BA_ "GenSigTimeoutMsg_Gateway_PQ46_A" SG_ 80 AB1_Stellglied 80;
BA_ "GenSigSendType" SG_ 80 AB1_Stellglied 0;
BA_ "GenSigTimeoutTime_Teves_MK60_ESP" SG_ 80 AB1_BF_Warnung 500;
BA_ "GenSigTimeoutMsg_Teves_MK60_ESP" SG_ 80 AB1_BF_Warnung 80;
BA_ "GenSigTimeoutTime_HCA" SG_ 80 AB1_BF_Warnung 500;
BA_ "GenSigTimeoutMsg_HCA" SG_ 80 AB1_BF_Warnung 80;
BA_ "GenSigTimeoutTime_Hybrid_MSG" SG_ 80 AB1_BF_Warnung 500;
BA_ "GenSigTimeoutMsg_Hybrid_MSG" SG_ 80 AB1_BF_Warnung 80;
BA_ "GenSigTimeoutTime_Hybrid_PWR" SG_ 80 AB1_BF_Warnung 500;
BA_ "GenSigTimeoutMsg_Hybrid_PWR" SG_ 80 AB1_BF_Warnung 80;
BA_ "GenSigTimeoutTime_Hybrid_BMS" SG_ 80 AB1_BF_Warnung 500;
BA_ "GenSigTimeoutMsg_Hybrid_BMS" SG_ 80 AB1_BF_Warnung 80;
BA_ "GenSigTimeoutTime_Gateway_PQ35_A" SG_ 80 AB1_BF_Warnung 500;
BA_ "GenSigTimeoutMsg_Gateway_PQ35_A" SG_ 80 AB1_BF_Warnung 80;
BA_ "GenSigTimeoutTime_TRW_ESP" SG_ 80 AB1_BF_Warnung 500;
BA_ "GenSigTimeoutMsg_TRW_ESP" SG_ 80 AB1_BF_Warnung 80;
BA_ "GenSigTimeoutTime_EPB" SG_ 80 AB1_BF_Warnung 500;
BA_ "GenSigTimeoutMsg_EPB" SG_ 80 AB1_BF_Warnung 80;
BA_ "GenSigTimeoutTime_Gateway_PQ46_A" SG_ 80 AB1_BF_Warnung 500;
BA_ "GenSigTimeoutMsg_Gateway_PQ46_A" SG_ 80 AB1_BF_Warnung 80;
BA_ "GenSigSendType" SG_ 80 AB1_BF_Warnung 0;
BA_ "GenSigTimeoutTime_Teves_MK60_ESP" SG_ 80 AB1_Diagnose 500;
BA_ "GenSigTimeoutMsg_Teves_MK60_ESP" SG_ 80 AB1_Diagnose 80;
BA_ "GenSigTimeoutTime_EPB" SG_ 80 AB1_Diagnose 500;
BA_ "GenSigTimeoutMsg_EPB" SG_ 80 AB1_Diagnose 80;
BA_ "GenSigTimeoutTime_TRW_ESP" SG_ 80 AB1_Diagnose 500;
BA_ "GenSigTimeoutMsg_TRW_ESP" SG_ 80 AB1_Diagnose 80;
BA_ "GenSigTimeoutTime_Hybrid_BMS" SG_ 80 AB1_Diagnose 500;
BA_ "GenSigTimeoutMsg_Hybrid_BMS" SG_ 80 AB1_Diagnose 80;
BA_ "GenSigTimeoutTime_Hybrid_PWR" SG_ 80 AB1_Diagnose 500;
BA_ "GenSigTimeoutMsg_Hybrid_PWR" SG_ 80 AB1_Diagnose 80;
BA_ "GenSigTimeoutTime_HCA" SG_ 80 AB1_Diagnose 500;
BA_ "GenSigTimeoutMsg_HCA" SG_ 80 AB1_Diagnose 80;
BA_ "GenSigTimeoutTime_Hybrid_MSG" SG_ 80 AB1_Diagnose 500;
BA_ "GenSigTimeoutMsg_Hybrid_MSG" SG_ 80 AB1_Diagnose 80;
BA_ "GenSigTimeoutTime_Gateway_PQ35_A" SG_ 80 AB1_Diagnose 500;
BA_ "GenSigTimeoutMsg_Gateway_PQ35_A" SG_ 80 AB1_Diagnose 80;
BA_ "GenSigTimeoutTime_Gateway_PQ46_A" SG_ 80 AB1_Diagnose 500;
BA_ "GenSigTimeoutMsg_Gateway_PQ46_A" SG_ 80 AB1_Diagnose 80;
BA_ "GenSigSendType" SG_ 80 AB1_Diagnose 0;
BA_ "GenSigTimeoutTime_Teves_MK60_ESP" SG_ 80 AB1_Zaehler 500;
BA_ "GenSigTimeoutMsg_Teves_MK60_ESP" SG_ 80 AB1_Zaehler 80;
BA_ "GenSigTimeoutTime_HCA" SG_ 80 AB1_Zaehler 500;
BA_ "GenSigTimeoutMsg_HCA" SG_ 80 AB1_Zaehler 80;
BA_ "GenSigTimeoutTime_Hybrid_BMS" SG_ 80 AB1_Zaehler 500;
BA_ "GenSigTimeoutMsg_Hybrid_BMS" SG_ 80 AB1_Zaehler 80;
BA_ "GenSigTimeoutTime_Hybrid_PWR" SG_ 80 AB1_Zaehler 500;
BA_ "GenSigTimeoutMsg_Hybrid_PWR" SG_ 80 AB1_Zaehler 80;
BA_ "GenSigTimeoutTime_Hybrid_MSG" SG_ 80 AB1_Zaehler 500;
BA_ "GenSigTimeoutMsg_Hybrid_MSG" SG_ 80 AB1_Zaehler 80;
BA_ "GenSigTimeoutTime_Gateway_PQ35_A" SG_ 80 AB1_Zaehler 500;
BA_ "GenSigTimeoutMsg_Gateway_PQ35_A" SG_ 80 AB1_Zaehler 80;
BA_ "GenSigTimeoutTime_TRW_ESP" SG_ 80 AB1_Zaehler 500;
BA_ "GenSigTimeoutMsg_TRW_ESP" SG_ 80 AB1_Zaehler 80;
BA_ "GenSigTimeoutTime_EPB" SG_ 80 AB1_Zaehler 500;
BA_ "GenSigTimeoutMsg_EPB" SG_ 80 AB1_Zaehler 80;
BA_ "GenSigTimeoutTime_Otto" SG_ 80 AB1_Zaehler 500;
BA_ "GenSigTimeoutMsg_Otto" SG_ 80 AB1_Zaehler 80;
BA_ "GenSigTimeoutTime_Diesel" SG_ 80 AB1_Zaehler 500;
BA_ "GenSigTimeoutMsg_Diesel" SG_ 80 AB1_Zaehler 80;
BA_ "GenSigTimeoutTime_Gateway_PQ46_A" SG_ 80 AB1_Zaehler 500;
BA_ "GenSigTimeoutMsg_Gateway_PQ46_A" SG_ 80 AB1_Zaehler 80;
BA_ "GenSigSendType" SG_ 80 AB1_Zaehler 0;
BA_ "GenSigTimeoutTime_SWA" SG_ 80 AB1_Intens 500;
BA_ "GenSigTimeoutMsg_SWA" SG_ 80 AB1_Intens 80;
BA_ "GenSigTimeoutTime_HCA" SG_ 80 AB1_Intens 500;
BA_ "GenSigTimeoutMsg_HCA" SG_ 80 AB1_Intens 80;
BA_ "GenSigTimeoutTime_Hybrid_BMS" SG_ 80 AB1_Intens 500;
BA_ "GenSigTimeoutMsg_Hybrid_BMS" SG_ 80 AB1_Intens 80;
BA_ "GenSigTimeoutTime_Hybrid_PWR" SG_ 80 AB1_Intens 500;
BA_ "GenSigTimeoutMsg_Hybrid_PWR" SG_ 80 AB1_Intens 80;
BA_ "GenSigTimeoutTime_Hybrid_MSG" SG_ 80 AB1_Intens 500;
BA_ "GenSigTimeoutMsg_Hybrid_MSG" SG_ 80 AB1_Intens 80;
BA_ "GenSigTimeoutTime_Gateway_PQ35_A" SG_ 80 AB1_Intens 500;
BA_ "GenSigTimeoutMsg_Gateway_PQ35_A" SG_ 80 AB1_Intens 80;
BA_ "GenSigTimeoutTime_TRW_ESP" SG_ 80 AB1_Intens 500;
BA_ "GenSigTimeoutMsg_TRW_ESP" SG_ 80 AB1_Intens 80;
BA_ "GenSigTimeoutTime_EPB" SG_ 80 AB1_Intens 500;
BA_ "GenSigTimeoutMsg_EPB" SG_ 80 AB1_Intens 80;
BA_ "GenSigTimeoutTime_Teves_MK70_MAB" SG_ 80 AB1_Intens 500;
BA_ "GenSigTimeoutMsg_Teves_MK70_MAB" SG_ 80 AB1_Intens 80;
BA_ "GenSigTimeoutTime_Teves_MK60_ESP" SG_ 80 AB1_Intens 500;
BA_ "GenSigTimeoutMsg_Teves_MK60_ESP" SG_ 80 AB1_Intens 80;
BA_ "GenSigTimeoutTime_Otto" SG_ 80 AB1_Intens 500;
BA_ "GenSigTimeoutMsg_Otto" SG_ 80 AB1_Intens 80;
BA_ "GenSigTimeoutTime_Diesel" SG_ 80 AB1_Intens 500;
BA_ "GenSigTimeoutMsg_Diesel" SG_ 80 AB1_Intens 80;
BA_ "GenSigTimeoutTime_Gateway_PQ46_A" SG_ 80 AB1_Intens 500;
BA_ "GenSigTimeoutMsg_Gateway_PQ46_A" SG_ 80 AB1_Intens 80;
BA_ "GenSigSendType" SG_ 80 AB1_Intens 3;
BA_ "GenSigTimeoutTime_Teves_MK60_ESP" SG_ 80 AB1_Fehlereintr 500;
BA_ "GenSigTimeoutMsg_Teves_MK60_ESP" SG_ 80 AB1_Fehlereintr 80;
BA_ "GenSigTimeoutTime_HCA" SG_ 80 AB1_Fehlereintr 500;
BA_ "GenSigTimeoutMsg_HCA" SG_ 80 AB1_Fehlereintr 80;
BA_ "GenSigTimeoutTime_Hybrid_MSG" SG_ 80 AB1_Fehlereintr 500;
BA_ "GenSigTimeoutMsg_Hybrid_MSG" SG_ 80 AB1_Fehlereintr 80;
BA_ "GenSigTimeoutTime_Hybrid_PWR" SG_ 80 AB1_Fehlereintr 500;
BA_ "GenSigTimeoutMsg_Hybrid_PWR" SG_ 80 AB1_Fehlereintr 80;
BA_ "GenSigTimeoutTime_Hybrid_BMS" SG_ 80 AB1_Fehlereintr 500;
BA_ "GenSigTimeoutMsg_Hybrid_BMS" SG_ 80 AB1_Fehlereintr 80;
BA_ "GenSigTimeoutTime_Gateway_PQ35_A" SG_ 80 AB1_Fehlereintr 500;
BA_ "GenSigTimeoutMsg_Gateway_PQ35_A" SG_ 80 AB1_Fehlereintr 80;
BA_ "GenSigTimeoutTime_TRW_ESP" SG_ 80 AB1_Fehlereintr 500;
BA_ "GenSigTimeoutMsg_TRW_ESP" SG_ 80 AB1_Fehlereintr 80;
BA_ "GenSigTimeoutTime_EPB" SG_ 80 AB1_Fehlereintr 500;
BA_ "GenSigTimeoutMsg_EPB" SG_ 80 AB1_Fehlereintr 80;
BA_ "GenSigTimeoutTime_Gateway_PQ46_A" SG_ 80 AB1_Fehlereintr 500;
BA_ "GenSigTimeoutMsg_Gateway_PQ46_A" SG_ 80 AB1_Fehlereintr 80;
BA_ "GenSigSendType" SG_ 80 AB1_Fehlereintr 0;
BA_ "GenSigTimeoutTime_Teves_MK60_ESP" SG_ 80 AB1_Checksumme 500;
BA_ "GenSigTimeoutMsg_Teves_MK60_ESP" SG_ 80 AB1_Checksumme 80;
BA_ "GenSigTimeoutTime_HCA" SG_ 80 AB1_Checksumme 500;
BA_ "GenSigTimeoutMsg_HCA" SG_ 80 AB1_Checksumme 80;
BA_ "GenSigTimeoutTime_Hybrid_BMS" SG_ 80 AB1_Checksumme 500;
BA_ "GenSigTimeoutMsg_Hybrid_BMS" SG_ 80 AB1_Checksumme 80;
BA_ "GenSigTimeoutTime_Hybrid_PWR" SG_ 80 AB1_Checksumme 500;
BA_ "GenSigTimeoutMsg_Hybrid_PWR" SG_ 80 AB1_Checksumme 80;
BA_ "GenSigTimeoutTime_Hybrid_MSG" SG_ 80 AB1_Checksumme 500;
BA_ "GenSigTimeoutMsg_Hybrid_MSG" SG_ 80 AB1_Checksumme 80;
BA_ "GenSigTimeoutTime_Gateway_PQ35_A" SG_ 80 AB1_Checksumme 500;
BA_ "GenSigTimeoutMsg_Gateway_PQ35_A" SG_ 80 AB1_Checksumme 80;
BA_ "GenSigTimeoutTime_TRW_ESP" SG_ 80 AB1_Checksumme 500;
BA_ "GenSigTimeoutMsg_TRW_ESP" SG_ 80 AB1_Checksumme 80;
BA_ "GenSigTimeoutTime_EPB" SG_ 80 AB1_Checksumme 500;
BA_ "GenSigTimeoutMsg_EPB" SG_ 80 AB1_Checksumme 80;
BA_ "GenSigTimeoutTime_Otto" SG_ 80 AB1_Checksumme 500;
BA_ "GenSigTimeoutMsg_Otto" SG_ 80 AB1_Checksumme 80;
BA_ "GenSigTimeoutTime_Diesel" SG_ 80 AB1_Checksumme 500;
BA_ "GenSigTimeoutMsg_Diesel" SG_ 80 AB1_Checksumme 80;
BA_ "GenSigTimeoutTime_Gateway_PQ46_A" SG_ 80 AB1_Checksumme 500;
BA_ "GenSigTimeoutMsg_Gateway_PQ46_A" SG_ 80 AB1_Checksumme 80;
BA_ "GenSigSendType" SG_ 80 AB1_Checksumme 0;
BA_ "INIT" SG_ 80 AB1_Checksumme "CHK";
BA_ "GenSigTimeoutTime_Gateway_PQ35_A" SG_ 1360 AB2_Beleg_HBF 2000;
BA_ "GenSigTimeoutMsg_Gateway_PQ35_A" SG_ 1360 AB2_Beleg_HBF 1360;
BA_ "GenSigTimeoutTime_Gateway_PQ46_A" SG_ 1360 AB2_Beleg_HBF 2000;
BA_ "GenSigTimeoutMsg_Gateway_PQ46_A" SG_ 1360 AB2_Beleg_HBF 1360;
BA_ "GenSigSendType" SG_ 1360 AB2_Beleg_HBF 0;
BA_ "GenSigTimeoutTime_Gateway_PQ35_A" SG_ 1360 AB2_OOP_BF 2000;
BA_ "GenSigTimeoutMsg_Gateway_PQ35_A" SG_ 1360 AB2_OOP_BF 1360;
BA_ "GenSigTimeoutTime_Gateway_PQ46_A" SG_ 1360 AB2_OOP_BF 2000;
BA_ "GenSigTimeoutMsg_Gateway_PQ46_A" SG_ 1360 AB2_OOP_BF 1360;
BA_ "GenSigSendType" SG_ 1360 AB2_OOP_BF 0;
BA_ "GenSigTimeoutTime_Gateway_PQ35_A" SG_ 1360 AB2_Checksum 2000;
BA_ "GenSigTimeoutMsg_Gateway_PQ35_A" SG_ 1360 AB2_Checksum 1360;
BA_ "GenSigTimeoutTime_Gateway_PQ46_A" SG_ 1360 AB2_Checksum 2000;
BA_ "GenSigTimeoutMsg_Gateway_PQ46_A" SG_ 1360 AB2_Checksum 1360;
BA_ "GenSigSendType" SG_ 1360 AB2_Checksum 0;
BA_ "INIT" SG_ 1360 AB2_Checksum "CHK";
BA_ "GenSigTimeoutTime_Gateway_PQ35_A" SG_ 1360 AB2_Beleg_HM 2000;
BA_ "GenSigTimeoutMsg_Gateway_PQ35_A" SG_ 1360 AB2_Beleg_HM 1360;
BA_ "GenSigTimeoutTime_Gateway_PQ46_A" SG_ 1360 AB2_Beleg_HM 2000;
BA_ "GenSigTimeoutMsg_Gateway_PQ46_A" SG_ 1360 AB2_Beleg_HM 1360;
BA_ "GenSigSendType" SG_ 1360 AB2_Beleg_HM 0;
BA_ "GenSigTimeoutTime_Gateway_PQ35_A" SG_ 1360 AB2_Beleg_HF 2000;
BA_ "GenSigTimeoutMsg_Gateway_PQ35_A" SG_ 1360 AB2_Beleg_HF 1360;
BA_ "GenSigTimeoutTime_Gateway_PQ46_A" SG_ 1360 AB2_Beleg_HF 2000;
BA_ "GenSigTimeoutMsg_Gateway_PQ46_A" SG_ 1360 AB2_Beleg_HF 1360;
BA_ "GenSigSendType" SG_ 1360 AB2_Beleg_HF 0;
BA_ "GenSigTimeoutTime_Gateway_PQ35_A" SG_ 1360 AB2_Beleg_BF 2000;
BA_ "GenSigTimeoutMsg_Gateway_PQ35_A" SG_ 1360 AB2_Beleg_BF 1360;
BA_ "GenSigTimeoutTime_Gateway_PQ46_A" SG_ 1360 AB2_Beleg_BF 2000;
BA_ "GenSigTimeoutMsg_Gateway_PQ46_A" SG_ 1360 AB2_Beleg_BF 1360;
BA_ "GenSigSendType" SG_ 1360 AB2_Beleg_BF 0;
BA_ "GenSigTimeoutTime_Gateway_PQ35_A" SG_ 1360 AB2_OOP_Fa 2000;
BA_ "GenSigTimeoutMsg_Gateway_PQ35_A" SG_ 1360 AB2_OOP_Fa 1360;
BA_ "GenSigTimeoutTime_Gateway_PQ46_A" SG_ 1360 AB2_OOP_Fa 2000;
BA_ "GenSigTimeoutMsg_Gateway_PQ46_A" SG_ 1360 AB2_OOP_Fa 1360;
BA_ "GenSigSendType" SG_ 1360 AB2_OOP_Fa 0;
BA_ "GenSigTimeoutTime_Gateway_PQ35_A" SG_ 1360 AB2_Sta_BF 2000;
BA_ "GenSigTimeoutMsg_Gateway_PQ35_A" SG_ 1360 AB2_Sta_BF 1360;
BA_ "GenSigTimeoutTime_Gateway_PQ46_A" SG_ 1360 AB2_Sta_BF 2000;
BA_ "GenSigTimeoutMsg_Gateway_PQ46_A" SG_ 1360 AB2_Sta_BF 1360;
BA_ "GenSigSendType" SG_ 1360 AB2_Sta_BF 0;
BA_ "GenSigTimeoutTime_Gateway_PQ46_A" SG_ 1360 AB2_Gurt_2FaS 2000;
BA_ "GenSigTimeoutMsg_Gateway_PQ46_A" SG_ 1360 AB2_Gurt_2FaS 1360;
BA_ "GenSigTimeoutTime_Gateway_PQ35_A" SG_ 1360 AB2_Gurt_2FaS 2000;
BA_ "GenSigTimeoutMsg_Gateway_PQ35_A" SG_ 1360 AB2_Gurt_2FaS 1360;
BA_ "GenSigSendType" SG_ 1360 AB2_Gurt_2FaS 0;
BA_ "GenSigTimeoutTime_Gateway_PQ46_A" SG_ 1360 AB2_Gurt_2BfS 2000;
BA_ "GenSigTimeoutMsg_Gateway_PQ46_A" SG_ 1360 AB2_Gurt_2BfS 1360;
BA_ "GenSigTimeoutTime_Gateway_PQ35_A" SG_ 1360 AB2_Gurt_2BfS 2000;
BA_ "GenSigTimeoutMsg_Gateway_PQ35_A" SG_ 1360 AB2_Gurt_2BfS 1360;
BA_ "GenSigSendType" SG_ 1360 AB2_Gurt_2BfS 0;
BA_ "GenSigTimeoutTime_Gateway_PQ46_A" SG_ 1360 AB2_Gurt_2Mi 2000;
BA_ "GenSigTimeoutMsg_Gateway_PQ46_A" SG_ 1360 AB2_Gurt_2Mi 1360;
BA_ "GenSigTimeoutTime_Gateway_PQ35_A" SG_ 1360 AB2_Gurt_2Mi 2000;
BA_ "GenSigTimeoutMsg_Gateway_PQ35_A" SG_ 1360 AB2_Gurt_2Mi 1360;
BA_ "GenSigSendType" SG_ 1360 AB2_Gurt_2Mi 0;
BA_ "GenSigTimeoutTime_Gateway_PQ46_A" SG_ 1360 AB2_Gurt_3BfS 2000;
BA_ "GenSigTimeoutMsg_Gateway_PQ46_A" SG_ 1360 AB2_Gurt_3BfS 1360;
BA_ "GenSigTimeoutTime_Gateway_PQ35_A" SG_ 1360 AB2_Gurt_3BfS 2000;
BA_ "GenSigTimeoutMsg_Gateway_PQ35_A" SG_ 1360 AB2_Gurt_3BfS 1360;
BA_ "GenSigSendType" SG_ 1360 AB2_Gurt_3BfS 0;
BA_ "GenSigTimeoutTime_Gateway_PQ46_A" SG_ 1360 AB2_Gurt_3FaS 2000;
BA_ "GenSigTimeoutMsg_Gateway_PQ46_A" SG_ 1360 AB2_Gurt_3FaS 1360;
BA_ "GenSigTimeoutTime_Gateway_PQ35_A" SG_ 1360 AB2_Gurt_3FaS 2000;
BA_ "GenSigTimeoutMsg_Gateway_PQ35_A" SG_ 1360 AB2_Gurt_3FaS 1360;
BA_ "GenSigSendType" SG_ 1360 AB2_Gurt_3FaS 0;
BA_ "GenSigTimeoutTime_Gateway_PQ35_A" SG_ 1360 AB2_Reserve2 2000;
BA_ "GenSigTimeoutMsg_Gateway_PQ35_A" SG_ 1360 AB2_Reserve2 1360;
BA_ "GenSigTimeoutTime_Gateway_PQ46_A" SG_ 1360 AB2_Reserve2 2000;
BA_ "GenSigTimeoutMsg_Gateway_PQ46_A" SG_ 1360 AB2_Reserve2 1360;
BA_ "GenSigSendType" SG_ 1360 AB2_Reserve2 0;
BA_ "GenSigTimeoutTime_Gateway_PQ46_A" SG_ 1360 AB2_Gurt_3Mi 2000;
BA_ "GenSigTimeoutMsg_Gateway_PQ46_A" SG_ 1360 AB2_Gurt_3Mi 1360;
BA_ "GenSigTimeoutTime_Gateway_PQ35_A" SG_ 1360 AB2_Gurt_3Mi 2000;
BA_ "GenSigTimeoutMsg_Gateway_PQ35_A" SG_ 1360 AB2_Gurt_3Mi 1360;
BA_ "GenSigSendType" SG_ 1360 AB2_Gurt_3Mi 0;
BA_ "GenSigTimeoutTime_Gateway_PQ35_A" SG_ 1360 AB2_Reserve3 2000;
BA_ "GenSigTimeoutMsg_Gateway_PQ35_A" SG_ 1360 AB2_Reserve3 1360;
BA_ "GenSigTimeoutTime_Gateway_PQ46_A" SG_ 1360 AB2_Reserve3 2000;
BA_ "GenSigTimeoutMsg_Gateway_PQ46_A" SG_ 1360 AB2_Reserve3 1360;
BA_ "GenSigSendType" SG_ 1360 AB2_Reserve3 0;
BA_ "GenSigTimeoutTime_Gateway_PQ35_A" SG_ 1360 AB2_Reserve4 2000;
BA_ "GenSigTimeoutMsg_Gateway_PQ35_A" SG_ 1360 AB2_Reserve4 1360;
BA_ "GenSigTimeoutTime_Gateway_PQ46_A" SG_ 1360 AB2_Reserve4 2000;
BA_ "GenSigTimeoutMsg_Gateway_PQ46_A" SG_ 1360 AB2_Reserve4 1360;
BA_ "GenSigSendType" SG_ 1360 AB2_Reserve4 0;
BA_ "GenSigTimeoutTime_Gateway_PQ35_A" SG_ 1360 AB2_Reserve5 2000;
BA_ "GenSigTimeoutMsg_Gateway_PQ35_A" SG_ 1360 AB2_Reserve5 1360;
BA_ "GenSigTimeoutTime_Gateway_PQ46_A" SG_ 1360 AB2_Reserve5 2000;
BA_ "GenSigTimeoutMsg_Gateway_PQ46_A" SG_ 1360 AB2_Reserve5 1360;
BA_ "GenSigSendType" SG_ 1360 AB2_Reserve5 0;
BA_ "GenSigTimeoutMsg_Gateway_PQ35_A" SG_ 517 Airbag_TP_Er 517;
BA_ "GenSigTimeoutMsg_Gateway_PQ46_A" SG_ 517 Airbag_TP_Er 517;
BA_ "GenSigSendType" SG_ 517 Airbag_TP_Er 5;
BA_ "GenSigTimeoutTime_Teves_MK60_ESP" SG_ 1524 BCN_AntriebsVar 5000;
BA_ "GenSigTimeoutMsg_Teves_MK60_ESP" SG_ 1524 BCN_AntriebsVar 1524;
BA_ "GenSigSendType" SG_ 1524 BCN_AntriebsVar 0;
BA_ "INIT" SG_ 1524 BCN_AntriebsVar "const";
BA_ "GenSigTimeoutTime_Teves_MK60_ESP" SG_ 1524 BCN_res_16 5000;
BA_ "GenSigTimeoutMsg_Teves_MK60_ESP" SG_ 1524 BCN_res_16 1524;
BA_ "GenSigSendType" SG_ 1524 BCN_res_16 0;
BA_ "GenSigTimeoutTime_Teves_MK60_ESP" SG_ 1524 BCN_res_24 5000;
BA_ "GenSigTimeoutMsg_Teves_MK60_ESP" SG_ 1524 BCN_res_24 1524;
BA_ "GenSigSendType" SG_ 1524 BCN_res_24 0;
BA_ "GenSigTimeoutTime_Teves_MK60_ESP" SG_ 1524 BCN_Checksumme 5000;
BA_ "GenSigTimeoutMsg_Teves_MK60_ESP" SG_ 1524 BCN_Checksumme 1524;
BA_ "GenSigSendType" SG_ 1524 BCN_Checksumme 0;
BA_ "INIT" SG_ 1524 BCN_Checksumme "CHK";
BA_ "GenSigTimeoutTime_Teves_MK60_ESP" SG_ 1524 BCN_BremsenVar 5000;
BA_ "GenSigTimeoutMsg_Teves_MK60_ESP" SG_ 1524 BCN_BremsenVar 1524;
BA_ "GenSigSendType" SG_ 1524 BCN_BremsenVar 0;
BA_ "INIT" SG_ 1524 BCN_BremsenVar "const";
BA_ "GenSigTimeoutMsg_Gateway_PQ35_A" SG_ 1919 ISO_Airbag_01_Resp_Data 1919;
BA_ "GenSigTimeoutMsg_Gateway_PQ46_A" SG_ 1919 ISO_Airbag_01_Resp_Data 1919;
BA_ "GenSigTimeoutMsg_Gateway_PQ35_A" SG_ 2041 Resp_Airbag_Deployment 2041;
BA_ "GenSigTimeoutMsg_Gateway_PQ46_A" SG_ 2041 Resp_Airbag_Deployment 2041;
BA_ "GenSigSendType" SG_ 2041 Resp_Airbag_Deployment 3;
BA_ "GenSigTimeoutMsg_Gateway_PQ35_A" SG_ 522 Allrad_TP_Er 522;
BA_ "GenSigTimeoutMsg_Gateway_PQ46_A" SG_ 522 Allrad_TP_Er 522;
BA_ "GenSigSendType" SG_ 522 Allrad_TP_Er 5;
BA_ "GenSigTimeoutTime_Teves_MK60_ESP" SG_ 704 AL1_Sta_Kup 500;
BA_ "GenSigTimeoutMsg_Teves_MK60_ESP" SG_ 704 AL1_Sta_Kup 704;
BA_ "GenSigTimeoutTime_Gateway_PQ35_A" SG_ 704 AL1_Sta_Kup 500;
BA_ "GenSigTimeoutMsg_Gateway_PQ35_A" SG_ 704 AL1_Sta_Kup 704;
BA_ "GenSigTimeoutTime_TRW_ESP" SG_ 704 AL1_Sta_Kup 500;
BA_ "GenSigTimeoutMsg_TRW_ESP" SG_ 704 AL1_Sta_Kup 704;
BA_ "GenSigTimeoutTime_Gateway_PQ46_A" SG_ 704 AL1_Sta_Kup 500;
BA_ "GenSigTimeoutMsg_Gateway_PQ46_A" SG_ 704 AL1_Sta_Kup 704;
BA_ "GenSigSendType" SG_ 704 AL1_Sta_Kup 0;
BA_ "GenSigTimeoutTime_Gateway_PQ35_A" SG_ 704 AL1_Uebertemp 500;
BA_ "GenSigTimeoutMsg_Gateway_PQ35_A" SG_ 704 AL1_Uebertemp 704;
BA_ "GenSigTimeoutTime_TRW_ESP" SG_ 704 AL1_Uebertemp 500;
BA_ "GenSigTimeoutMsg_TRW_ESP" SG_ 704 AL1_Uebertemp 704;
BA_ "GenSigTimeoutTime_Gateway_PQ46_A" SG_ 704 AL1_Uebertemp 500;
BA_ "GenSigTimeoutMsg_Gateway_PQ46_A" SG_ 704 AL1_Uebertemp 704;
BA_ "GenSigSendType" SG_ 704 AL1_Uebertemp 0;
BA_ "GenSigTimeoutTime_RKA_Plus" SG_ 704 AL1_Kup_offen 500;
BA_ "GenSigTimeoutMsg_RKA_Plus" SG_ 704 AL1_Kup_offen 704;
BA_ "GenSigTimeoutTime_Gateway_PQ35_A" SG_ 704 AL1_Kup_offen 500;
BA_ "GenSigTimeoutMsg_Gateway_PQ35_A" SG_ 704 AL1_Kup_offen 704;
BA_ "GenSigTimeoutTime_TRW_ESP" SG_ 704 AL1_Kup_offen 500;
BA_ "GenSigTimeoutMsg_TRW_ESP" SG_ 704 AL1_Kup_offen 704;
BA_ "GenSigTimeoutTime_Gateway_PQ46_A" SG_ 704 AL1_Kup_offen 500;
BA_ "GenSigTimeoutMsg_Gateway_PQ46_A" SG_ 704 AL1_Kup_offen 704;
BA_ "GenSigSendType" SG_ 704 AL1_Kup_offen 0;
BA_ "GenSigTimeoutTime_Teves_MK60_ESP" SG_ 704 AL1_Fehler 500;
BA_ "GenSigTimeoutMsg_Teves_MK60_ESP" SG_ 704 AL1_Fehler 704;
BA_ "GenSigTimeoutTime_RKA_Plus" SG_ 704 AL1_Fehler 500;
BA_ "GenSigTimeoutMsg_RKA_Plus" SG_ 704 AL1_Fehler 704;
BA_ "GenSigTimeoutTime_Gateway_PQ35_A" SG_ 704 AL1_Fehler 500;
BA_ "GenSigTimeoutMsg_Gateway_PQ35_A" SG_ 704 AL1_Fehler 704;
BA_ "GenSigTimeoutTime_TRW_ESP" SG_ 704 AL1_Fehler 500;
BA_ "GenSigTimeoutMsg_TRW_ESP" SG_ 704 AL1_Fehler 704;
BA_ "GenSigTimeoutTime_Gateway_PQ46_A" SG_ 704 AL1_Fehler 500;
BA_ "GenSigTimeoutMsg_Gateway_PQ46_A" SG_ 704 AL1_Fehler 704;
BA_ "GenSigSendType" SG_ 704 AL1_Fehler 0;
BA_ "GenSigTimeoutTime_RKA_Plus" SG_ 704 AL1_Einheit 500;
BA_ "GenSigTimeoutMsg_RKA_Plus" SG_ 704 AL1_Einheit 704;
BA_ "GenSigTimeoutTime_Gateway_PQ35_A" SG_ 704 AL1_Einheit 500;
BA_ "GenSigTimeoutMsg_Gateway_PQ35_A" SG_ 704 AL1_Einheit 704;
BA_ "GenSigTimeoutTime_TRW_ESP" SG_ 704 AL1_Einheit 500;
BA_ "GenSigTimeoutMsg_TRW_ESP" SG_ 704 AL1_Einheit 704;
BA_ "GenSigTimeoutTime_Teves_MK70_MAB" SG_ 704 AL1_Einheit 500;
BA_ "GenSigTimeoutMsg_Teves_MK70_MAB" SG_ 704 AL1_Einheit 704;
BA_ "GenSigTimeoutTime_Teves_MK60_ESP" SG_ 704 AL1_Einheit 500;
BA_ "GenSigTimeoutMsg_Teves_MK60_ESP" SG_ 704 AL1_Einheit 704;
BA_ "GenSigTimeoutTime_Gateway_PQ46_A" SG_ 704 AL1_Einheit 500;
BA_ "GenSigTimeoutMsg_Gateway_PQ46_A" SG_ 704 AL1_Einheit 704;
BA_ "GenSigSendType" SG_ 704 AL1_Einheit 0;
BA_ "GenSigTimeoutTime_Gateway_PQ35_A" SG_ 704 AL1_Warnlampe 500;
BA_ "GenSigTimeoutMsg_Gateway_PQ35_A" SG_ 704 AL1_Warnlampe 704;
BA_ "GenSigTimeoutTime_TRW_ESP" SG_ 704 AL1_Warnlampe 500;
BA_ "GenSigTimeoutMsg_TRW_ESP" SG_ 704 AL1_Warnlampe 704;
BA_ "GenSigTimeoutTime_Gateway_PQ46_A" SG_ 704 AL1_Warnlampe 500;
BA_ "GenSigTimeoutMsg_Gateway_PQ46_A" SG_ 704 AL1_Warnlampe 704;
BA_ "GenSigSendType" SG_ 704 AL1_Warnlampe 0;
BA_ "GenSigTimeoutTime_Gateway_PQ35_A" SG_ 704 AL1_Limiter 500;
BA_ "GenSigTimeoutMsg_Gateway_PQ35_A" SG_ 704 AL1_Limiter 704;
BA_ "GenSigTimeoutTime_Gateway_PQ46_A" SG_ 704 AL1_Limiter 500;
BA_ "GenSigTimeoutMsg_Gateway_PQ46_A" SG_ 704 AL1_Limiter 704;
BA_ "GenSigSendType" SG_ 704 AL1_Limiter 0;
BA_ "GenSigTimeoutTime_RKA_Plus" SG_ 704 AL1_Ist_Proz 500;
BA_ "GenSigTimeoutMsg_RKA_Plus" SG_ 704 AL1_Ist_Proz 704;
BA_ "GenSigTimeoutTime_Gateway_PQ35_A" SG_ 704 AL1_Ist_Proz 500;
BA_ "GenSigTimeoutMsg_Gateway_PQ35_A" SG_ 704 AL1_Ist_Proz 704;
BA_ "GenSigTimeoutTime_TRW_ESP" SG_ 704 AL1_Ist_Proz 500;
BA_ "GenSigTimeoutMsg_TRW_ESP" SG_ 704 AL1_Ist_Proz 704;
BA_ "GenSigTimeoutTime_Teves_MK70_MAB" SG_ 704 AL1_Ist_Proz 500;
BA_ "GenSigTimeoutMsg_Teves_MK70_MAB" SG_ 704 AL1_Ist_Proz 704;
BA_ "GenSigTimeoutTime_Teves_MK60_ESP" SG_ 704 AL1_Ist_Proz 500;
BA_ "GenSigTimeoutMsg_Teves_MK60_ESP" SG_ 704 AL1_Ist_Proz 704;
BA_ "GenSigTimeoutTime_Gateway_PQ46_A" SG_ 704 AL1_Ist_Proz 500;
BA_ "GenSigTimeoutMsg_Gateway_PQ46_A" SG_ 704 AL1_Ist_Proz 704;
BA_ "GenSigSendType" SG_ 704 AL1_Ist_Proz 0;
BA_ "GenSigStartValue" SG_ 704 AL1_Ist_Proz 255;
BA_ "GenSigTimeoutTime_Gateway_PQ35_A" SG_ 704 AL1_Notlauf 500;
BA_ "GenSigTimeoutMsg_Gateway_PQ35_A" SG_ 704 AL1_Notlauf 704;
BA_ "GenSigTimeoutTime_TRW_ESP" SG_ 704 AL1_Notlauf 500;
BA_ "GenSigTimeoutMsg_TRW_ESP" SG_ 704 AL1_Notlauf 704;
BA_ "GenSigTimeoutTime_Gateway_PQ46_A" SG_ 704 AL1_Notlauf 500;
BA_ "GenSigTimeoutMsg_Gateway_PQ46_A" SG_ 704 AL1_Notlauf 704;
BA_ "GenSigSendType" SG_ 704 AL1_Notlauf 0;
BA_ "GenSigTimeoutTime_Teves_MK60_ESP" SG_ 704 AL1_Sta_PNG 500;
BA_ "GenSigTimeoutMsg_Teves_MK60_ESP" SG_ 704 AL1_Sta_PNG 704;
BA_ "GenSigTimeoutTime_AFS" SG_ 704 AL1_Sta_PNG 500;
BA_ "GenSigTimeoutMsg_AFS" SG_ 704 AL1_Sta_PNG 704;
BA_ "GenSigTimeoutTime_Gateway_PQ35_A" SG_ 704 AL1_Sta_PNG 500;
BA_ "GenSigTimeoutMsg_Gateway_PQ35_A" SG_ 704 AL1_Sta_PNG 704;
BA_ "GenSigTimeoutTime_Gateway_PQ46_A" SG_ 704 AL1_Sta_PNG 500;
BA_ "GenSigTimeoutMsg_Gateway_PQ46_A" SG_ 704 AL1_Sta_PNG 704;
BA_ "GenSigSendType" SG_ 704 AL1_Sta_PNG 0;
BA_ "GenSigTimeoutTime_Gateway_PQ35_A" SG_ 704 AL1_Schalten 500;
BA_ "GenSigTimeoutMsg_Gateway_PQ35_A" SG_ 704 AL1_Schalten 704;
BA_ "GenSigTimeoutTime_Gateway_PQ46_A" SG_ 704 AL1_Schalten 500;
BA_ "GenSigTimeoutMsg_Gateway_PQ46_A" SG_ 704 AL1_Schalten 704;
BA_ "GenSigSendType" SG_ 704 AL1_Schalten 0;
BA_ "GenSigTimeoutTime_Gateway_PQ35_A" SG_ 704 AL1_Quersp_Sta 500;
BA_ "GenSigTimeoutMsg_Gateway_PQ35_A" SG_ 704 AL1_Quersp_Sta 704;
BA_ "GenSigTimeoutTime_Gateway_PQ46_A" SG_ 704 AL1_Quersp_Sta 500;
BA_ "GenSigTimeoutMsg_Gateway_PQ46_A" SG_ 704 AL1_Quersp_Sta 704;
BA_ "GenSigSendType" SG_ 704 AL1_Quersp_Sta 0;
BA_ "GenSigStartValue" SG_ 704 AL1_Quersp_Sta 3;
BA_ "GenSigTimeoutTime_Gateway_PQ35_A" SG_ 704 AL1_Vorwarnung 500;
BA_ "GenSigTimeoutMsg_Gateway_PQ35_A" SG_ 704 AL1_Vorwarnung 704;
BA_ "GenSigTimeoutTime_Gateway_PQ46_A" SG_ 704 AL1_Vorwarnung 500;
BA_ "GenSigTimeoutMsg_Gateway_PQ46_A" SG_ 704 AL1_Vorwarnung 704;
BA_ "GenSigSendType" SG_ 704 AL1_Vorwarnung 0;
BA_ "GenSigTimeoutTime_Gateway_PQ35_A" SG_ 704 AL1_Fehlereintr 500;
BA_ "GenSigTimeoutMsg_Gateway_PQ35_A" SG_ 704 AL1_Fehlereintr 704;
BA_ "GenSigTimeoutTime_Gateway_PQ46_A" SG_ 704 AL1_Fehlereintr 500;
BA_ "GenSigTimeoutMsg_Gateway_PQ46_A" SG_ 704 AL1_Fehlereintr 704;
BA_ "GenSigSendType" SG_ 704 AL1_Fehlereintr 0;
BA_ "GenSigTimeoutTime_Gateway_PQ35_A" SG_ 704 AL1_Anz_blinken 500;
BA_ "GenSigTimeoutMsg_Gateway_PQ35_A" SG_ 704 AL1_Anz_blinken 704;
BA_ "GenSigTimeoutTime_Gateway_PQ46_A" SG_ 704 AL1_Anz_blinken 500;
BA_ "GenSigTimeoutMsg_Gateway_PQ46_A" SG_ 704 AL1_Anz_blinken 704;
BA_ "GenSigSendType" SG_ 704 AL1_Anz_blinken 0;
BA_ "GenSigTimeoutTime_Gateway_PQ35_A" SG_ 704 AL1_Sta_Laengssp 500;
BA_ "GenSigTimeoutMsg_Gateway_PQ35_A" SG_ 704 AL1_Sta_Laengssp 704;
BA_ "GenSigTimeoutTime_Gateway_PQ46_A" SG_ 704 AL1_Sta_Laengssp 500;
BA_ "GenSigTimeoutMsg_Gateway_PQ46_A" SG_ 704 AL1_Sta_Laengssp 704;
BA_ "GenSigSendType" SG_ 704 AL1_Sta_Laengssp 0;
BA_ "GenSigTimeoutTime_RKA_Plus" SG_ 704 AL1_Ist_Nm 500;
BA_ "GenSigTimeoutMsg_RKA_Plus" SG_ 704 AL1_Ist_Nm 704;
BA_ "GenSigTimeoutTime_Gateway_PQ35_A" SG_ 704 AL1_Ist_Nm 500;
BA_ "GenSigTimeoutMsg_Gateway_PQ35_A" SG_ 704 AL1_Ist_Nm 704;
BA_ "GenSigTimeoutTime_TRW_ESP" SG_ 704 AL1_Ist_Nm 500;
BA_ "GenSigTimeoutMsg_TRW_ESP" SG_ 704 AL1_Ist_Nm 704;
BA_ "GenSigTimeoutTime_Gateway_PQ46_A" SG_ 704 AL1_Ist_Nm 500;
BA_ "GenSigTimeoutMsg_Gateway_PQ46_A" SG_ 704 AL1_Ist_Nm 704;
BA_ "GenSigSendType" SG_ 704 AL1_Ist_Nm 0;
BA_ "GenSigStartValue" SG_ 704 AL1_Ist_Nm 127;
BA_ "GenSigTimeoutTime_Gateway_PQ35_A" SG_ 704 AL1_Diff_Verbau 500;
BA_ "GenSigTimeoutMsg_Gateway_PQ35_A" SG_ 704 AL1_Diff_Verbau 704;
BA_ "GenSigTimeoutTime_Gateway_PQ46_A" SG_ 704 AL1_Diff_Verbau 500;
BA_ "GenSigTimeoutMsg_Gateway_PQ46_A" SG_ 704 AL1_Diff_Verbau 704;
BA_ "GenSigSendType" SG_ 704 AL1_Diff_Verbau 0;
BA_ "GenSigStartValue" SG_ 704 AL1_Diff_Verbau 1;
BA_ "GenSigTimeoutTime_Gateway_PQ35_A" SG_ 704 AL1_AnfVerteiler 500;
BA_ "GenSigTimeoutMsg_Gateway_PQ35_A" SG_ 704 AL1_AnfVerteiler 704;
BA_ "GenSigTimeoutTime_Gateway_PQ46_A" SG_ 704 AL1_AnfVerteiler 500;
BA_ "GenSigTimeoutMsg_Gateway_PQ46_A" SG_ 704 AL1_AnfVerteiler 704;
BA_ "GenSigSendType" SG_ 704 AL1_AnfVerteiler 0;
BA_ "GenSigTimeoutTime_Gateway_PQ35_A" SG_ 704 AL1_FaWu_Laengs 500;
BA_ "GenSigTimeoutMsg_Gateway_PQ35_A" SG_ 704 AL1_FaWu_Laengs 704;
BA_ "GenSigTimeoutTime_Gateway_PQ46_A" SG_ 704 AL1_FaWu_Laengs 500;
BA_ "GenSigTimeoutMsg_Gateway_PQ46_A" SG_ 704 AL1_FaWu_Laengs 704;
BA_ "GenSigSendType" SG_ 704 AL1_FaWu_Laengs 0;
BA_ "GenSigTimeoutTime_Gateway_PQ35_A" SG_ 704 AL1_FaWu_HA 500;
BA_ "GenSigTimeoutMsg_Gateway_PQ35_A" SG_ 704 AL1_FaWu_HA 704;
BA_ "GenSigTimeoutTime_Gateway_PQ46_A" SG_ 704 AL1_FaWu_HA 500;
BA_ "GenSigTimeoutMsg_Gateway_PQ46_A" SG_ 704 AL1_FaWu_HA 704;
BA_ "GenSigSendType" SG_ 704 AL1_FaWu_HA 0;
BA_ "GenSigTimeoutTime_Gateway_PQ35_A" SG_ 704 AL1_Limit_maxkmh 500;
BA_ "GenSigTimeoutMsg_Gateway_PQ35_A" SG_ 704 AL1_Limit_maxkmh 704;
BA_ "GenSigTimeoutTime_Gateway_PQ46_A" SG_ 704 AL1_Limit_maxkmh 500;
BA_ "GenSigTimeoutMsg_Gateway_PQ46_A" SG_ 704 AL1_Limit_maxkmh 704;
BA_ "GenSigSendType" SG_ 704 AL1_Limit_maxkmh 0;
BA_ "GenSigStartValue" SG_ 704 AL1_Limit_maxkmh 254;
BA_ "GenSigTimeoutTime_Gateway_PQ35_A" SG_ 704 AL1_KupSteifig_F 500;
BA_ "GenSigTimeoutMsg_Gateway_PQ35_A" SG_ 704 AL1_KupSteifig_F 704;
BA_ "GenSigTimeoutTime_Gateway_PQ46_A" SG_ 704 AL1_KupSteifig_F 500;
BA_ "GenSigTimeoutMsg_Gateway_PQ46_A" SG_ 704 AL1_KupSteifig_F 704;
BA_ "GenSigSendType" SG_ 704 AL1_KupSteifig_F 0;
BA_ "GenSigTimeoutTime_Gateway_PQ35_A" SG_ 704 AL1_FaWu_VA 500;
BA_ "GenSigTimeoutMsg_Gateway_PQ35_A" SG_ 704 AL1_FaWu_VA 704;
BA_ "GenSigTimeoutTime_Gateway_PQ46_A" SG_ 704 AL1_FaWu_VA 500;
BA_ "GenSigTimeoutMsg_Gateway_PQ46_A" SG_ 704 AL1_FaWu_VA 704;
BA_ "GenSigSendType" SG_ 704 AL1_FaWu_VA 0;
BA_ "GenSigTimeoutTime_Gateway_PQ35_A" SG_ 704 AL1_Sta_VA 500;
BA_ "GenSigTimeoutMsg_Gateway_PQ35_A" SG_ 704 AL1_Sta_VA 704;
BA_ "GenSigTimeoutTime_Gateway_PQ46_A" SG_ 704 AL1_Sta_VA 500;
BA_ "GenSigTimeoutMsg_Gateway_PQ46_A" SG_ 704 AL1_Sta_VA 704;
BA_ "GenSigSendType" SG_ 704 AL1_Sta_VA 0;
BA_ "GenSigTimeoutTime_Gateway_PQ35_A" SG_ 704 AL1_Sta_Quersp 500;
BA_ "GenSigTimeoutMsg_Gateway_PQ35_A" SG_ 704 AL1_Sta_Quersp 704;
BA_ "GenSigTimeoutTime_Gateway_PQ46_A" SG_ 704 AL1_Sta_Quersp 500;
BA_ "GenSigTimeoutMsg_Gateway_PQ46_A" SG_ 704 AL1_Sta_Quersp 704;
BA_ "GenSigSendType" SG_ 704 AL1_Sta_Quersp 0;
BA_ "GenSigTimeoutTime_Gateway_PQ35_A" SG_ 704 AL1_Warnton 500;
BA_ "GenSigTimeoutMsg_Gateway_PQ35_A" SG_ 704 AL1_Warnton 704;
BA_ "GenSigTimeoutTime_Gateway_PQ46_A" SG_ 704 AL1_Warnton 500;
BA_ "GenSigTimeoutMsg_Gateway_PQ46_A" SG_ 704 AL1_Warnton 704;
BA_ "GenSigSendType" SG_ 704 AL1_Warnton 0;
BA_ "GenSigTimeoutTime_Teves_MK60_ESP" SG_ 704 AL1_Stellung_Getr 500;
BA_ "GenSigTimeoutMsg_Teves_MK60_ESP" SG_ 704 AL1_Stellung_Getr 704;
BA_ "GenSigTimeoutTime_Gateway_PQ35_A" SG_ 704 AL1_Stellung_Getr 500;
BA_ "GenSigTimeoutMsg_Gateway_PQ35_A" SG_ 704 AL1_Stellung_Getr 704;
BA_ "GenSigTimeoutTime_Gateway_PQ46_A" SG_ 704 AL1_Stellung_Getr 500;
BA_ "GenSigTimeoutMsg_Gateway_PQ46_A" SG_ 704 AL1_Stellung_Getr 704;
BA_ "GenSigSendType" SG_ 704 AL1_Stellung_Getr 0;
BA_ "GenSigTimeoutTime_Gateway_PQ35_A" SG_ 704 AL1_KupplTemp 500;
BA_ "GenSigTimeoutMsg_Gateway_PQ35_A" SG_ 704 AL1_KupplTemp 704;
BA_ "GenSigTimeoutTime_Gateway_PQ46_A" SG_ 704 AL1_KupplTemp 500;
BA_ "GenSigTimeoutMsg_Gateway_PQ46_A" SG_ 704 AL1_KupplTemp 704;
BA_ "GenSigSendType" SG_ 704 AL1_KupplTemp 0;
BA_ "GenSigStartValue" SG_ 704 AL1_KupplTemp 254;
BA_ "GenSigTimeoutTime_Gateway_PQ35_A" SG_ 704 AL1_Diff_Lampe 500;
BA_ "GenSigTimeoutMsg_Gateway_PQ35_A" SG_ 704 AL1_Diff_Lampe 704;
BA_ "GenSigTimeoutTime_Gateway_PQ46_A" SG_ 704 AL1_Diff_Lampe 500;
BA_ "GenSigTimeoutMsg_Gateway_PQ46_A" SG_ 704 AL1_Diff_Lampe 704;
BA_ "GenSigSendType" SG_ 704 AL1_Diff_Lampe 0;
BA_ "GenSigStartValue" SG_ 704 AL1_Diff_Lampe 1;
BA_ "GenSigTimeoutTime_TRW_ESP" SG_ 704 AL1_Zaehler 500;
BA_ "GenSigTimeoutMsg_TRW_ESP" SG_ 704 AL1_Zaehler 704;
BA_ "GenSigTimeoutTime_Gateway_PQ35_A" SG_ 704 AL1_Zaehler 500;
BA_ "GenSigTimeoutMsg_Gateway_PQ35_A" SG_ 704 AL1_Zaehler 704;
BA_ "GenSigTimeoutTime_Gateway_PQ46_A" SG_ 704 AL1_Zaehler 500;
BA_ "GenSigTimeoutMsg_Gateway_PQ46_A" SG_ 704 AL1_Zaehler 704;
BA_ "GenSigSendType" SG_ 704 AL1_Zaehler 0;
BA_ "GenSigTimeoutTime_Gateway_PQ35_A" SG_ 704 AL1_Diff_Gong 500;
BA_ "GenSigTimeoutMsg_Gateway_PQ35_A" SG_ 704 AL1_Diff_Gong 704;
BA_ "GenSigTimeoutTime_Gateway_PQ46_A" SG_ 704 AL1_Diff_Gong 500;
BA_ "GenSigTimeoutMsg_Gateway_PQ46_A" SG_ 704 AL1_Diff_Gong 704;
BA_ "GenSigSendType" SG_ 704 AL1_Diff_Gong 0;
BA_ "GenSigTimeoutTime_HCA" SG_ 978 LH2_Zaehler 500;
BA_ "GenSigTimeoutMsg_HCA" SG_ 978 LH2_Zaehler 978;
BA_ "GenSigTimeoutTime_PDC_PLA" SG_ 978 LH2_Zaehler 500;
BA_ "GenSigTimeoutMsg_PDC_PLA" SG_ 978 LH2_Zaehler 978;
BA_ "GenSigSendType" SG_ 978 LH2_Zaehler 0;
BA_ "GenSigTimeoutTime_HCA" SG_ 978 LH2_Geradeaus 500;
BA_ "GenSigTimeoutMsg_HCA" SG_ 978 LH2_Geradeaus 978;
BA_ "GenSigTimeoutTime_PDC_PLA" SG_ 978 LH2_Geradeaus 500;
BA_ "GenSigTimeoutMsg_PDC_PLA" SG_ 978 LH2_Geradeaus 978;
BA_ "GenSigTimeoutTime_Magne_Ride" SG_ 978 LH2_Geradeaus 500;
BA_ "GenSigTimeoutMsg_Magne_Ride" SG_ 978 LH2_Geradeaus 978;
BA_ "GenSigTimeoutTime_LWS" SG_ 978 LH2_Geradeaus 500;
BA_ "GenSigTimeoutMsg_LWS" SG_ 978 LH2_Geradeaus 978;
BA_ "GenSigSendType" SG_ 978 LH2_Geradeaus 0;
BA_ "GenSigTimeoutTime_PDC_PLA" SG_ 978 LH2_Reserve_1 500;
BA_ "GenSigTimeoutMsg_PDC_PLA" SG_ 978 LH2_Reserve_1 978;
BA_ "GenSigTimeoutTime_HCA" SG_ 978 LH2_Reserve_1 500;
BA_ "GenSigTimeoutMsg_HCA" SG_ 978 LH2_Reserve_1 978;
BA_ "GenSigSendType" SG_ 978 LH2_Reserve_1 0;
BA_ "GenSigTimeoutTime_HCA" SG_ 978 LH2_PLA_Err 500;
BA_ "GenSigTimeoutMsg_HCA" SG_ 978 LH2_PLA_Err 978;
BA_ "GenSigTimeoutTime_PDC_PLA" SG_ 978 LH2_PLA_Err 500;
BA_ "GenSigTimeoutMsg_PDC_PLA" SG_ 978 LH2_PLA_Err 978;
BA_ "GenSigSendType" SG_ 978 LH2_PLA_Err 0;
BA_ "GenSigTimeoutTime_HCA" SG_ 978 LH2_Sta_HCA 500;
BA_ "GenSigTimeoutMsg_HCA" SG_ 978 LH2_Sta_HCA 978;
BA_ "GenSigTimeoutTime_PDC_PLA" SG_ 978 LH2_Sta_HCA 500;
BA_ "GenSigTimeoutMsg_PDC_PLA" SG_ 978 LH2_Sta_HCA 978;
BA_ "GenSigSendType" SG_ 978 LH2_Sta_HCA 0;
BA_ "GenSigTimeoutTime_PDC_PLA" SG_ 978 LH2_Reserve_2 500;
BA_ "GenSigTimeoutMsg_PDC_PLA" SG_ 978 LH2_Reserve_2 978;
BA_ "GenSigTimeoutTime_HCA" SG_ 978 LH2_Reserve_2 500;
BA_ "GenSigTimeoutMsg_HCA" SG_ 978 LH2_Reserve_2 978;
BA_ "GenSigSendType" SG_ 978 LH2_Reserve_2 0;
BA_ "GenSigTimeoutTime_HCA" SG_ 978 LH2_PLA_Abbr 500;
BA_ "GenSigTimeoutMsg_HCA" SG_ 978 LH2_PLA_Abbr 978;
BA_ "GenSigTimeoutTime_PDC_PLA" SG_ 978 LH2_PLA_Abbr 500;
BA_ "GenSigTimeoutMsg_PDC_PLA" SG_ 978 LH2_PLA_Abbr 978;
BA_ "GenSigSendType" SG_ 978 LH2_PLA_Abbr 0;
BA_ "GenSigTimeoutTime_HCA" SG_ 978 LH2_Sta_Charisma 500;
BA_ "GenSigTimeoutMsg_HCA" SG_ 978 LH2_Sta_Charisma 978;
BA_ "GenSigTimeoutTime_PDC_PLA" SG_ 978 LH2_Sta_Charisma 500;
BA_ "GenSigTimeoutMsg_PDC_PLA" SG_ 978 LH2_Sta_Charisma 978;
BA_ "GenSigSendType" SG_ 978 LH2_Sta_Charisma 0;
BA_ "GenSigStartValue" SG_ 978 LH2_Sta_Charisma 2;
BA_ "GenSigTimeoutTime_HCA" SG_ 978 LH2_StatEPS_PLA 500;
BA_ "GenSigTimeoutMsg_HCA" SG_ 978 LH2_StatEPS_PLA 978;
BA_ "GenSigTimeoutTime_PDC_PLA" SG_ 978 LH2_StatEPS_PLA 500;
BA_ "GenSigTimeoutMsg_PDC_PLA" SG_ 978 LH2_StatEPS_PLA 978;
BA_ "GenSigSendType" SG_ 978 LH2_StatEPS_PLA 0;
BA_ "GenSigTimeoutTime_PDC_PLA" SG_ 978 LH2_Reserve_3 500;
BA_ "GenSigTimeoutMsg_PDC_PLA" SG_ 978 LH2_Reserve_3 978;
BA_ "GenSigTimeoutTime_HCA" SG_ 978 LH2_Reserve_3 500;
BA_ "GenSigTimeoutMsg_HCA" SG_ 978 LH2_Reserve_3 978;
BA_ "GenSigSendType" SG_ 978 LH2_Reserve_3 0;
BA_ "GenSigTimeoutTime_HCA" SG_ 978 LH2_aktLenkeingriff 500;
BA_ "GenSigTimeoutMsg_HCA" SG_ 978 LH2_aktLenkeingriff 978;
BA_ "GenSigTimeoutTime_PDC_PLA" SG_ 978 LH2_aktLenkeingriff 500;
BA_ "GenSigTimeoutMsg_PDC_PLA" SG_ 978 LH2_aktLenkeingriff 978;
BA_ "GenSigSendType" SG_ 978 LH2_aktLenkeingriff 0;
BA_ "GenSigTimeoutTime_HCA" SG_ 978 LH2_Checksumme 500;
BA_ "GenSigTimeoutMsg_HCA" SG_ 978 LH2_Checksumme 978;
BA_ "GenSigTimeoutTime_PDC_PLA" SG_ 978 LH2_Checksumme 500;
BA_ "GenSigTimeoutMsg_PDC_PLA" SG_ 978 LH2_Checksumme 978;
BA_ "GenSigSendType" SG_ 978 LH2_Checksumme 0;
BA_ "INIT" SG_ 978 LH2_Checksumme "CHK";
BA_ "GenSigSendType" SG_ 978 LH2_Ausg_LW1 0;
BA_ "GenSigSendType" SG_ 978 LH2_Ausg_LW1_gue 0;
BA_ "GenSigTimeoutTime_Gateway_PQ35_A" SG_ 976 LH1_Sicherheitslamp 500;
BA_ "GenSigTimeoutMsg_Gateway_PQ35_A" SG_ 976 LH1_Sicherheitslamp 976;
BA_ "GenSigTimeoutTime_Gateway_PQ46_A" SG_ 976 LH1_Sicherheitslamp 500;
BA_ "GenSigTimeoutMsg_Gateway_PQ46_A" SG_ 976 LH1_Sicherheitslamp 976;
BA_ "GenSigSendType" SG_ 976 LH1_Sicherheitslamp 0;
BA_ "GenSigStartValue" SG_ 976 LH1_Sicherheitslamp 1;
BA_ "GenSigTimeoutTime_Gateway_PQ35_A" SG_ 976 LH1_Lastinfo 500;
BA_ "GenSigTimeoutMsg_Gateway_PQ35_A" SG_ 976 LH1_Lastinfo 976;
BA_ "GenSigTimeoutTime_Gateway_PQ46_A" SG_ 976 LH1_Lastinfo 500;
BA_ "GenSigTimeoutMsg_Gateway_PQ46_A" SG_ 976 LH1_Lastinfo 976;
BA_ "GenSigSendType" SG_ 976 LH1_Lastinfo 0;
BA_ "GenSigTimeoutTime_Gateway_PQ35_A" SG_ 976 LH1_Reserve1 500;
BA_ "GenSigTimeoutMsg_Gateway_PQ35_A" SG_ 976 LH1_Reserve1 976;
BA_ "GenSigTimeoutTime_Gateway_PQ46_A" SG_ 976 LH1_Reserve1 500;
BA_ "GenSigTimeoutMsg_Gateway_PQ46_A" SG_ 976 LH1_Reserve1 976;
BA_ "GenSigSendType" SG_ 976 LH1_Reserve1 0;
BA_ "GenSigTimeoutTime_Gateway_PQ35_A" SG_ 976 LH1_Fehlereintr 500;
BA_ "GenSigTimeoutMsg_Gateway_PQ35_A" SG_ 976 LH1_Fehlereintr 976;
BA_ "GenSigTimeoutTime_Gateway_PQ46_A" SG_ 976 LH1_Fehlereintr 500;
BA_ "GenSigTimeoutMsg_Gateway_PQ46_A" SG_ 976 LH1_Fehlereintr 976;
BA_ "GenSigSendType" SG_ 976 LH1_Fehlereintr 0;
BA_ "GenSigTimeoutTime_Gateway_PQ35_A" SG_ 976 LH1_SleepInd 500;
BA_ "GenSigTimeoutMsg_Gateway_PQ35_A" SG_ 976 LH1_SleepInd 976;
BA_ "GenSigTimeoutTime_Gateway_PQ46_A" SG_ 976 LH1_SleepInd 500;
BA_ "GenSigTimeoutMsg_Gateway_PQ46_A" SG_ 976 LH1_SleepInd 976;
BA_ "GenSigSendType" SG_ 976 LH1_SleepInd 0;
BA_ "GenSigTimeoutTime_Gateway_PQ35_A" SG_ 976 LH1_Fehler_LI 500;
BA_ "GenSigTimeoutMsg_Gateway_PQ35_A" SG_ 976 LH1_Fehler_LI 976;
BA_ "GenSigTimeoutTime_Gateway_PQ46_A" SG_ 976 LH1_Fehler_LI 500;
BA_ "GenSigTimeoutMsg_Gateway_PQ46_A" SG_ 976 LH1_Fehler_LI 976;
BA_ "GenSigSendType" SG_ 976 LH1_Fehler_LI 0;
BA_ "GenSigTimeoutTime_Gateway_PQ35_A" SG_ 976 LH1_Akustiksign 500;
BA_ "GenSigTimeoutMsg_Gateway_PQ35_A" SG_ 976 LH1_Akustiksign 976;
BA_ "GenSigTimeoutTime_Gateway_PQ46_A" SG_ 976 LH1_Akustiksign 500;
BA_ "GenSigTimeoutMsg_Gateway_PQ46_A" SG_ 976 LH1_Akustiksign 976;
BA_ "GenSigSendType" SG_ 976 LH1_Akustiksign 0;
BA_ "GenSigTimeoutTime_Gateway_PQ35_A" SG_ 976 LH1_ULeistung 500;
BA_ "GenSigTimeoutMsg_Gateway_PQ35_A" SG_ 976 LH1_ULeistung 976;
BA_ "GenSigTimeoutTime_Gateway_PQ46_A" SG_ 976 LH1_ULeistung 500;
BA_ "GenSigTimeoutMsg_Gateway_PQ46_A" SG_ 976 LH1_ULeistung 976;
BA_ "GenSigSendType" SG_ 976 LH1_ULeistung 0;
BA_ "GenSigTimeoutTime_Gateway_PQ35_A" SG_ 976 LH1_NL_LeistDichte 500;
BA_ "GenSigTimeoutMsg_Gateway_PQ35_A" SG_ 976 LH1_NL_LeistDichte 976;
BA_ "GenSigTimeoutTime_Gateway_PQ46_A" SG_ 976 LH1_NL_LeistDichte 500;
BA_ "GenSigTimeoutMsg_Gateway_PQ46_A" SG_ 976 LH1_NL_LeistDichte 976;
BA_ "GenSigSendType" SG_ 976 LH1_NL_LeistDichte 0;
BA_ "GenSigTimeoutTime_Gateway_PQ35_A" SG_ 976 LH1_EPS_Diagmode 500;
BA_ "GenSigTimeoutMsg_Gateway_PQ35_A" SG_ 976 LH1_EPS_Diagmode 976;
BA_ "GenSigTimeoutTime_Gateway_PQ46_A" SG_ 976 LH1_EPS_Diagmode 500;
BA_ "GenSigTimeoutMsg_Gateway_PQ46_A" SG_ 976 LH1_EPS_Diagmode 976;
BA_ "GenSigSendType" SG_ 976 LH1_EPS_Diagmode 0;
BA_ "GenSigTimeoutTime_Gateway_PQ35_A" SG_ 976 LH1_NL_ECU 500;
BA_ "GenSigTimeoutMsg_Gateway_PQ35_A" SG_ 976 LH1_NL_ECU 976;
BA_ "GenSigTimeoutTime_Gateway_PQ46_A" SG_ 976 LH1_NL_ECU 500;
BA_ "GenSigTimeoutMsg_Gateway_PQ46_A" SG_ 976 LH1_NL_ECU 976;
BA_ "GenSigSendType" SG_ 976 LH1_NL_ECU 0;
BA_ "GenSigTimeoutTime_Gateway_PQ35_A" SG_ 976 LH1_Textbits 500;
BA_ "GenSigTimeoutMsg_Gateway_PQ35_A" SG_ 976 LH1_Textbits 976;
BA_ "GenSigTimeoutTime_Gateway_PQ46_A" SG_ 976 LH1_Textbits 500;
BA_ "GenSigTimeoutMsg_Gateway_PQ46_A" SG_ 976 LH1_Textbits 976;
BA_ "GenSigSendType" SG_ 976 LH1_Textbits 0;
BA_ "GenSigTimeoutTime_Gateway_PQ35_A" SG_ 976 LH1_NL_Motor 500;
BA_ "GenSigTimeoutMsg_Gateway_PQ35_A" SG_ 976 LH1_NL_Motor 976;
BA_ "GenSigTimeoutTime_Gateway_PQ46_A" SG_ 976 LH1_NL_Motor 500;
BA_ "GenSigTimeoutMsg_Gateway_PQ46_A" SG_ 976 LH1_NL_Motor 976;
BA_ "GenSigSendType" SG_ 976 LH1_NL_Motor 0;
BA_ "GenSigTimeoutTime_Gateway_PQ35_A" SG_ 976 LH1_NL_CAN_SS 500;
BA_ "GenSigTimeoutMsg_Gateway_PQ35_A" SG_ 976 LH1_NL_CAN_SS 976;
BA_ "GenSigTimeoutTime_Gateway_PQ46_A" SG_ 976 LH1_NL_CAN_SS 500;
BA_ "GenSigTimeoutMsg_Gateway_PQ46_A" SG_ 976 LH1_NL_CAN_SS 976;
BA_ "GenSigSendType" SG_ 976 LH1_NL_CAN_SS 0;
BA_ "GenSigTimeoutTime_Gateway_PQ35_A" SG_ 976 LH1_NL_Sensor 500;
BA_ "GenSigTimeoutMsg_Gateway_PQ35_A" SG_ 976 LH1_NL_Sensor 976;
BA_ "GenSigTimeoutTime_Gateway_PQ46_A" SG_ 976 LH1_NL_Sensor 500;
BA_ "GenSigTimeoutMsg_Gateway_PQ46_A" SG_ 976 LH1_NL_Sensor 976;
BA_ "GenSigSendType" SG_ 976 LH1_NL_Sensor 0;
BA_ "GenSigTimeoutTime_Gateway_PQ35_A" SG_ 976 LH1_NL_Uebertemp 500;
BA_ "GenSigTimeoutMsg_Gateway_PQ35_A" SG_ 976 LH1_NL_Uebertemp 976;
BA_ "GenSigTimeoutTime_Gateway_PQ46_A" SG_ 976 LH1_NL_Uebertemp 500;
BA_ "GenSigTimeoutMsg_Gateway_PQ46_A" SG_ 976 LH1_NL_Uebertemp 976;
BA_ "GenSigSendType" SG_ 976 LH1_NL_Uebertemp 0;
BA_ "GenSigTimeoutTime_Gateway_PQ35_A" SG_ 976 LH1_NL_Uebersp 500;
BA_ "GenSigTimeoutMsg_Gateway_PQ35_A" SG_ 976 LH1_NL_Uebersp 976;
BA_ "GenSigTimeoutTime_Gateway_PQ46_A" SG_ 976 LH1_NL_Uebersp 500;
BA_ "GenSigTimeoutMsg_Gateway_PQ46_A" SG_ 976 LH1_NL_Uebersp 976;
BA_ "GenSigSendType" SG_ 976 LH1_NL_Uebersp 0;
BA_ "GenSigTimeoutTime_Gateway_PQ35_A" SG_ 976 LH1_NL_Untersp 500;
BA_ "GenSigTimeoutMsg_Gateway_PQ35_A" SG_ 976 LH1_NL_Untersp 976;
BA_ "GenSigTimeoutTime_Gateway_PQ46_A" SG_ 976 LH1_NL_Untersp 500;
BA_ "GenSigTimeoutMsg_Gateway_PQ46_A" SG_ 976 LH1_NL_Untersp 976;
BA_ "GenSigSendType" SG_ 976 LH1_NL_Untersp 0;
BA_ "GenSigTimeoutTime_Gateway_PQ35_A" SG_ 976 LH1_res_18 500;
BA_ "GenSigTimeoutMsg_Gateway_PQ35_A" SG_ 976 LH1_res_18 976;
BA_ "GenSigTimeoutTime_Gateway_PQ46_A" SG_ 976 LH1_res_18 500;
BA_ "GenSigTimeoutMsg_Gateway_PQ46_A" SG_ 976 LH1_res_18 976;
BA_ "GenSigSendType" SG_ 976 LH1_res_18 0;
BA_ "GenSigTimeoutTime_Gateway_PQ35_A" SG_ 976 LH1_Fehlerlampe 500;
BA_ "GenSigTimeoutMsg_Gateway_PQ35_A" SG_ 976 LH1_Fehlerlampe 976;
BA_ "GenSigTimeoutTime_Gateway_PQ46_A" SG_ 976 LH1_Fehlerlampe 500;
BA_ "GenSigTimeoutMsg_Gateway_PQ46_A" SG_ 976 LH1_Fehlerlampe 976;
BA_ "GenSigSendType" SG_ 976 LH1_Fehlerlampe 0;
BA_ "GenSigTimeoutTime_Gateway_PQ35_A" SG_ 976 LH1_res_17 500;
BA_ "GenSigTimeoutMsg_Gateway_PQ35_A" SG_ 976 LH1_res_17 976;
BA_ "GenSigTimeoutTime_Gateway_PQ46_A" SG_ 976 LH1_res_17 500;
BA_ "GenSigTimeoutMsg_Gateway_PQ46_A" SG_ 976 LH1_res_17 976;
BA_ "GenSigSendType" SG_ 976 LH1_res_17 0;
BA_ "GenSigTimeoutTime_Gateway_PQ35_A" SG_ 976 LH1_gue_ECU_Temp 500;
BA_ "GenSigTimeoutMsg_Gateway_PQ35_A" SG_ 976 LH1_gue_ECU_Temp 976;
BA_ "GenSigTimeoutTime_Gateway_PQ46_A" SG_ 976 LH1_gue_ECU_Temp 500;
BA_ "GenSigTimeoutMsg_Gateway_PQ46_A" SG_ 976 LH1_gue_ECU_Temp 976;
BA_ "GenSigSendType" SG_ 976 LH1_gue_ECU_Temp 0;
BA_ "GenSigTimeoutTime_Gateway_PQ35_A" SG_ 976 LH1_Kuehlung 500;
BA_ "GenSigTimeoutMsg_Gateway_PQ35_A" SG_ 976 LH1_Kuehlung 976;
BA_ "GenSigTimeoutTime_Gateway_PQ46_A" SG_ 976 LH1_Kuehlung 500;
BA_ "GenSigTimeoutMsg_Gateway_PQ46_A" SG_ 976 LH1_Kuehlung 976;
BA_ "GenSigSendType" SG_ 976 LH1_Kuehlung 0;
BA_ "GenSigTimeoutTime_Gateway_PQ35_A" SG_ 976 LH1_ECU_Temp 500;
BA_ "GenSigTimeoutMsg_Gateway_PQ35_A" SG_ 976 LH1_ECU_Temp 976;
BA_ "GenSigTimeoutTime_Gateway_PQ46_A" SG_ 976 LH1_ECU_Temp 500;
BA_ "GenSigTimeoutMsg_Gateway_PQ46_A" SG_ 976 LH1_ECU_Temp 976;
BA_ "GenSigSendType" SG_ 976 LH1_ECU_Temp 0;
BA_ "GenSigTimeoutTime_Gateway_PQ35_A" SG_ 976 LH1_Mode_Hybrid 500;
BA_ "GenSigTimeoutMsg_Gateway_PQ35_A" SG_ 976 LH1_Mode_Hybrid 976;
BA_ "GenSigTimeoutTime_Gateway_PQ46_A" SG_ 976 LH1_Mode_Hybrid 500;
BA_ "GenSigTimeoutMsg_Gateway_PQ46_A" SG_ 976 LH1_Mode_Hybrid 976;
BA_ "GenSigSendType" SG_ 976 LH1_Mode_Hybrid 0;
BA_ "INIT" SG_ 976 LH1_Mode_Hybrid "const";
BA_ "GenSigTimeoutMsg_Gateway_PQ35_A" SG_ 521 Lenkhilfe_TP_Er 521;
BA_ "GenSigTimeoutMsg_Gateway_PQ46_A" SG_ 521 Lenkhilfe_TP_Er 521;
BA_ "GenSigSendType" SG_ 521 Lenkhilfe_TP_Er 5;
BA_ "GenSigTimeoutTime_PDC_PLA" SG_ 208 LH3_BLWSign 500;
BA_ "GenSigTimeoutMsg_PDC_PLA" SG_ 208 LH3_BLWSign 208;
BA_ "GenSigTimeoutTime_HCA" SG_ 208 LH3_BLWSign 500;
BA_ "GenSigTimeoutMsg_HCA" SG_ 208 LH3_BLWSign 208;
BA_ "GenSigTimeoutTime_TRW_ESP" SG_ 208 LH3_BLWSign 500;
BA_ "GenSigTimeoutMsg_TRW_ESP" SG_ 208 LH3_BLWSign 208;
BA_ "GenSigTimeoutTime_Teves_MK60_ESP" SG_ 208 LH3_BLWSign 500;
BA_ "GenSigTimeoutMsg_Teves_MK60_ESP" SG_ 208 LH3_BLWSign 208;
BA_ "GenSigSendType" SG_ 208 LH3_BLWSign 0;
BA_ "GenSigTimeoutTime_Otto" SG_ 208 LH3_LM 500;
BA_ "GenSigTimeoutMsg_Otto" SG_ 208 LH3_LM 208;
BA_ "GenSigTimeoutTime_Diesel" SG_ 208 LH3_LM 500;
BA_ "GenSigTimeoutMsg_Diesel" SG_ 208 LH3_LM 208;
BA_ "GenSigTimeoutTime_HCA" SG_ 208 LH3_LM 500;
BA_ "GenSigTimeoutMsg_HCA" SG_ 208 LH3_LM 208;
BA_ "GenSigTimeoutTime_PDC_PLA" SG_ 208 LH3_LM 500;
BA_ "GenSigTimeoutMsg_PDC_PLA" SG_ 208 LH3_LM 208;
BA_ "GenSigTimeoutTime_TRW_ESP" SG_ 208 LH3_LM 500;
BA_ "GenSigTimeoutMsg_TRW_ESP" SG_ 208 LH3_LM 208;
BA_ "GenSigTimeoutTime_Teves_MK60_ESP" SG_ 208 LH3_LM 500;
BA_ "GenSigTimeoutMsg_Teves_MK60_ESP" SG_ 208 LH3_LM 208;
BA_ "GenSigSendType" SG_ 208 LH3_LM 0;
BA_ "GenSigTimeoutTime_PDC_PLA" SG_ 208 LH3_Checksumme 500;
BA_ "GenSigTimeoutMsg_PDC_PLA" SG_ 208 LH3_Checksumme 208;
BA_ "GenSigTimeoutTime_HCA" SG_ 208 LH3_Checksumme 500;
BA_ "GenSigTimeoutMsg_HCA" SG_ 208 LH3_Checksumme 208;
BA_ "GenSigTimeoutTime_TRW_ESP" SG_ 208 LH3_Checksumme 500;
BA_ "GenSigTimeoutMsg_TRW_ESP" SG_ 208 LH3_Checksumme 208;
BA_ "GenSigTimeoutTime_Teves_MK60_ESP" SG_ 208 LH3_Checksumme 500;
BA_ "GenSigTimeoutMsg_Teves_MK60_ESP" SG_ 208 LH3_Checksumme 208;
BA_ "GenSigSendType" SG_ 208 LH3_Checksumme 0;
BA_ "INIT" SG_ 208 LH3_Checksumme "CHK";
BA_ "GenSigTimeoutTime_PDC_PLA" SG_ 208 LH3_BLW 500;
BA_ "GenSigTimeoutMsg_PDC_PLA" SG_ 208 LH3_BLW 208;
BA_ "GenSigTimeoutTime_HCA" SG_ 208 LH3_BLW 500;
BA_ "GenSigTimeoutMsg_HCA" SG_ 208 LH3_BLW 208;
BA_ "GenSigTimeoutTime_TRW_ESP" SG_ 208 LH3_BLW 500;
BA_ "GenSigTimeoutMsg_TRW_ESP" SG_ 208 LH3_BLW 208;
BA_ "GenSigTimeoutTime_Teves_MK60_ESP" SG_ 208 LH3_BLW 500;
BA_ "GenSigTimeoutMsg_Teves_MK60_ESP" SG_ 208 LH3_BLW 208;
BA_ "GenSigSendType" SG_ 208 LH3_BLW 0;
BA_ "GenSigTimeoutTime_PDC_PLA" SG_ 208 LH3_Sta_DSR 500;
BA_ "GenSigTimeoutMsg_PDC_PLA" SG_ 208 LH3_Sta_DSR 208;
BA_ "GenSigTimeoutTime_HCA" SG_ 208 LH3_Sta_DSR 500;
BA_ "GenSigTimeoutMsg_HCA" SG_ 208 LH3_Sta_DSR 208;
BA_ "GenSigTimeoutTime_TRW_ESP" SG_ 208 LH3_Sta_DSR 500;
BA_ "GenSigTimeoutMsg_TRW_ESP" SG_ 208 LH3_Sta_DSR 208;
BA_ "GenSigTimeoutTime_Teves_MK60_ESP" SG_ 208 LH3_Sta_DSR 500;
BA_ "GenSigTimeoutMsg_Teves_MK60_ESP" SG_ 208 LH3_Sta_DSR 208;
BA_ "GenSigSendType" SG_ 208 LH3_Sta_DSR 0;
BA_ "GenSigTimeoutTime_PDC_PLA" SG_ 208 LH3_Zaehler 500;
BA_ "GenSigTimeoutMsg_PDC_PLA" SG_ 208 LH3_Zaehler 208;
BA_ "GenSigTimeoutTime_HCA" SG_ 208 LH3_Zaehler 500;
BA_ "GenSigTimeoutMsg_HCA" SG_ 208 LH3_Zaehler 208;
BA_ "GenSigTimeoutTime_TRW_ESP" SG_ 208 LH3_Zaehler 500;
BA_ "GenSigTimeoutMsg_TRW_ESP" SG_ 208 LH3_Zaehler 208;
BA_ "GenSigTimeoutTime_Teves_MK60_ESP" SG_ 208 LH3_Zaehler 500;
BA_ "GenSigTimeoutMsg_Teves_MK60_ESP" SG_ 208 LH3_Zaehler 208;
BA_ "GenSigSendType" SG_ 208 LH3_Zaehler 0;
BA_ "GenSigTimeoutTime_Otto" SG_ 208 LH3_LMSign 500;
BA_ "GenSigTimeoutMsg_Otto" SG_ 208 LH3_LMSign 208;
BA_ "GenSigTimeoutTime_Diesel" SG_ 208 LH3_LMSign 500;
BA_ "GenSigTimeoutMsg_Diesel" SG_ 208 LH3_LMSign 208;
BA_ "GenSigTimeoutTime_PDC_PLA" SG_ 208 LH3_LMSign 500;
BA_ "GenSigTimeoutMsg_PDC_PLA" SG_ 208 LH3_LMSign 208;
BA_ "GenSigTimeoutTime_HCA" SG_ 208 LH3_LMSign 500;
BA_ "GenSigTimeoutMsg_HCA" SG_ 208 LH3_LMSign 208;
BA_ "GenSigTimeoutTime_TRW_ESP" SG_ 208 LH3_LMSign 500;
BA_ "GenSigTimeoutMsg_TRW_ESP" SG_ 208 LH3_LMSign 208;
BA_ "GenSigTimeoutTime_Teves_MK60_ESP" SG_ 208 LH3_LMSign 500;
BA_ "GenSigTimeoutMsg_Teves_MK60_ESP" SG_ 208 LH3_LMSign 208;
BA_ "GenSigSendType" SG_ 208 LH3_LMSign 0;
BA_ "GenSigTimeoutTime_PDC_PLA" SG_ 208 LH3_Lenkungstyp 500;
BA_ "GenSigTimeoutMsg_PDC_PLA" SG_ 208 LH3_Lenkungstyp 208;
BA_ "GenSigTimeoutTime_HCA" SG_ 208 LH3_Lenkungstyp 500;
BA_ "GenSigTimeoutMsg_HCA" SG_ 208 LH3_Lenkungstyp 208;
BA_ "GenSigTimeoutTime_TRW_ESP" SG_ 208 LH3_Lenkungstyp 500;
BA_ "GenSigTimeoutMsg_TRW_ESP" SG_ 208 LH3_Lenkungstyp 208;
BA_ "GenSigTimeoutTime_Teves_MK60_ESP" SG_ 208 LH3_Lenkungstyp 500;
BA_ "GenSigTimeoutMsg_Teves_MK60_ESP" SG_ 208 LH3_Lenkungstyp 208;
BA_ "GenSigSendType" SG_ 208 LH3_Lenkungstyp 0;
BA_ "GenSigTimeoutTime_PDC_PLA" SG_ 208 LH3_BLWValid 500;
BA_ "GenSigTimeoutMsg_PDC_PLA" SG_ 208 LH3_BLWValid 208;
BA_ "GenSigTimeoutTime_HCA" SG_ 208 LH3_BLWValid 500;
BA_ "GenSigTimeoutMsg_HCA" SG_ 208 LH3_BLWValid 208;
BA_ "GenSigTimeoutTime_TRW_ESP" SG_ 208 LH3_BLWValid 500;
BA_ "GenSigTimeoutMsg_TRW_ESP" SG_ 208 LH3_BLWValid 208;
BA_ "GenSigTimeoutTime_Teves_MK60_ESP" SG_ 208 LH3_BLWValid 500;
BA_ "GenSigTimeoutMsg_Teves_MK60_ESP" SG_ 208 LH3_BLWValid 208;
BA_ "GenSigSendType" SG_ 208 LH3_BLWValid 0;
BA_ "GenSigTimeoutTime_Otto" SG_ 208 LH3_LMValid 500;
BA_ "GenSigTimeoutMsg_Otto" SG_ 208 LH3_LMValid 208;
BA_ "GenSigTimeoutTime_Diesel" SG_ 208 LH3_LMValid 500;
BA_ "GenSigTimeoutMsg_Diesel" SG_ 208 LH3_LMValid 208;
BA_ "GenSigTimeoutTime_PDC_PLA" SG_ 208 LH3_LMValid 500;
BA_ "GenSigTimeoutMsg_PDC_PLA" SG_ 208 LH3_LMValid 208;
BA_ "GenSigTimeoutTime_HCA" SG_ 208 LH3_LMValid 500;
BA_ "GenSigTimeoutMsg_HCA" SG_ 208 LH3_LMValid 208;
BA_ "GenSigTimeoutTime_TRW_ESP" SG_ 208 LH3_LMValid 500;
BA_ "GenSigTimeoutMsg_TRW_ESP" SG_ 208 LH3_LMValid 208;
BA_ "GenSigTimeoutTime_Teves_MK60_ESP" SG_ 208 LH3_LMValid 500;
BA_ "GenSigTimeoutMsg_Teves_MK60_ESP" SG_ 208 LH3_LMValid 208;
BA_ "GenSigSendType" SG_ 208 LH3_LMValid 0;
BA_ "GenSigTimeoutTime_PDC_PLA" SG_ 208 LH3_BS_Spiegel 500;
BA_ "GenSigTimeoutMsg_PDC_PLA" SG_ 208 LH3_BS_Spiegel 208;
BA_ "GenSigTimeoutTime_HCA" SG_ 208 LH3_BS_Spiegel 500;
BA_ "GenSigTimeoutMsg_HCA" SG_ 208 LH3_BS_Spiegel 208;
BA_ "GenSigTimeoutTime_TRW_ESP" SG_ 208 LH3_BS_Spiegel 500;
BA_ "GenSigTimeoutMsg_TRW_ESP" SG_ 208 LH3_BS_Spiegel 208;
BA_ "GenSigTimeoutTime_Teves_MK60_ESP" SG_ 208 LH3_BS_Spiegel 500;
BA_ "GenSigTimeoutMsg_Teves_MK60_ESP" SG_ 208 LH3_BS_Spiegel 208;
BA_ "GenSigSendType" SG_ 208 LH3_BS_Spiegel 0;
BA_ "GenSigTimeoutTime_Lenkhilfe_APA" SG_ 416 BR1_MSR_Anf 500;
BA_ "GenSigTimeoutMsg_Lenkhilfe_APA" SG_ 416 BR1_MSR_Anf 416;
BA_ "GenSigTimeoutTime_ACC_Lidar" SG_ 416 BR1_MSR_Anf 500;
BA_ "GenSigTimeoutMsg_ACC_Lidar" SG_ 416 BR1_MSR_Anf 416;
BA_ "GenSigTimeoutTime_Hybrid_DQ200" SG_ 416 BR1_MSR_Anf 500;
BA_ "GenSigTimeoutMsg_Hybrid_DQ200" SG_ 416 BR1_MSR_Anf 416;
BA_ "GenSigTimeoutTime_Hybrid_MSG" SG_ 416 BR1_MSR_Anf 500;
BA_ "GenSigTimeoutMsg_Hybrid_MSG" SG_ 416 BR1_MSR_Anf 416;
BA_ "GenSigTimeoutTime_PDC_PLA" SG_ 416 BR1_MSR_Anf 500;
BA_ "GenSigTimeoutMsg_PDC_PLA" SG_ 416 BR1_MSR_Anf 416;
BA_ "GenSigTimeoutTime_RKA_Plus" SG_ 416 BR1_MSR_Anf 500;
BA_ "GenSigTimeoutMsg_RKA_Plus" SG_ 416 BR1_MSR_Anf 416;
BA_ "GenSigTimeoutTime_Gateway_PQ35_A" SG_ 416 BR1_MSR_Anf 500;
BA_ "GenSigTimeoutMsg_Gateway_PQ35_A" SG_ 416 BR1_MSR_Anf 416;
BA_ "GenSigTimeoutTime_ACC_Radar" SG_ 416 BR1_MSR_Anf 500;
BA_ "GenSigTimeoutMsg_ACC_Radar" SG_ 416 BR1_MSR_Anf 416;
BA_ "GenSigTimeoutTime_DQ" SG_ 416 BR1_MSR_Anf 500;
BA_ "GenSigTimeoutMsg_DQ" SG_ 416 BR1_MSR_Anf 416;
BA_ "GenSigTimeoutTime_Otto" SG_ 416 BR1_MSR_Anf 500;
BA_ "GenSigTimeoutMsg_Otto" SG_ 416 BR1_MSR_Anf 416;
BA_ "GenSigTimeoutTime_Diesel" SG_ 416 BR1_MSR_Anf 500;
BA_ "GenSigTimeoutMsg_Diesel" SG_ 416 BR1_MSR_Anf 416;
BA_ "GenSigTimeoutTime_Gateway_PQ46_A" SG_ 416 BR1_MSR_Anf 500;
BA_ "GenSigTimeoutMsg_Gateway_PQ46_A" SG_ 416 BR1_MSR_Anf 416;
BA_ "GenSigTimeoutTime_Airbag" SG_ 416 BR1_MSR_Anf 500;
BA_ "GenSigTimeoutMsg_Airbag" SG_ 416 BR1_MSR_Anf 416;
BA_ "GenSigSendType" SG_ 416 BR1_MSR_Anf 0;
BA_ "GenSigTimeoutTime_Lenkhilfe_ZF_3" SG_ 416 BR1_ESP_Eingr 500;
BA_ "GenSigTimeoutMsg_Lenkhilfe_ZF_3" SG_ 416 BR1_ESP_Eingr 416;
BA_ "GenSigTimeoutTime_Lenkhilfe_ZF_2" SG_ 416 BR1_ESP_Eingr 500;
BA_ "GenSigTimeoutMsg_Lenkhilfe_ZF_2" SG_ 416 BR1_ESP_Eingr 416;
BA_ "GenSigTimeoutTime_Lenkhilfe_APA" SG_ 416 BR1_ESP_Eingr 500;
BA_ "GenSigTimeoutMsg_Lenkhilfe_APA" SG_ 416 BR1_ESP_Eingr 416;
BA_ "GenSigTimeoutTime_ACC_Lidar" SG_ 416 BR1_ESP_Eingr 500;
BA_ "GenSigTimeoutMsg_ACC_Lidar" SG_ 416 BR1_ESP_Eingr 416;
BA_ "GenSigTimeoutTime_Selespeed" SG_ 416 BR1_ESP_Eingr 500;
BA_ "GenSigTimeoutMsg_Selespeed" SG_ 416 BR1_ESP_Eingr 416;
BA_ "GenSigTimeoutTime_SWA" SG_ 416 BR1_ESP_Eingr 500;
BA_ "GenSigTimeoutMsg_SWA" SG_ 416 BR1_ESP_Eingr 416;
BA_ "GenSigTimeoutTime_HCA" SG_ 416 BR1_ESP_Eingr 500;
BA_ "GenSigTimeoutMsg_HCA" SG_ 416 BR1_ESP_Eingr 416;
BA_ "GenSigTimeoutTime_Hybrid_DQ200" SG_ 416 BR1_ESP_Eingr 500;
BA_ "GenSigTimeoutMsg_Hybrid_DQ200" SG_ 416 BR1_ESP_Eingr 416;
BA_ "GenSigTimeoutTime_Hybrid_MSG" SG_ 416 BR1_ESP_Eingr 500;
BA_ "GenSigTimeoutMsg_Hybrid_MSG" SG_ 416 BR1_ESP_Eingr 416;
BA_ "GenSigTimeoutTime_Daempfer" SG_ 416 BR1_ESP_Eingr 500;
BA_ "GenSigTimeoutMsg_Daempfer" SG_ 416 BR1_ESP_Eingr 416;
BA_ "GenSigTimeoutTime_PDC_PLA" SG_ 416 BR1_ESP_Eingr 500;
BA_ "GenSigTimeoutMsg_PDC_PLA" SG_ 416 BR1_ESP_Eingr 416;
BA_ "GenSigTimeoutTime_RKA_Plus" SG_ 416 BR1_ESP_Eingr 500;
BA_ "GenSigTimeoutMsg_RKA_Plus" SG_ 416 BR1_ESP_Eingr 416;
BA_ "GenSigTimeoutTime_Gateway_PQ35_A" SG_ 416 BR1_ESP_Eingr 500;
BA_ "GenSigTimeoutMsg_Gateway_PQ35_A" SG_ 416 BR1_ESP_Eingr 416;
BA_ "GenSigTimeoutTime_AFS" SG_ 416 BR1_ESP_Eingr 500;
BA_ "GenSigTimeoutMsg_AFS" SG_ 416 BR1_ESP_Eingr 416;
BA_ "GenSigTimeoutTime_ACC_Radar" SG_ 416 BR1_ESP_Eingr 500;
BA_ "GenSigTimeoutMsg_ACC_Radar" SG_ 416 BR1_ESP_Eingr 416;
BA_ "GenSigTimeoutTime_EPB" SG_ 416 BR1_ESP_Eingr 500;
BA_ "GenSigTimeoutMsg_EPB" SG_ 416 BR1_ESP_Eingr 416;
BA_ "GenSigTimeoutTime_DQ" SG_ 416 BR1_ESP_Eingr 500;
BA_ "GenSigTimeoutMsg_DQ" SG_ 416 BR1_ESP_Eingr 416;
BA_ "GenSigTimeoutTime_Otto" SG_ 416 BR1_ESP_Eingr 500;
BA_ "GenSigTimeoutMsg_Otto" SG_ 416 BR1_ESP_Eingr 416;
BA_ "GenSigTimeoutTime_Diesel" SG_ 416 BR1_ESP_Eingr 500;
BA_ "GenSigTimeoutMsg_Diesel" SG_ 416 BR1_ESP_Eingr 416;
BA_ "GenSigTimeoutTime_Allrad" SG_ 416 BR1_ESP_Eingr 500;
BA_ "GenSigTimeoutMsg_Allrad" SG_ 416 BR1_ESP_Eingr 416;
BA_ "GenSigTimeoutTime_Gateway_PQ46_A" SG_ 416 BR1_ESP_Eingr 500;
BA_ "GenSigTimeoutMsg_Gateway_PQ46_A" SG_ 416 BR1_ESP_Eingr 416;
BA_ "GenSigTimeoutTime_Airbag" SG_ 416 BR1_ESP_Eingr 500;
BA_ "GenSigTimeoutMsg_Airbag" SG_ 416 BR1_ESP_Eingr 416;
BA_ "GenSigTimeoutTime_AG6" SG_ 416 BR1_ESP_Eingr 500;
BA_ "GenSigTimeoutMsg_AG6" SG_ 416 BR1_ESP_Eingr 416;
BA_ "GenSigSendType" SG_ 416 BR1_ESP_Eingr 0;
BA_ "GenSigTimeoutTime_Lenkhilfe_APA" SG_ 416 BR1_ABS_Brems 500;
BA_ "GenSigTimeoutMsg_Lenkhilfe_APA" SG_ 416 BR1_ABS_Brems 416;
BA_ "GenSigTimeoutTime_ACC_Lidar" SG_ 416 BR1_ABS_Brems 500;
BA_ "GenSigTimeoutMsg_ACC_Lidar" SG_ 416 BR1_ABS_Brems 416;
BA_ "GenSigTimeoutTime_HCA" SG_ 416 BR1_ABS_Brems 500;
BA_ "GenSigTimeoutMsg_HCA" SG_ 416 BR1_ABS_Brems 416;
BA_ "GenSigTimeoutTime_Hybrid_DQ200" SG_ 416 BR1_ABS_Brems 500;
BA_ "GenSigTimeoutMsg_Hybrid_DQ200" SG_ 416 BR1_ABS_Brems 416;
BA_ "GenSigTimeoutTime_Daempfer" SG_ 416 BR1_ABS_Brems 500;
BA_ "GenSigTimeoutMsg_Daempfer" SG_ 416 BR1_ABS_Brems 416;
BA_ "GenSigTimeoutTime_PDC_PLA" SG_ 416 BR1_ABS_Brems 500;
BA_ "GenSigTimeoutMsg_PDC_PLA" SG_ 416 BR1_ABS_Brems 416;
BA_ "GenSigTimeoutTime_RKA_Plus" SG_ 416 BR1_ABS_Brems 500;
BA_ "GenSigTimeoutMsg_RKA_Plus" SG_ 416 BR1_ABS_Brems 416;
BA_ "GenSigTimeoutTime_Magne_Ride" SG_ 416 BR1_ABS_Brems 500;
BA_ "GenSigTimeoutMsg_Magne_Ride" SG_ 416 BR1_ABS_Brems 416;
BA_ "GenSigTimeoutTime_Gateway_PQ35_A" SG_ 416 BR1_ABS_Brems 500;
BA_ "GenSigTimeoutMsg_Gateway_PQ35_A" SG_ 416 BR1_ABS_Brems 416;
BA_ "GenSigTimeoutTime_ACC_Radar" SG_ 416 BR1_ABS_Brems 500;
BA_ "GenSigTimeoutMsg_ACC_Radar" SG_ 416 BR1_ABS_Brems 416;
BA_ "GenSigTimeoutTime_EPB" SG_ 416 BR1_ABS_Brems 500;
BA_ "GenSigTimeoutMsg_EPB" SG_ 416 BR1_ABS_Brems 416;
BA_ "GenSigTimeoutTime_DQ" SG_ 416 BR1_ABS_Brems 500;
BA_ "GenSigTimeoutMsg_DQ" SG_ 416 BR1_ABS_Brems 416;
BA_ "GenSigTimeoutTime_Diesel" SG_ 416 BR1_ABS_Brems 500;
BA_ "GenSigTimeoutMsg_Diesel" SG_ 416 BR1_ABS_Brems 416;
BA_ "GenSigTimeoutTime_Allrad" SG_ 416 BR1_ABS_Brems 500;
BA_ "GenSigTimeoutMsg_Allrad" SG_ 416 BR1_ABS_Brems 416;
BA_ "GenSigTimeoutTime_Gateway_PQ46_A" SG_ 416 BR1_ABS_Brems 500;
BA_ "GenSigTimeoutMsg_Gateway_PQ46_A" SG_ 416 BR1_ABS_Brems 416;
BA_ "GenSigTimeoutTime_Airbag" SG_ 416 BR1_ABS_Brems 500;
BA_ "GenSigTimeoutMsg_Airbag" SG_ 416 BR1_ABS_Brems 416;
BA_ "GenSigSendType" SG_ 416 BR1_ABS_Brems 0;
BA_ "GenSigTimeoutTime_Lenkhilfe_APA" SG_ 416 BR1_ASR_Anf 500;
BA_ "GenSigTimeoutMsg_Lenkhilfe_APA" SG_ 416 BR1_ASR_Anf 416;
BA_ "GenSigTimeoutTime_ACC_Lidar" SG_ 416 BR1_ASR_Anf 500;
BA_ "GenSigTimeoutMsg_ACC_Lidar" SG_ 416 BR1_ASR_Anf 416;
BA_ "GenSigTimeoutTime_Hybrid_DQ200" SG_ 416 BR1_ASR_Anf 500;
BA_ "GenSigTimeoutMsg_Hybrid_DQ200" SG_ 416 BR1_ASR_Anf 416;
BA_ "GenSigTimeoutTime_Hybrid_MSG" SG_ 416 BR1_ASR_Anf 500;
BA_ "GenSigTimeoutMsg_Hybrid_MSG" SG_ 416 BR1_ASR_Anf 416;
BA_ "GenSigTimeoutTime_PDC_PLA" SG_ 416 BR1_ASR_Anf 500;
BA_ "GenSigTimeoutMsg_PDC_PLA" SG_ 416 BR1_ASR_Anf 416;
BA_ "GenSigTimeoutTime_RKA_Plus" SG_ 416 BR1_ASR_Anf 500;
BA_ "GenSigTimeoutMsg_RKA_Plus" SG_ 416 BR1_ASR_Anf 416;
BA_ "GenSigTimeoutTime_Gateway_PQ35_A" SG_ 416 BR1_ASR_Anf 500;
BA_ "GenSigTimeoutMsg_Gateway_PQ35_A" SG_ 416 BR1_ASR_Anf 416;
BA_ "GenSigTimeoutTime_ACC_Radar" SG_ 416 BR1_ASR_Anf 500;
BA_ "GenSigTimeoutMsg_ACC_Radar" SG_ 416 BR1_ASR_Anf 416;
BA_ "GenSigTimeoutTime_DQ" SG_ 416 BR1_ASR_Anf 500;
BA_ "GenSigTimeoutMsg_DQ" SG_ 416 BR1_ASR_Anf 416;
BA_ "GenSigTimeoutTime_Otto" SG_ 416 BR1_ASR_Anf 500;
BA_ "GenSigTimeoutMsg_Otto" SG_ 416 BR1_ASR_Anf 416;
BA_ "GenSigTimeoutTime_Diesel" SG_ 416 BR1_ASR_Anf 500;
BA_ "GenSigTimeoutMsg_Diesel" SG_ 416 BR1_ASR_Anf 416;
BA_ "GenSigTimeoutTime_Gateway_PQ46_A" SG_ 416 BR1_ASR_Anf 500;
BA_ "GenSigTimeoutMsg_Gateway_PQ46_A" SG_ 416 BR1_ASR_Anf 416;
BA_ "GenSigTimeoutTime_Airbag" SG_ 416 BR1_ASR_Anf 500;
BA_ "GenSigTimeoutMsg_Airbag" SG_ 416 BR1_ASR_Anf 416;
BA_ "GenSigSendType" SG_ 416 BR1_ASR_Anf 0;
BA_ "GenSigTimeoutTime_Lenkhilfe_APA" SG_ 416 BR1_ASR_Eingr 500;
BA_ "GenSigTimeoutMsg_Lenkhilfe_APA" SG_ 416 BR1_ASR_Eingr 416;
BA_ "GenSigTimeoutTime_Hybrid_DQ200" SG_ 416 BR1_ASR_Eingr 500;
BA_ "GenSigTimeoutMsg_Hybrid_DQ200" SG_ 416 BR1_ASR_Eingr 416;
BA_ "GenSigTimeoutTime_Gateway_PQ35_A" SG_ 416 BR1_ASR_Eingr 500;
BA_ "GenSigTimeoutMsg_Gateway_PQ35_A" SG_ 416 BR1_ASR_Eingr 416;
BA_ "GenSigTimeoutTime_DQ" SG_ 416 BR1_ASR_Eingr 500;
BA_ "GenSigTimeoutMsg_DQ" SG_ 416 BR1_ASR_Eingr 416;
BA_ "GenSigTimeoutTime_Gateway_PQ46_A" SG_ 416 BR1_ASR_Eingr 500;
BA_ "GenSigTimeoutMsg_Gateway_PQ46_A" SG_ 416 BR1_ASR_Eingr 416;
BA_ "GenSigTimeoutTime_AG6" SG_ 416 BR1_ASR_Eingr 500;
BA_ "GenSigTimeoutMsg_AG6" SG_ 416 BR1_ASR_Eingr 416;
BA_ "GenSigSendType" SG_ 416 BR1_ASR_Eingr 0;
BA_ "GenSigTimeoutTime_Lenkhilfe_APA" SG_ 416 BR1_EBV_Eingr 500;
BA_ "GenSigTimeoutMsg_Lenkhilfe_APA" SG_ 416 BR1_EBV_Eingr 416;
BA_ "GenSigTimeoutTime_Daempfer" SG_ 416 BR1_EBV_Eingr 500;
BA_ "GenSigTimeoutMsg_Daempfer" SG_ 416 BR1_EBV_Eingr 416;
BA_ "GenSigTimeoutTime_RKA_Plus" SG_ 416 BR1_EBV_Eingr 500;
BA_ "GenSigTimeoutMsg_RKA_Plus" SG_ 416 BR1_EBV_Eingr 416;
BA_ "GenSigTimeoutTime_Gateway_PQ35_A" SG_ 416 BR1_EBV_Eingr 500;
BA_ "GenSigTimeoutMsg_Gateway_PQ35_A" SG_ 416 BR1_EBV_Eingr 416;
BA_ "GenSigTimeoutTime_Gateway_PQ46_A" SG_ 416 BR1_EBV_Eingr 500;
BA_ "GenSigTimeoutMsg_Gateway_PQ46_A" SG_ 416 BR1_EBV_Eingr 416;
BA_ "GenSigSendType" SG_ 416 BR1_EBV_Eingr 0;
BA_ "GenSigTimeoutTime_Hybrid_MSG" SG_ 416 BR1_StaDruckschw 500;
BA_ "GenSigTimeoutMsg_Hybrid_MSG" SG_ 416 BR1_StaDruckschw 416;
BA_ "GenSigTimeoutTime_Gateway_PQ35_A" SG_ 416 BR1_StaDruckschw 500;
BA_ "GenSigTimeoutMsg_Gateway_PQ35_A" SG_ 416 BR1_StaDruckschw 416;
BA_ "GenSigTimeoutTime_Otto" SG_ 416 BR1_StaDruckschw 500;
BA_ "GenSigTimeoutMsg_Otto" SG_ 416 BR1_StaDruckschw 416;
BA_ "GenSigTimeoutTime_Diesel" SG_ 416 BR1_StaDruckschw 500;
BA_ "GenSigTimeoutMsg_Diesel" SG_ 416 BR1_StaDruckschw 416;
BA_ "GenSigTimeoutTime_Gateway_PQ46_A" SG_ 416 BR1_StaDruckschw 500;
BA_ "GenSigTimeoutMsg_Gateway_PQ46_A" SG_ 416 BR1_StaDruckschw 416;
BA_ "GenSigSendType" SG_ 416 BR1_StaDruckschw 0;
BA_ "INIT" SG_ 416 BR1_StaDruckschw "0/1";
BA_ "GenSigTimeoutTime_Gateway_PQ35_A" SG_ 416 BR1_Lampe_ASR 500;
BA_ "GenSigTimeoutMsg_Gateway_PQ35_A" SG_ 416 BR1_Lampe_ASR 416;
BA_ "GenSigTimeoutTime_Gateway_PQ46_A" SG_ 416 BR1_Lampe_ASR 500;
BA_ "GenSigTimeoutMsg_Gateway_PQ46_A" SG_ 416 BR1_Lampe_ASR 416;
BA_ "GenSigSendType" SG_ 416 BR1_Lampe_ASR 0;
BA_ "INIT" SG_ 416 BR1_Lampe_ASR "0/1";
BA_ "GenSigTimeoutTime_Gateway_PQ35_A" SG_ 416 BR1_Lampe_BK 500;
BA_ "GenSigTimeoutMsg_Gateway_PQ35_A" SG_ 416 BR1_Lampe_BK 416;
BA_ "GenSigTimeoutTime_Gateway_PQ46_A" SG_ 416 BR1_Lampe_BK 500;
BA_ "GenSigTimeoutMsg_Gateway_PQ46_A" SG_ 416 BR1_Lampe_BK 416;
BA_ "GenSigSendType" SG_ 416 BR1_Lampe_BK 0;
BA_ "GenSigTimeoutTime_Lenkhilfe_ZF_3" SG_ 416 BR1_Lichtschalt 500;
BA_ "GenSigTimeoutMsg_Lenkhilfe_ZF_3" SG_ 416 BR1_Lichtschalt 416;
BA_ "GenSigTimeoutTime_Lenkhilfe_ZF_2" SG_ 416 BR1_Lichtschalt 500;
BA_ "GenSigTimeoutMsg_Lenkhilfe_ZF_2" SG_ 416 BR1_Lichtschalt 416;
BA_ "GenSigTimeoutTime_Lenkhilfe_APA" SG_ 416 BR1_Lichtschalt 500;
BA_ "GenSigTimeoutMsg_Lenkhilfe_APA" SG_ 416 BR1_Lichtschalt 416;
BA_ "GenSigTimeoutTime_Hybrid_MSG" SG_ 416 BR1_Lichtschalt 500;
BA_ "GenSigTimeoutMsg_Hybrid_MSG" SG_ 416 BR1_Lichtschalt 416;
BA_ "GenSigTimeoutTime_RKA_Plus" SG_ 416 BR1_Lichtschalt 500;
BA_ "GenSigTimeoutMsg_RKA_Plus" SG_ 416 BR1_Lichtschalt 416;
BA_ "GenSigTimeoutTime_Gateway_PQ35_A" SG_ 416 BR1_Lichtschalt 500;
BA_ "GenSigTimeoutMsg_Gateway_PQ35_A" SG_ 416 BR1_Lichtschalt 416;
BA_ "GenSigTimeoutTime_AFS" SG_ 416 BR1_Lichtschalt 500;
BA_ "GenSigTimeoutMsg_AFS" SG_ 416 BR1_Lichtschalt 416;
BA_ "GenSigTimeoutTime_Otto" SG_ 416 BR1_Lichtschalt 500;
BA_ "GenSigTimeoutMsg_Otto" SG_ 416 BR1_Lichtschalt 416;
BA_ "GenSigTimeoutTime_Diesel" SG_ 416 BR1_Lichtschalt 500;
BA_ "GenSigTimeoutMsg_Diesel" SG_ 416 BR1_Lichtschalt 416;
BA_ "GenSigTimeoutTime_Gateway_PQ46_A" SG_ 416 BR1_Lichtschalt 500;
BA_ "GenSigTimeoutMsg_Gateway_PQ46_A" SG_ 416 BR1_Lichtschalt 416;
BA_ "GenSigSendType" SG_ 416 BR1_Lichtschalt 0;
BA_ "GenSigTimeoutTime_Gateway_PQ35_A" SG_ 416 BR1_Lampe_ABS 500;
BA_ "GenSigTimeoutMsg_Gateway_PQ35_A" SG_ 416 BR1_Lampe_ABS 416;
BA_ "GenSigTimeoutTime_Gateway_PQ46_A" SG_ 416 BR1_Lampe_ABS 500;
BA_ "GenSigTimeoutMsg_Gateway_PQ46_A" SG_ 416 BR1_Lampe_ABS 416;
BA_ "GenSigSendType" SG_ 416 BR1_Lampe_ABS 0;
BA_ "GenSigStartValue" SG_ 416 BR1_Lampe_ABS 1;
BA_ "GenSigTimeoutTime_Gateway_PQ35_A" SG_ 416 BR1_MAD 500;
BA_ "GenSigTimeoutMsg_Gateway_PQ35_A" SG_ 416 BR1_MAD 416;
BA_ "GenSigTimeoutTime_Gateway_PQ46_A" SG_ 416 BR1_MAD 500;
BA_ "GenSigTimeoutMsg_Gateway_PQ46_A" SG_ 416 BR1_MAD 416;
BA_ "GenSigSendType" SG_ 416 BR1_MAD 0;
BA_ "GenSigTimeoutTime_Gateway_PQ35_A" SG_ 416 BR1_Sta_MAD 500;
BA_ "GenSigTimeoutMsg_Gateway_PQ35_A" SG_ 416 BR1_Sta_MAD 416;
BA_ "GenSigTimeoutTime_Gateway_PQ46_A" SG_ 416 BR1_Sta_MAD 500;
BA_ "GenSigTimeoutMsg_Gateway_PQ46_A" SG_ 416 BR1_Sta_MAD 416;
BA_ "GenSigSendType" SG_ 416 BR1_Sta_MAD 0;
BA_ "INIT" SG_ 416 BR1_Sta_MAD "0/1";
BA_ "GenSigTimeoutTime_Hybrid_MSG" SG_ 416 BR1_ASRMo_sl 500;
BA_ "GenSigTimeoutMsg_Hybrid_MSG" SG_ 416 BR1_ASRMo_sl 416;
BA_ "GenSigTimeoutTime_Gateway_PQ35_A" SG_ 416 BR1_ASRMo_sl 500;
BA_ "GenSigTimeoutMsg_Gateway_PQ35_A" SG_ 416 BR1_ASRMo_sl 416;
BA_ "GenSigTimeoutTime_Otto" SG_ 416 BR1_ASRMo_sl 500;
BA_ "GenSigTimeoutMsg_Otto" SG_ 416 BR1_ASRMo_sl 416;
BA_ "GenSigTimeoutTime_Gateway_PQ46_A" SG_ 416 BR1_ASRMo_sl 500;
BA_ "GenSigTimeoutMsg_Gateway_PQ46_A" SG_ 416 BR1_ASRMo_sl 416;
BA_ "GenSigSendType" SG_ 416 BR1_ASRMo_sl 0;
BA_ "GenSigStartValue" SG_ 416 BR1_ASRMo_sl 254;
BA_ "GenSigTimeoutTime_Airbag" SG_ 416 BR1_Diagnose 500;
BA_ "GenSigTimeoutMsg_Airbag" SG_ 416 BR1_Diagnose 416;
BA_ "GenSigTimeoutTime_Gateway_PQ35_A" SG_ 416 BR1_Diagnose 500;
BA_ "GenSigTimeoutMsg_Gateway_PQ35_A" SG_ 416 BR1_Diagnose 416;
BA_ "GenSigTimeoutTime_Gateway_PQ46_A" SG_ 416 BR1_Diagnose 500;
BA_ "GenSigTimeoutMsg_Gateway_PQ46_A" SG_ 416 BR1_Diagnose 416;
BA_ "GenSigSendType" SG_ 416 BR1_Diagnose 0;
BA_ "GenSigTimeoutTime_Hybrid_MSG" SG_ 416 BR1_ASRMo_fa 500;
BA_ "GenSigTimeoutMsg_Hybrid_MSG" SG_ 416 BR1_ASRMo_fa 416;
BA_ "GenSigTimeoutTime_Gateway_PQ35_A" SG_ 416 BR1_ASRMo_fa 500;
BA_ "GenSigTimeoutMsg_Gateway_PQ35_A" SG_ 416 BR1_ASRMo_fa 416;
BA_ "GenSigTimeoutTime_Otto" SG_ 416 BR1_ASRMo_fa 500;
BA_ "GenSigTimeoutMsg_Otto" SG_ 416 BR1_ASRMo_fa 416;
BA_ "GenSigTimeoutTime_Diesel" SG_ 416 BR1_ASRMo_fa 500;
BA_ "GenSigTimeoutMsg_Diesel" SG_ 416 BR1_ASRMo_fa 416;
BA_ "GenSigTimeoutTime_Gateway_PQ46_A" SG_ 416 BR1_ASRMo_fa 500;
BA_ "GenSigTimeoutMsg_Gateway_PQ46_A" SG_ 416 BR1_ASRMo_fa 416;
BA_ "GenSigSendType" SG_ 416 BR1_ASRMo_fa 0;
BA_ "GenSigStartValue" SG_ 416 BR1_ASRMo_fa 254;
BA_ "GenSigTimeoutTime_Hybrid_MSG" SG_ 416 BR1_MSR_Mo 500;
BA_ "GenSigTimeoutMsg_Hybrid_MSG" SG_ 416 BR1_MSR_Mo 416;
BA_ "GenSigTimeoutTime_Gateway_PQ35_A" SG_ 416 BR1_MSR_Mo 500;
BA_ "GenSigTimeoutMsg_Gateway_PQ35_A" SG_ 416 BR1_MSR_Mo 416;
BA_ "GenSigTimeoutTime_Otto" SG_ 416 BR1_MSR_Mo 500;
BA_ "GenSigTimeoutMsg_Otto" SG_ 416 BR1_MSR_Mo 416;
BA_ "GenSigTimeoutTime_Diesel" SG_ 416 BR1_MSR_Mo 500;
BA_ "GenSigTimeoutMsg_Diesel" SG_ 416 BR1_MSR_Mo 416;
BA_ "GenSigTimeoutTime_Gateway_PQ46_A" SG_ 416 BR1_MSR_Mo 500;
BA_ "GenSigTimeoutMsg_Gateway_PQ46_A" SG_ 416 BR1_MSR_Mo 416;
BA_ "GenSigSendType" SG_ 416 BR1_MSR_Mo 0;
BA_ "GenSigTimeoutTime_Hybrid_MSG" SG_ 416 BR1_BKV_aktiv 500;
BA_ "GenSigTimeoutMsg_Hybrid_MSG" SG_ 416 BR1_BKV_aktiv 416;
BA_ "GenSigTimeoutTime_Diesel" SG_ 416 BR1_BKV_aktiv 500;
BA_ "GenSigTimeoutMsg_Diesel" SG_ 416 BR1_BKV_aktiv 416;
BA_ "GenSigTimeoutTime_Otto" SG_ 416 BR1_BKV_aktiv 500;
BA_ "GenSigTimeoutMsg_Otto" SG_ 416 BR1_BKV_aktiv 416;
BA_ "GenSigTimeoutTime_Gateway_PQ35_A" SG_ 416 BR1_BKV_aktiv 500;
BA_ "GenSigTimeoutMsg_Gateway_PQ35_A" SG_ 416 BR1_BKV_aktiv 416;
BA_ "GenSigTimeoutTime_Gateway_PQ46_A" SG_ 416 BR1_BKV_aktiv 500;
BA_ "GenSigTimeoutMsg_Gateway_PQ46_A" SG_ 416 BR1_BKV_aktiv 416;
BA_ "GenSigSendType" SG_ 416 BR1_BKV_aktiv 0;
BA_ "GenSigTimeoutTime_FLA" SG_ 416 BR1_Rad_kmh 500;
BA_ "GenSigTimeoutMsg_FLA" SG_ 416 BR1_Rad_kmh 416;
BA_ "GenSigTimeoutTime_Hybrid_PWR" SG_ 416 BR1_Rad_kmh 500;
BA_ "GenSigTimeoutMsg_Hybrid_PWR" SG_ 416 BR1_Rad_kmh 416;
BA_ "GenSigTimeoutTime_Lenkhilfe_ZF_3" SG_ 416 BR1_Rad_kmh 500;
BA_ "GenSigTimeoutMsg_Lenkhilfe_ZF_3" SG_ 416 BR1_Rad_kmh 416;
BA_ "GenSigTimeoutTime_ACC_Lidar" SG_ 416 BR1_Rad_kmh 500;
BA_ "GenSigTimeoutMsg_ACC_Lidar" SG_ 416 BR1_Rad_kmh 416;
BA_ "GenSigTimeoutTime_Selespeed" SG_ 416 BR1_Rad_kmh 500;
BA_ "GenSigTimeoutMsg_Selespeed" SG_ 416 BR1_Rad_kmh 416;
BA_ "GenSigTimeoutTime_SWA" SG_ 416 BR1_Rad_kmh 500;
BA_ "GenSigTimeoutMsg_SWA" SG_ 416 BR1_Rad_kmh 416;
BA_ "GenSigTimeoutTime_HCA" SG_ 416 BR1_Rad_kmh 500;
BA_ "GenSigTimeoutMsg_HCA" SG_ 416 BR1_Rad_kmh 416;
BA_ "GenSigTimeoutTime_Hybrid_BMS" SG_ 416 BR1_Rad_kmh 500;
BA_ "GenSigTimeoutMsg_Hybrid_BMS" SG_ 416 BR1_Rad_kmh 416;
BA_ "GenSigTimeoutTime_Hybrid_MSG" SG_ 416 BR1_Rad_kmh 500;
BA_ "GenSigTimeoutMsg_Hybrid_MSG" SG_ 416 BR1_Rad_kmh 416;
BA_ "GenSigTimeoutTime_Daempfer" SG_ 416 BR1_Rad_kmh 500;
BA_ "GenSigTimeoutMsg_Daempfer" SG_ 416 BR1_Rad_kmh 416;
BA_ "GenSigTimeoutTime_Lenkhilfe_APA" SG_ 416 BR1_Rad_kmh 500;
BA_ "GenSigTimeoutMsg_Lenkhilfe_APA" SG_ 416 BR1_Rad_kmh 416;
BA_ "GenSigTimeoutTime_PDC_PLA" SG_ 416 BR1_Rad_kmh 500;
BA_ "GenSigTimeoutMsg_PDC_PLA" SG_ 416 BR1_Rad_kmh 416;
BA_ "GenSigTimeoutTime_Magne_Ride" SG_ 416 BR1_Rad_kmh 500;
BA_ "GenSigTimeoutMsg_Magne_Ride" SG_ 416 BR1_Rad_kmh 416;
BA_ "GenSigTimeoutTime_Gateway_PQ35_A" SG_ 416 BR1_Rad_kmh 500;
BA_ "GenSigTimeoutMsg_Gateway_PQ35_A" SG_ 416 BR1_Rad_kmh 416;
BA_ "GenSigTimeoutTime_ACC_Radar" SG_ 416 BR1_Rad_kmh 500;
BA_ "GenSigTimeoutMsg_ACC_Radar" SG_ 416 BR1_Rad_kmh 416;
BA_ "GenSigTimeoutTime_EPB" SG_ 416 BR1_Rad_kmh 500;
BA_ "GenSigTimeoutMsg_EPB" SG_ 416 BR1_Rad_kmh 416;
BA_ "GenSigTimeoutTime_Otto" SG_ 416 BR1_Rad_kmh 500;
BA_ "GenSigTimeoutMsg_Otto" SG_ 416 BR1_Rad_kmh 416;
BA_ "GenSigTimeoutTime_Lenkhilfe_ZF_2" SG_ 416 BR1_Rad_kmh 500;
BA_ "GenSigTimeoutMsg_Lenkhilfe_ZF_2" SG_ 416 BR1_Rad_kmh 416;
BA_ "GenSigTimeoutTime_Diesel" SG_ 416 BR1_Rad_kmh 500;
BA_ "GenSigTimeoutMsg_Diesel" SG_ 416 BR1_Rad_kmh 416;
BA_ "GenSigTimeoutTime_Gateway_PQ46_A" SG_ 416 BR1_Rad_kmh 500;
BA_ "GenSigTimeoutMsg_Gateway_PQ46_A" SG_ 416 BR1_Rad_kmh 416;
BA_ "GenSigTimeoutTime_Airbag" SG_ 416 BR1_Rad_kmh 500;
BA_ "GenSigTimeoutMsg_Airbag" SG_ 416 BR1_Rad_kmh 416;
BA_ "GenSigTimeoutTime_AG6" SG_ 416 BR1_Rad_kmh 500;
BA_ "GenSigTimeoutMsg_AG6" SG_ 416 BR1_Rad_kmh 416;
BA_ "GenSigSendType" SG_ 416 BR1_Rad_kmh 0;
BA_ "GenSigStartValue" SG_ 416 BR1_Rad_kmh 32708;
BA_ "GenSigTimeoutTime_Diesel" SG_ 416 BR1_ESPASR_passiv 500;
BA_ "GenSigTimeoutMsg_Diesel" SG_ 416 BR1_ESPASR_passiv 416;
BA_ "GenSigTimeoutTime_Otto" SG_ 416 BR1_ESPASR_passiv 500;
BA_ "GenSigTimeoutMsg_Otto" SG_ 416 BR1_ESPASR_passiv 416;
BA_ "GenSigTimeoutTime_ACC_Lidar" SG_ 416 BR1_ESPASR_passiv 500;
BA_ "GenSigTimeoutMsg_ACC_Lidar" SG_ 416 BR1_ESPASR_passiv 416;
BA_ "GenSigTimeoutTime_HCA" SG_ 416 BR1_ESPASR_passiv 500;
BA_ "GenSigTimeoutMsg_HCA" SG_ 416 BR1_ESPASR_passiv 416;
BA_ "GenSigTimeoutTime_Selespeed" SG_ 416 BR1_ESPASR_passiv 500;
BA_ "GenSigTimeoutMsg_Selespeed" SG_ 416 BR1_ESPASR_passiv 416;
BA_ "GenSigTimeoutTime_Hybrid_DQ200" SG_ 416 BR1_ESPASR_passiv 500;
BA_ "GenSigTimeoutMsg_Hybrid_DQ200" SG_ 416 BR1_ESPASR_passiv 416;
BA_ "GenSigTimeoutTime_PDC_PLA" SG_ 416 BR1_ESPASR_passiv 500;
BA_ "GenSigTimeoutMsg_PDC_PLA" SG_ 416 BR1_ESPASR_passiv 416;
BA_ "GenSigTimeoutTime_Magne_Ride" SG_ 416 BR1_ESPASR_passiv 500;
BA_ "GenSigTimeoutMsg_Magne_Ride" SG_ 416 BR1_ESPASR_passiv 416;
BA_ "GenSigTimeoutTime_Gateway_PQ35_A" SG_ 416 BR1_ESPASR_passiv 500;
BA_ "GenSigTimeoutMsg_Gateway_PQ35_A" SG_ 416 BR1_ESPASR_passiv 416;
BA_ "GenSigTimeoutTime_ACC_Radar" SG_ 416 BR1_ESPASR_passiv 500;
BA_ "GenSigTimeoutMsg_ACC_Radar" SG_ 416 BR1_ESPASR_passiv 416;
BA_ "GenSigTimeoutTime_DQ" SG_ 416 BR1_ESPASR_passiv 500;
BA_ "GenSigTimeoutMsg_DQ" SG_ 416 BR1_ESPASR_passiv 416;
BA_ "GenSigTimeoutTime_Gateway_PQ46_A" SG_ 416 BR1_ESPASR_passiv 500;
BA_ "GenSigTimeoutMsg_Gateway_PQ46_A" SG_ 416 BR1_ESPASR_passiv 416;
BA_ "GenSigSendType" SG_ 416 BR1_ESPASR_passiv 0;
BA_ "GenSigTimeoutTime_ACC_Lidar" SG_ 416 BR1_Sta_ESP 500;
BA_ "GenSigTimeoutMsg_ACC_Lidar" SG_ 416 BR1_Sta_ESP 416;
BA_ "GenSigTimeoutTime_Otto" SG_ 416 BR1_Sta_ESP 500;
BA_ "GenSigTimeoutMsg_Otto" SG_ 416 BR1_Sta_ESP 416;
BA_ "GenSigTimeoutTime_PDC_PLA" SG_ 416 BR1_Sta_ESP 500;
BA_ "GenSigTimeoutMsg_PDC_PLA" SG_ 416 BR1_Sta_ESP 416;
BA_ "GenSigTimeoutTime_Hybrid_DQ200" SG_ 416 BR1_Sta_ESP 500;
BA_ "GenSigTimeoutMsg_Hybrid_DQ200" SG_ 416 BR1_Sta_ESP 416;
BA_ "GenSigTimeoutTime_RKA_Plus" SG_ 416 BR1_Sta_ESP 500;
BA_ "GenSigTimeoutMsg_RKA_Plus" SG_ 416 BR1_Sta_ESP 416;
BA_ "GenSigTimeoutTime_Magne_Ride" SG_ 416 BR1_Sta_ESP 500;
BA_ "GenSigTimeoutMsg_Magne_Ride" SG_ 416 BR1_Sta_ESP 416;
BA_ "GenSigTimeoutTime_Gateway_PQ35_A" SG_ 416 BR1_Sta_ESP 500;
BA_ "GenSigTimeoutMsg_Gateway_PQ35_A" SG_ 416 BR1_Sta_ESP 416;
BA_ "GenSigTimeoutTime_ACC_Radar" SG_ 416 BR1_Sta_ESP 500;
BA_ "GenSigTimeoutMsg_ACC_Radar" SG_ 416 BR1_Sta_ESP 416;
BA_ "GenSigTimeoutTime_DQ" SG_ 416 BR1_Sta_ESP 500;
BA_ "GenSigTimeoutMsg_DQ" SG_ 416 BR1_Sta_ESP 416;
BA_ "GenSigTimeoutTime_Diesel" SG_ 416 BR1_Sta_ESP 500;
BA_ "GenSigTimeoutMsg_Diesel" SG_ 416 BR1_Sta_ESP 416;
BA_ "GenSigTimeoutTime_Gateway_PQ46_A" SG_ 416 BR1_Sta_ESP 500;
BA_ "GenSigTimeoutMsg_Gateway_PQ46_A" SG_ 416 BR1_Sta_ESP 416;
BA_ "GenSigTimeoutTime_AG6" SG_ 416 BR1_Sta_ESP 500;
BA_ "GenSigTimeoutMsg_AG6" SG_ 416 BR1_Sta_ESP 416;
BA_ "GenSigSendType" SG_ 416 BR1_Sta_ESP 0;
BA_ "GenSigTimeoutTime_Diesel" SG_ 416 BR1_ASR_ESP 500;
BA_ "GenSigTimeoutMsg_Diesel" SG_ 416 BR1_ASR_ESP 416;
BA_ "GenSigTimeoutTime_Hybrid_MSG" SG_ 416 BR1_ASR_ESP 500;
BA_ "GenSigTimeoutMsg_Hybrid_MSG" SG_ 416 BR1_ASR_ESP 416;
BA_ "GenSigTimeoutTime_Gateway_PQ35_A" SG_ 416 BR1_ASR_ESP 500;
BA_ "GenSigTimeoutMsg_Gateway_PQ35_A" SG_ 416 BR1_ASR_ESP 416;
BA_ "GenSigTimeoutTime_Otto" SG_ 416 BR1_ASR_ESP 500;
BA_ "GenSigTimeoutMsg_Otto" SG_ 416 BR1_ASR_ESP 416;
BA_ "GenSigTimeoutTime_Gateway_PQ46_A" SG_ 416 BR1_ASR_ESP 500;
BA_ "GenSigTimeoutMsg_Gateway_PQ46_A" SG_ 416 BR1_ASR_ESP 416;
BA_ "GenSigSendType" SG_ 416 BR1_ASR_ESP 0;
BA_ "INIT" SG_ 416 BR1_ASR_ESP "const";
BA_ "GenSigTimeoutTime_Lenkhilfe_ZF_3" SG_ 416 BR1_Zaehler 500;
BA_ "GenSigTimeoutMsg_Lenkhilfe_ZF_3" SG_ 416 BR1_Zaehler 416;
BA_ "GenSigTimeoutTime_Lenkhilfe_ZF_2" SG_ 416 BR1_Zaehler 500;
BA_ "GenSigTimeoutMsg_Lenkhilfe_ZF_2" SG_ 416 BR1_Zaehler 416;
BA_ "GenSigTimeoutTime_Lenkhilfe_APA" SG_ 416 BR1_Zaehler 500;
BA_ "GenSigTimeoutMsg_Lenkhilfe_APA" SG_ 416 BR1_Zaehler 416;
BA_ "GenSigTimeoutTime_ACC_Lidar" SG_ 416 BR1_Zaehler 500;
BA_ "GenSigTimeoutMsg_ACC_Lidar" SG_ 416 BR1_Zaehler 416;
BA_ "GenSigTimeoutTime_SWA" SG_ 416 BR1_Zaehler 500;
BA_ "GenSigTimeoutMsg_SWA" SG_ 416 BR1_Zaehler 416;
BA_ "GenSigTimeoutTime_HCA" SG_ 416 BR1_Zaehler 500;
BA_ "GenSigTimeoutMsg_HCA" SG_ 416 BR1_Zaehler 416;
BA_ "GenSigTimeoutTime_Hybrid_MSG" SG_ 416 BR1_Zaehler 500;
BA_ "GenSigTimeoutMsg_Hybrid_MSG" SG_ 416 BR1_Zaehler 416;
BA_ "GenSigTimeoutTime_Daempfer" SG_ 416 BR1_Zaehler 500;
BA_ "GenSigTimeoutMsg_Daempfer" SG_ 416 BR1_Zaehler 416;
BA_ "GenSigTimeoutTime_PDC_PLA" SG_ 416 BR1_Zaehler 500;
BA_ "GenSigTimeoutMsg_PDC_PLA" SG_ 416 BR1_Zaehler 416;
BA_ "GenSigTimeoutTime_Magne_Ride" SG_ 416 BR1_Zaehler 500;
BA_ "GenSigTimeoutMsg_Magne_Ride" SG_ 416 BR1_Zaehler 416;
BA_ "GenSigTimeoutTime_Gateway_PQ35_A" SG_ 416 BR1_Zaehler 500;
BA_ "GenSigTimeoutMsg_Gateway_PQ35_A" SG_ 416 BR1_Zaehler 416;
BA_ "GenSigTimeoutTime_ACC_Radar" SG_ 416 BR1_Zaehler 500;
BA_ "GenSigTimeoutMsg_ACC_Radar" SG_ 416 BR1_Zaehler 416;
BA_ "GenSigTimeoutTime_EPB" SG_ 416 BR1_Zaehler 500;
BA_ "GenSigTimeoutMsg_EPB" SG_ 416 BR1_Zaehler 416;
BA_ "GenSigTimeoutTime_Otto" SG_ 416 BR1_Zaehler 500;
BA_ "GenSigTimeoutMsg_Otto" SG_ 416 BR1_Zaehler 416;
BA_ "GenSigTimeoutTime_Diesel" SG_ 416 BR1_Zaehler 500;
BA_ "GenSigTimeoutMsg_Diesel" SG_ 416 BR1_Zaehler 416;
BA_ "GenSigTimeoutTime_Gateway_PQ46_A" SG_ 416 BR1_Zaehler 500;
BA_ "GenSigTimeoutMsg_Gateway_PQ46_A" SG_ 416 BR1_Zaehler 416;
BA_ "GenSigTimeoutTime_Airbag" SG_ 416 BR1_Zaehler 500;
BA_ "GenSigTimeoutMsg_Airbag" SG_ 416 BR1_Zaehler 416;
BA_ "GenSigTimeoutTime_AG6" SG_ 416 BR1_Zaehler 500;
BA_ "GenSigTimeoutMsg_AG6" SG_ 416 BR1_Zaehler 416;
BA_ "GenSigSendType" SG_ 416 BR1_Zaehler 0;
BA_ "GenSigTimeoutTime_Lenkhilfe_ZF_3" SG_ 416 BR1_Ersatz_Kmh 500;
BA_ "GenSigTimeoutMsg_Lenkhilfe_ZF_3" SG_ 416 BR1_Ersatz_Kmh 416;
BA_ "GenSigTimeoutTime_Lenkhilfe_ZF_2" SG_ 416 BR1_Ersatz_Kmh 500;
BA_ "GenSigTimeoutMsg_Lenkhilfe_ZF_2" SG_ 416 BR1_Ersatz_Kmh 416;
BA_ "GenSigTimeoutTime_Lenkhilfe_APA" SG_ 416 BR1_Ersatz_Kmh 500;
BA_ "GenSigTimeoutMsg_Lenkhilfe_APA" SG_ 416 BR1_Ersatz_Kmh 416;
BA_ "GenSigTimeoutTime_HCA" SG_ 416 BR1_Ersatz_Kmh 500;
BA_ "GenSigTimeoutMsg_HCA" SG_ 416 BR1_Ersatz_Kmh 416;
BA_ "GenSigTimeoutTime_Hybrid_MSG" SG_ 416 BR1_Ersatz_Kmh 500;
BA_ "GenSigTimeoutMsg_Hybrid_MSG" SG_ 416 BR1_Ersatz_Kmh 416;
BA_ "GenSigTimeoutTime_PDC_PLA" SG_ 416 BR1_Ersatz_Kmh 500;
BA_ "GenSigTimeoutMsg_PDC_PLA" SG_ 416 BR1_Ersatz_Kmh 416;
BA_ "GenSigTimeoutTime_Gateway_PQ35_A" SG_ 416 BR1_Ersatz_Kmh 500;
BA_ "GenSigTimeoutMsg_Gateway_PQ35_A" SG_ 416 BR1_Ersatz_Kmh 416;
BA_ "GenSigTimeoutTime_Otto" SG_ 416 BR1_Ersatz_Kmh 500;
BA_ "GenSigTimeoutMsg_Otto" SG_ 416 BR1_Ersatz_Kmh 416;
BA_ "GenSigTimeoutTime_Gateway_PQ46_A" SG_ 416 BR1_Ersatz_Kmh 500;
BA_ "GenSigTimeoutMsg_Gateway_PQ46_A" SG_ 416 BR1_Ersatz_Kmh 416;
BA_ "GenSigTimeoutTime_Airbag" SG_ 416 BR1_Ersatz_Kmh 500;
BA_ "GenSigTimeoutMsg_Airbag" SG_ 416 BR1_Ersatz_Kmh 416;
BA_ "GenSigSendType" SG_ 416 BR1_Ersatz_Kmh 0;
BA_ "GenSigStartValue" SG_ 416 BR1_Ersatz_Kmh 1;
BA_ "GenSigTimeoutTime_Hybrid_MSG" SG_ 416 BR1_MSR_Mo_inv 500;
BA_ "GenSigTimeoutMsg_Hybrid_MSG" SG_ 416 BR1_MSR_Mo_inv 416;
BA_ "GenSigTimeoutTime_Gateway_PQ35_A" SG_ 416 BR1_MSR_Mo_inv 500;
BA_ "GenSigTimeoutMsg_Gateway_PQ35_A" SG_ 416 BR1_MSR_Mo_inv 416;
BA_ "GenSigTimeoutTime_Otto" SG_ 416 BR1_MSR_Mo_inv 500;
BA_ "GenSigTimeoutMsg_Otto" SG_ 416 BR1_MSR_Mo_inv 416;
BA_ "GenSigTimeoutTime_Diesel" SG_ 416 BR1_MSR_Mo_inv 500;
BA_ "GenSigTimeoutMsg_Diesel" SG_ 416 BR1_MSR_Mo_inv 416;
BA_ "GenSigTimeoutTime_Gateway_PQ46_A" SG_ 416 BR1_MSR_Mo_inv 500;
BA_ "GenSigTimeoutMsg_Gateway_PQ46_A" SG_ 416 BR1_MSR_Mo_inv 416;
BA_ "GenSigSendType" SG_ 416 BR1_MSR_Mo_inv 0;
BA_ "GenSigStartValue" SG_ 416 BR1_MSR_Mo_inv 255;
BA_ "GenSigTimeoutTime_Lenkhilfe_APA" SG_ 416 BR1_EDS_Eingr 500;
BA_ "GenSigTimeoutMsg_Lenkhilfe_APA" SG_ 416 BR1_EDS_Eingr 416;
BA_ "GenSigTimeoutTime_ACC_Lidar" SG_ 416 BR1_EDS_Eingr 500;
BA_ "GenSigTimeoutMsg_ACC_Lidar" SG_ 416 BR1_EDS_Eingr 416;
BA_ "GenSigTimeoutTime_Hybrid_DQ200" SG_ 416 BR1_EDS_Eingr 500;
BA_ "GenSigTimeoutMsg_Hybrid_DQ200" SG_ 416 BR1_EDS_Eingr 416;
BA_ "GenSigTimeoutTime_Daempfer" SG_ 416 BR1_EDS_Eingr 500;
BA_ "GenSigTimeoutMsg_Daempfer" SG_ 416 BR1_EDS_Eingr 416;
BA_ "GenSigTimeoutTime_PDC_PLA" SG_ 416 BR1_EDS_Eingr 500;
BA_ "GenSigTimeoutMsg_PDC_PLA" SG_ 416 BR1_EDS_Eingr 416;
BA_ "GenSigTimeoutTime_RKA_Plus" SG_ 416 BR1_EDS_Eingr 500;
BA_ "GenSigTimeoutMsg_RKA_Plus" SG_ 416 BR1_EDS_Eingr 416;
BA_ "GenSigTimeoutTime_Gateway_PQ35_A" SG_ 416 BR1_EDS_Eingr 500;
BA_ "GenSigTimeoutMsg_Gateway_PQ35_A" SG_ 416 BR1_EDS_Eingr 416;
BA_ "GenSigTimeoutTime_ACC_Radar" SG_ 416 BR1_EDS_Eingr 500;
BA_ "GenSigTimeoutMsg_ACC_Radar" SG_ 416 BR1_EDS_Eingr 416;
BA_ "GenSigTimeoutTime_DQ" SG_ 416 BR1_EDS_Eingr 500;
BA_ "GenSigTimeoutMsg_DQ" SG_ 416 BR1_EDS_Eingr 416;
BA_ "GenSigTimeoutTime_Diesel" SG_ 416 BR1_EDS_Eingr 500;
BA_ "GenSigTimeoutMsg_Diesel" SG_ 416 BR1_EDS_Eingr 416;
BA_ "GenSigTimeoutTime_Gateway_PQ46_A" SG_ 416 BR1_EDS_Eingr 500;
BA_ "GenSigTimeoutMsg_Gateway_PQ46_A" SG_ 416 BR1_EDS_Eingr 416;
BA_ "GenSigTimeoutTime_Airbag" SG_ 416 BR1_EDS_Eingr 500;
BA_ "GenSigTimeoutMsg_Airbag" SG_ 416 BR1_EDS_Eingr 416;
BA_ "GenSigSendType" SG_ 416 BR1_EDS_Eingr 0;
BA_ "GenSigTimeoutTime_Hybrid_DQ200" SG_ 1440 BR2_mi_Radgeschw 500;
BA_ "GenSigTimeoutMsg_Hybrid_DQ200" SG_ 1440 BR2_mi_Radgeschw 1440;
BA_ "GenSigTimeoutTime_Gateway_PQ35_A" SG_ 1440 BR2_mi_Radgeschw 500;
BA_ "GenSigTimeoutMsg_Gateway_PQ35_A" SG_ 1440 BR2_mi_Radgeschw 1440;
BA_ "GenSigTimeoutTime_DQ" SG_ 1440 BR2_mi_Radgeschw 500;
BA_ "GenSigTimeoutMsg_DQ" SG_ 1440 BR2_mi_Radgeschw 1440;
BA_ "GenSigTimeoutTime_Gateway_PQ46_A" SG_ 1440 BR2_mi_Radgeschw 500;
BA_ "GenSigTimeoutMsg_Gateway_PQ46_A" SG_ 1440 BR2_mi_Radgeschw 1440;
BA_ "GenSigSendType" SG_ 1440 BR2_mi_Radgeschw 0;
BA_ "GenSigStartValue" SG_ 1440 BR2_mi_Radgeschw 32708;
BA_ "GenSigTimeoutTime_Otto" SG_ 1440 BR2_QB_Querbeschl 500;
BA_ "GenSigTimeoutMsg_Otto" SG_ 1440 BR2_QB_Querbeschl 1440;
BA_ "GenSigTimeoutTime_Diesel" SG_ 1440 BR2_QB_Querbeschl 500;
BA_ "GenSigTimeoutMsg_Diesel" SG_ 1440 BR2_QB_Querbeschl 1440;
BA_ "GenSigTimeoutTime_HCA" SG_ 1440 BR2_QB_Querbeschl 500;
BA_ "GenSigTimeoutMsg_HCA" SG_ 1440 BR2_QB_Querbeschl 1440;
BA_ "GenSigTimeoutTime_Allrad" SG_ 1440 BR2_QB_Querbeschl 500;
BA_ "GenSigTimeoutMsg_Allrad" SG_ 1440 BR2_QB_Querbeschl 1440;
BA_ "GenSigTimeoutTime_RKA_Plus" SG_ 1440 BR2_QB_Querbeschl 500;
BA_ "GenSigTimeoutMsg_RKA_Plus" SG_ 1440 BR2_QB_Querbeschl 1440;
BA_ "GenSigTimeoutTime_Magne_Ride" SG_ 1440 BR2_QB_Querbeschl 500;
BA_ "GenSigTimeoutMsg_Magne_Ride" SG_ 1440 BR2_QB_Querbeschl 1440;
BA_ "GenSigTimeoutTime_Gateway_PQ35_A" SG_ 1440 BR2_QB_Querbeschl 500;
BA_ "GenSigTimeoutMsg_Gateway_PQ35_A" SG_ 1440 BR2_QB_Querbeschl 1440;
BA_ "GenSigTimeoutTime_Gateway_PQ46_A" SG_ 1440 BR2_QB_Querbeschl 500;
BA_ "GenSigTimeoutMsg_Gateway_PQ46_A" SG_ 1440 BR2_QB_Querbeschl 1440;
BA_ "GenSigSendType" SG_ 1440 BR2_QB_Querbeschl 0;
BA_ "GenSigStartValue" SG_ 1440 BR2_QB_Querbeschl 1;
BA_ "GenSigTimeoutTime_Allrad" SG_ 1440 BR2_Querb_Zahn 500;
BA_ "GenSigTimeoutMsg_Allrad" SG_ 1440 BR2_Querb_Zahn 1440;
BA_ "GenSigTimeoutTime_Selespeed" SG_ 1440 BR2_Querb_Zahn 500;
BA_ "GenSigTimeoutMsg_Selespeed" SG_ 1440 BR2_Querb_Zahn 1440;
BA_ "GenSigTimeoutTime_HCA" SG_ 1440 BR2_Querb_Zahn 500;
BA_ "GenSigTimeoutMsg_HCA" SG_ 1440 BR2_Querb_Zahn 1440;
BA_ "GenSigTimeoutTime_Otto" SG_ 1440 BR2_Querb_Zahn 500;
BA_ "GenSigTimeoutMsg_Otto" SG_ 1440 BR2_Querb_Zahn 1440;
BA_ "GenSigTimeoutTime_Hybrid_DQ200" SG_ 1440 BR2_Querb_Zahn 500;
BA_ "GenSigTimeoutMsg_Hybrid_DQ200" SG_ 1440 BR2_Querb_Zahn 1440;
BA_ "GenSigTimeoutTime_Daempfer" SG_ 1440 BR2_Querb_Zahn 500;
BA_ "GenSigTimeoutMsg_Daempfer" SG_ 1440 BR2_Querb_Zahn 1440;
BA_ "GenSigTimeoutTime_PDC_PLA" SG_ 1440 BR2_Querb_Zahn 500;
BA_ "GenSigTimeoutMsg_PDC_PLA" SG_ 1440 BR2_Querb_Zahn 1440;
BA_ "GenSigTimeoutTime_RKA_Plus" SG_ 1440 BR2_Querb_Zahn 500;
BA_ "GenSigTimeoutMsg_RKA_Plus" SG_ 1440 BR2_Querb_Zahn 1440;
BA_ "GenSigTimeoutTime_Magne_Ride" SG_ 1440 BR2_Querb_Zahn 500;
BA_ "GenSigTimeoutMsg_Magne_Ride" SG_ 1440 BR2_Querb_Zahn 1440;
BA_ "GenSigTimeoutTime_Gateway_PQ35_A" SG_ 1440 BR2_Querb_Zahn 500;
BA_ "GenSigTimeoutMsg_Gateway_PQ35_A" SG_ 1440 BR2_Querb_Zahn 1440;
BA_ "GenSigTimeoutTime_DQ" SG_ 1440 BR2_Querb_Zahn 500;
BA_ "GenSigTimeoutMsg_DQ" SG_ 1440 BR2_Querb_Zahn 1440;
BA_ "GenSigTimeoutTime_Diesel" SG_ 1440 BR2_Querb_Zahn 500;
BA_ "GenSigTimeoutMsg_Diesel" SG_ 1440 BR2_Querb_Zahn 1440;
BA_ "GenSigTimeoutTime_Gateway_PQ46_A" SG_ 1440 BR2_Querb_Zahn 500;
BA_ "GenSigTimeoutMsg_Gateway_PQ46_A" SG_ 1440 BR2_Querb_Zahn 1440;
BA_ "GenSigSendType" SG_ 1440 BR2_Querb_Zahn 0;
BA_ "GenSigStartValue" SG_ 1440 BR2_Querb_Zahn 1;
BA_ "GenSigTimeoutTime_Allrad" SG_ 1440 BR2_Querbeschl 500;
BA_ "GenSigTimeoutMsg_Allrad" SG_ 1440 BR2_Querbeschl 1440;
BA_ "GenSigTimeoutTime_Selespeed" SG_ 1440 BR2_Querbeschl 500;
BA_ "GenSigTimeoutMsg_Selespeed" SG_ 1440 BR2_Querbeschl 1440;
BA_ "GenSigTimeoutTime_HCA" SG_ 1440 BR2_Querbeschl 500;
BA_ "GenSigTimeoutMsg_HCA" SG_ 1440 BR2_Querbeschl 1440;
BA_ "GenSigTimeoutTime_Otto" SG_ 1440 BR2_Querbeschl 500;
BA_ "GenSigTimeoutMsg_Otto" SG_ 1440 BR2_Querbeschl 1440;
BA_ "GenSigTimeoutTime_Hybrid_DQ200" SG_ 1440 BR2_Querbeschl 500;
BA_ "GenSigTimeoutMsg_Hybrid_DQ200" SG_ 1440 BR2_Querbeschl 1440;
BA_ "GenSigTimeoutTime_Daempfer" SG_ 1440 BR2_Querbeschl 500;
BA_ "GenSigTimeoutMsg_Daempfer" SG_ 1440 BR2_Querbeschl 1440;
BA_ "GenSigTimeoutTime_RKA_Plus" SG_ 1440 BR2_Querbeschl 500;
BA_ "GenSigTimeoutMsg_RKA_Plus" SG_ 1440 BR2_Querbeschl 1440;
BA_ "GenSigTimeoutTime_Magne_Ride" SG_ 1440 BR2_Querbeschl 500;
BA_ "GenSigTimeoutMsg_Magne_Ride" SG_ 1440 BR2_Querbeschl 1440;
BA_ "GenSigTimeoutTime_Gateway_PQ35_A" SG_ 1440 BR2_Querbeschl 500;
BA_ "GenSigTimeoutMsg_Gateway_PQ35_A" SG_ 1440 BR2_Querbeschl 1440;
BA_ "GenSigTimeoutTime_DQ" SG_ 1440 BR2_Querbeschl 500;
BA_ "GenSigTimeoutMsg_DQ" SG_ 1440 BR2_Querbeschl 1440;
BA_ "GenSigTimeoutTime_Diesel" SG_ 1440 BR2_Querbeschl 500;
BA_ "GenSigTimeoutMsg_Diesel" SG_ 1440 BR2_Querbeschl 1440;
BA_ "GenSigTimeoutTime_Gateway_PQ46_A" SG_ 1440 BR2_Querbeschl 500;
BA_ "GenSigTimeoutMsg_Gateway_PQ46_A" SG_ 1440 BR2_Querbeschl 1440;
BA_ "GenSigSendType" SG_ 1440 BR2_Querbeschl 0;
BA_ "GenSigStartValue" SG_ 1440 BR2_Querbeschl 127;
BA_ "GenSigTimeoutTime_ACC_Lidar" SG_ 1440 BR2_Ueberl_Imp 500;
BA_ "GenSigTimeoutMsg_ACC_Lidar" SG_ 1440 BR2_Ueberl_Imp 1440;
BA_ "GenSigTimeoutTime_SWA" SG_ 1440 BR2_Ueberl_Imp 500;
BA_ "GenSigTimeoutMsg_SWA" SG_ 1440 BR2_Ueberl_Imp 1440;
BA_ "GenSigTimeoutTime_Gateway_PQ35_A" SG_ 1440 BR2_Ueberl_Imp 500;
BA_ "GenSigTimeoutMsg_Gateway_PQ35_A" SG_ 1440 BR2_Ueberl_Imp 1440;
BA_ "GenSigTimeoutTime_ACC_Radar" SG_ 1440 BR2_Ueberl_Imp 500;
BA_ "GenSigTimeoutMsg_ACC_Radar" SG_ 1440 BR2_Ueberl_Imp 1440;
BA_ "GenSigTimeoutTime_Gateway_PQ46_A" SG_ 1440 BR2_Ueberl_Imp 500;
BA_ "GenSigTimeoutMsg_Gateway_PQ46_A" SG_ 1440 BR2_Ueberl_Imp 1440;
BA_ "GenSigSendType" SG_ 1440 BR2_Ueberl_Imp 0;
BA_ "GenSigTimeoutTime_Gateway_PQ35_A" SG_ 1440 BR2_Fehlereintr 500;
BA_ "GenSigTimeoutMsg_Gateway_PQ35_A" SG_ 1440 BR2_Fehlereintr 1440;
BA_ "GenSigTimeoutTime_Gateway_PQ46_A" SG_ 1440 BR2_Fehlereintr 500;
BA_ "GenSigTimeoutMsg_Gateway_PQ46_A" SG_ 1440 BR2_Fehlereintr 1440;
BA_ "GenSigSendType" SG_ 1440 BR2_Fehlereintr 0;
BA_ "GenSigTimeoutTime_SWA" SG_ 1440 BR2_Impulszahl 500;
BA_ "GenSigTimeoutMsg_SWA" SG_ 1440 BR2_Impulszahl 1440;
BA_ "GenSigTimeoutTime_Gateway_PQ35_A" SG_ 1440 BR2_Impulszahl 500;
BA_ "GenSigTimeoutMsg_Gateway_PQ35_A" SG_ 1440 BR2_Impulszahl 1440;
BA_ "GenSigTimeoutTime_Gateway_PQ46_A" SG_ 1440 BR2_Impulszahl 500;
BA_ "GenSigTimeoutMsg_Gateway_PQ46_A" SG_ 1440 BR2_Impulszahl 1440;
BA_ "GenSigSendType" SG_ 1440 BR2_Impulszahl 0;
BA_ "INIT" SG_ 1440 BR2_Impulszahl "const";
BA_ "GenSigTimeoutTime_Gateway_PQ35_A" SG_ 1440 BR2_LampeHDC 500;
BA_ "GenSigTimeoutMsg_Gateway_PQ35_A" SG_ 1440 BR2_LampeHDC 1440;
BA_ "GenSigTimeoutTime_Gateway_PQ46_A" SG_ 1440 BR2_LampeHDC 500;
BA_ "GenSigTimeoutMsg_Gateway_PQ46_A" SG_ 1440 BR2_LampeHDC 1440;
BA_ "GenSigSendType" SG_ 1440 BR2_LampeHDC 0;
BA_ "GenSigTimeoutTime_ACC_Lidar" SG_ 1440 BR2_Sta_Imp 500;
BA_ "GenSigTimeoutMsg_ACC_Lidar" SG_ 1440 BR2_Sta_Imp 1440;
BA_ "GenSigTimeoutTime_SWA" SG_ 1440 BR2_Sta_Imp 500;
BA_ "GenSigTimeoutMsg_SWA" SG_ 1440 BR2_Sta_Imp 1440;
BA_ "GenSigTimeoutTime_Gateway_PQ35_A" SG_ 1440 BR2_Sta_Imp 500;
BA_ "GenSigTimeoutMsg_Gateway_PQ35_A" SG_ 1440 BR2_Sta_Imp 1440;
BA_ "GenSigTimeoutTime_ACC_Radar" SG_ 1440 BR2_Sta_Imp 500;
BA_ "GenSigTimeoutMsg_ACC_Radar" SG_ 1440 BR2_Sta_Imp 1440;
BA_ "GenSigTimeoutTime_Gateway_PQ46_A" SG_ 1440 BR2_Sta_Imp 500;
BA_ "GenSigTimeoutMsg_Gateway_PQ46_A" SG_ 1440 BR2_Sta_Imp 1440;
BA_ "GenSigSendType" SG_ 1440 BR2_Sta_Imp 0;
BA_ "GenSigTimeoutTime_Gateway_PQ35_A" SG_ 1440 BR2_Lampe_ASR 500;
BA_ "GenSigTimeoutMsg_Gateway_PQ35_A" SG_ 1440 BR2_Lampe_ASR 1440;
BA_ "GenSigTimeoutTime_Gateway_PQ46_A" SG_ 1440 BR2_Lampe_ASR 500;
BA_ "GenSigTimeoutMsg_Gateway_PQ46_A" SG_ 1440 BR2_Lampe_ASR 1440;
BA_ "GenSigSendType" SG_ 1440 BR2_Lampe_ASR 0;
BA_ "INIT" SG_ 1440 BR2_Lampe_ASR "0/1";
BA_ "GenSigTimeoutTime_Gateway_PQ35_A" SG_ 1440 BR2_SleepInd 500;
BA_ "GenSigTimeoutMsg_Gateway_PQ35_A" SG_ 1440 BR2_SleepInd 1440;
BA_ "GenSigTimeoutTime_Gateway_PQ46_A" SG_ 1440 BR2_SleepInd 500;
BA_ "GenSigTimeoutMsg_Gateway_PQ46_A" SG_ 1440 BR2_SleepInd 1440;
BA_ "GenSigSendType" SG_ 1440 BR2_SleepInd 0;
BA_ "GenSigTimeoutTime_Hybrid_DQ200" SG_ 1440 BR2_Sta_Quer 500;
BA_ "GenSigTimeoutMsg_Hybrid_DQ200" SG_ 1440 BR2_Sta_Quer 1440;
BA_ "GenSigTimeoutTime_Gateway_PQ35_A" SG_ 1440 BR2_Sta_Quer 500;
BA_ "GenSigTimeoutMsg_Gateway_PQ35_A" SG_ 1440 BR2_Sta_Quer 1440;
BA_ "GenSigTimeoutTime_DQ" SG_ 1440 BR2_Sta_Quer 500;
BA_ "GenSigTimeoutMsg_DQ" SG_ 1440 BR2_Sta_Quer 1440;
BA_ "GenSigTimeoutTime_Gateway_PQ46_A" SG_ 1440 BR2_Sta_Quer 500;
BA_ "GenSigTimeoutMsg_Gateway_PQ46_A" SG_ 1440 BR2_Sta_Quer 1440;
BA_ "GenSigSendType" SG_ 1440 BR2_Sta_Quer 0;
BA_ "GenSigTimeoutTime_ACC_Lidar" SG_ 1440 BR2_Wegimpulse 500;
BA_ "GenSigTimeoutMsg_ACC_Lidar" SG_ 1440 BR2_Wegimpulse 1440;
BA_ "GenSigTimeoutTime_SWA" SG_ 1440 BR2_Wegimpulse 500;
BA_ "GenSigTimeoutMsg_SWA" SG_ 1440 BR2_Wegimpulse 1440;
BA_ "GenSigTimeoutTime_Gateway_PQ35_A" SG_ 1440 BR2_Wegimpulse 500;
BA_ "GenSigTimeoutMsg_Gateway_PQ35_A" SG_ 1440 BR2_Wegimpulse 1440;
BA_ "GenSigTimeoutTime_ACC_Radar" SG_ 1440 BR2_Wegimpulse 500;
BA_ "GenSigTimeoutMsg_ACC_Radar" SG_ 1440 BR2_Wegimpulse 1440;
BA_ "GenSigTimeoutTime_Gateway_PQ46_A" SG_ 1440 BR2_Wegimpulse 500;
BA_ "GenSigTimeoutMsg_Gateway_PQ46_A" SG_ 1440 BR2_Wegimpulse 1440;
BA_ "GenSigSendType" SG_ 1440 BR2_Wegimpulse 0;
BA_ "GenSigTimeoutTime_Gateway_PQ35_A" SG_ 1440 BR2_Aku_Warn 500;
BA_ "GenSigTimeoutMsg_Gateway_PQ35_A" SG_ 1440 BR2_Aku_Warn 1440;
BA_ "GenSigTimeoutTime_Gateway_PQ46_A" SG_ 1440 BR2_Aku_Warn 500;
BA_ "GenSigTimeoutMsg_Gateway_PQ46_A" SG_ 1440 BR2_Aku_Warn 1440;
BA_ "GenSigSendType" SG_ 1440 BR2_Aku_Warn 0;
BA_ "GenSigTimeoutTime_PDC_PLA" SG_ 1440 BR2_Zahnzahl 500;
BA_ "GenSigTimeoutMsg_PDC_PLA" SG_ 1440 BR2_Zahnzahl 1440;
BA_ "GenSigTimeoutTime_RKA_Plus" SG_ 1440 BR2_Zahnzahl 500;
BA_ "GenSigTimeoutMsg_RKA_Plus" SG_ 1440 BR2_Zahnzahl 1440;
BA_ "GenSigTimeoutTime_Gateway_PQ35_A" SG_ 1440 BR2_Zahnzahl 500;
BA_ "GenSigTimeoutMsg_Gateway_PQ35_A" SG_ 1440 BR2_Zahnzahl 1440;
BA_ "GenSigTimeoutTime_Gateway_PQ46_A" SG_ 1440 BR2_Zahnzahl 500;
BA_ "GenSigTimeoutMsg_Gateway_PQ46_A" SG_ 1440 BR2_Zahnzahl 1440;
BA_ "GenSigSendType" SG_ 1440 BR2_Zahnzahl 0;
BA_ "INIT" SG_ 1440 BR2_Zahnzahl "const";
BA_ "GenSigTimeoutTime_Airbag" SG_ 1440 BR2_Lampe_ABS 500;
BA_ "GenSigTimeoutMsg_Airbag" SG_ 1440 BR2_Lampe_ABS 1440;
BA_ "GenSigTimeoutTime_Gateway_PQ35_A" SG_ 1440 BR2_Lampe_ABS 500;
BA_ "GenSigTimeoutMsg_Gateway_PQ35_A" SG_ 1440 BR2_Lampe_ABS 1440;
BA_ "GenSigTimeoutTime_Gateway_PQ46_A" SG_ 1440 BR2_Lampe_ABS 500;
BA_ "GenSigTimeoutMsg_Gateway_PQ46_A" SG_ 1440 BR2_Lampe_ABS 1440;
BA_ "GenSigSendType" SG_ 1440 BR2_Lampe_ABS 0;
BA_ "GenSigStartValue" SG_ 1440 BR2_Lampe_ABS 1;
BA_ "GenSigTimeoutTime_Gateway_PQ35_A" SG_ 1440 BR2_Lampe_BK 500;
BA_ "GenSigTimeoutMsg_Gateway_PQ35_A" SG_ 1440 BR2_Lampe_BK 1440;
BA_ "GenSigTimeoutTime_Gateway_PQ46_A" SG_ 1440 BR2_Lampe_BK 500;
BA_ "GenSigTimeoutMsg_Gateway_PQ46_A" SG_ 1440 BR2_Lampe_BK 1440;
BA_ "GenSigSendType" SG_ 1440 BR2_Lampe_BK 0;
BA_ "GenSigStartValue" SG_ 1440 BR2_Lampe_BK 1;
BA_ "GenSigTimeoutTime_Hybrid_MSG" SG_ 1440 BR2_HDC_aktiv 500;
BA_ "GenSigTimeoutMsg_Hybrid_MSG" SG_ 1440 BR2_HDC_aktiv 1440;
BA_ "GenSigTimeoutTime_Gateway_PQ35_A" SG_ 1440 BR2_HDC_aktiv 500;
BA_ "GenSigTimeoutMsg_Gateway_PQ35_A" SG_ 1440 BR2_HDC_aktiv 1440;
BA_ "GenSigTimeoutTime_Otto" SG_ 1440 BR2_HDC_aktiv 500;
BA_ "GenSigTimeoutMsg_Otto" SG_ 1440 BR2_HDC_aktiv 1440;
BA_ "GenSigTimeoutTime_Diesel" SG_ 1440 BR2_HDC_aktiv 500;
BA_ "GenSigTimeoutMsg_Diesel" SG_ 1440 BR2_HDC_aktiv 1440;
BA_ "GenSigTimeoutTime_Gateway_PQ46_A" SG_ 1440 BR2_HDC_aktiv 500;
BA_ "GenSigTimeoutMsg_Gateway_PQ46_A" SG_ 1440 BR2_HDC_aktiv 1440;
BA_ "GenSigSendType" SG_ 1440 BR2_HDC_aktiv 0;
BA_ "GenSigTimeoutTime_Gateway_PQ35_A" SG_ 1440 BR2_Lampe_RKA 500;
BA_ "GenSigTimeoutMsg_Gateway_PQ35_A" SG_ 1440 BR2_Lampe_RKA 1440;
BA_ "GenSigTimeoutTime_Gateway_PQ46_A" SG_ 1440 BR2_Lampe_RKA 500;
BA_ "GenSigTimeoutMsg_Gateway_PQ46_A" SG_ 1440 BR2_Lampe_RKA 1440;
BA_ "GenSigSendType" SG_ 1440 BR2_Lampe_RKA 0;
BA_ "GenSigTimeoutTime_HCA" SG_ 1440 BR2_Zaehler 500;
BA_ "GenSigTimeoutMsg_HCA" SG_ 1440 BR2_Zaehler 1440;
BA_ "GenSigTimeoutTime_Daempfer" SG_ 1440 BR2_Zaehler 500;
BA_ "GenSigTimeoutMsg_Daempfer" SG_ 1440 BR2_Zaehler 1440;
BA_ "GenSigTimeoutTime_Magne_Ride" SG_ 1440 BR2_Zaehler 500;
BA_ "GenSigTimeoutMsg_Magne_Ride" SG_ 1440 BR2_Zaehler 1440;
BA_ "GenSigTimeoutTime_Gateway_PQ35_A" SG_ 1440 BR2_Zaehler 500;
BA_ "GenSigTimeoutMsg_Gateway_PQ35_A" SG_ 1440 BR2_Zaehler 1440;
BA_ "GenSigTimeoutTime_Gateway_PQ46_A" SG_ 1440 BR2_Zaehler 500;
BA_ "GenSigTimeoutMsg_Gateway_PQ46_A" SG_ 1440 BR2_Zaehler 1440;
BA_ "GenSigSendType" SG_ 1440 BR2_Zaehler 0;
BA_ "GenSigTimeoutTime_Gateway_PQ35_A" SG_ 1440 BR2_Blinkmode 500;
BA_ "GenSigTimeoutMsg_Gateway_PQ35_A" SG_ 1440 BR2_Blinkmode 1440;
BA_ "GenSigTimeoutTime_Gateway_PQ46_A" SG_ 1440 BR2_Blinkmode 500;
BA_ "GenSigTimeoutMsg_Gateway_PQ46_A" SG_ 1440 BR2_Blinkmode 1440;
BA_ "GenSigSendType" SG_ 1440 BR2_Blinkmode 0;
BA_ "GenSigTimeoutTime_Gateway_PQ35_A" SG_ 1440 BR2_Text 500;
BA_ "GenSigTimeoutMsg_Gateway_PQ35_A" SG_ 1440 BR2_Text 1440;
BA_ "GenSigTimeoutTime_Gateway_PQ46_A" SG_ 1440 BR2_Text 500;
BA_ "GenSigTimeoutMsg_Gateway_PQ46_A" SG_ 1440 BR2_Text 1440;
BA_ "GenSigSendType" SG_ 1440 BR2_Text 0;
VAL_ 3221225472 AL1_Begrenzungsmo 255 "Fehler" ;
VAL_ 3221225472 BR2_Sta_BrAssi 1 "ausgefallen_Fehler" 0 "i_O" ;
VAL_ 3221225472 BR2_Querb_TTic 1 "Timer_Skalierung_in_Byte_1" 0 "Querbeschl_In_Byte1" ;
VAL_ 3221225472 EP1_Verschleiss 3 "frei" 2 "Belag_verschlissen" 1 "frei" 0 "Belaege_i_O" ;
VAL_ 3221225472 GE1_Code_MSG 1 "Kodierung_n_ok" 0 "Kodierung_ok" ;
VAL_ 3221225472 GE1_v_halten 1 "Geschwindigkeit_halten" 0 "keine_Anforderung" ;
VAL_ 3221225472 GE1_Mrad_Mk2 255 "Fehler" ;
VAL_ 3221225472 GH1_FreigabeSSK0 1 "Anf_Schliessen_K0" 0 "keine_Anf_Schliessen_K0" ;
VAL_ 3221225472 MO2_Freigabe_Sport 1 "Freigabe" 0 "keine_Freigabe" ;
VAL_ 3221225472 MO7_Ladedruck 255 "Fehler" ;
VAL_ 3221225472 KO1_Warn_Heiss 1 "Warnung" 0 "keine_Warnung" ;
VAL_ 3221225472 KO2_AussT_FehArt 2 "Max_Fehler" 1 "Min_Fehler" 0 "kein_Fehler" ;
VAL_ 3221225472 KO2_Sta_KuehlT 1 "n_iO" 0 "iO" ;
VAL_ 3221225472 KO2_Sta_Oel_T 1 "n_iO" 0 "iO" ;
VAL_ 3221225472 GK1_RDWarn_VL 1 "ja" 0 "nein" ;
VAL_ 3221225472 GK1_RDWarn_VR 1 "ja" 0 "nein" ;
VAL_ 3221225472 GK1_RDWarn_HR 1 "ja" 0 "nein" ;
VAL_ 3221225472 GK1_RDWarn_Res 1 "ja" 0 "nein" ;
VAL_ 3221225472 GK1_RDWarn_HL 1 "ja" 0 "nein" ;
VAL_ 3221225472 GK1_RDWarn_1 1 "ja" 0 "nein" ;
VAL_ 3221225472 GK1_RDK_System 1 "Systemfehler" 0 "kein_Systemfehler" ;
VAL_ 3221225472 GK1_RDWarn_2 1 "ja" 0 "nein" ;
VAL_ 3221225472 BSL_DFM 255 "Fehler" ;
VAL_ 3221225472 BSL_U_Start_BATT 255 "Fehler" ;
VAL_ 80 AB1_Front 1 "Front_Crash" 0 "kein_Front_Crash" ;
VAL_ 80 AB1_Heck 1 "Heck_Crash" 0 "kein_Heck_Crash" ;
VAL_ 80 AB1_Fa_Seite 1 "Seiten_Crash_Fahrer" 0 "kein_Seiten_Crash_Fahrer" ;
VAL_ 80 AB1_Bf_Seite 1 "Seiten_Crash_Beifahrer" 0 "kein_Seiten_Crash_Beifahrer" ;
VAL_ 80 AB1_Rollover 1 "Rollover" 0 "kein_Rollover" ;
VAL_ 80 AB1_Status 1 "deaktiviert" 0 "aktiv" ;
VAL_ 80 AB1_Lampe 1 "Lampe_an" 0 "Lampe_aus" ;
VAL_ 80 AB1_Beifahrer 1 "deaktiviert" 0 "aktiv" ;
VAL_ 80 AB1_System 1 "Systemfehler" 0 "kein_Fehler" ;
VAL_ 80 AB1_Gurt_Fa 3 "Gurt_gesteckt" 2 "Gurt_nicht_gesteckt" 1 "Fehler" 0 "nicht_verfuegbar" ;
VAL_ 80 AB1_Gurt_Bf 3 "Gurt_gesteckt" 2 "Gurt_nicht_gesteckt" 1 "Fehler" 0 "nicht_verfuegbar" ;
VAL_ 80 AB1_Stellglied 1 "im_Stellgliedtest" 0 "nicht_im_Stellgliedtest" ;
VAL_ 80 AB1_BF_Warnung 1 "Gurtwarnung_ausloesen" 0 "keine_Warnung" ;
VAL_ 80 AB1_Diagnose 1 "in_Diagnose" 0 "nicht_in_Diagnose" ;
VAL_ 80 AB1_Intens 7 "RDW_Schw_ueberschritten" 6 "RDW_Schw_ueberschritten" 5 "RDW_Schw_ueberschritten" 4 "RDW_Schw_ueberschritten" 3 "US_Schw_ueberschritten" 2 "US_Schw_ueberschritten" 1 "Gurtstraffer_Schw_ueberschritten" ;
VAL_ 80 AB1_Fehlereintr 1 "Fehlerspeichereintrag" 0 "kein_Fehlerspeichereintrag" ;
VAL_ 1360 AB2_Beleg_HBF 3 "hinten_Beifahrer_belegt" 2 "hinten_Beifahrer_nicht_belegt" 1 "hinten_Beifahrer_Fehler" 0 "hinten_Beif_nicht_verfuegbar" ;
VAL_ 1360 AB2_OOP_BF 7 "nicht_benutzt" 6 "Fahrer_out_of_pos_30" 5 "Fahrer_out_of_pos_70" 4 "Fahrer_in_Position" 3 "nicht_benutzt" 2 "nicht_benutzt" 1 "Fehler" 0 "nicht_verfuegbar" ;
VAL_ 1360 AB2_Beleg_HM 3 "hinten_Mitte_belegt" 2 "hinten_Mitte_nicht_belegt" 1 "hinten_Mitte_Fehler" 0 "hinten_Mitte_nicht_verfuegbar" ;
VAL_ 1360 AB2_Beleg_HF 3 "hinten_Fahrer_belegt" 2 "hinten_Fahrer_nicht_belegt" 1 "hinten_Fahrer_Fehler" 0 "hinten_Fahrer_nicht_verfuegbar" ;
VAL_ 1360 AB2_Beleg_BF 3 "Beifahrersitz_belegt" 2 "Beifahrersitz_nicht_belegt" 1 "Fehler" 0 "nicht_verfuegbar" ;
VAL_ 1360 AB2_OOP_Fa 7 "nicht_benutzt" 6 "Fahrer_out_of_pos_30" 5 "Fahrer_out_of_pos_70" 4 "Fahrer_in_Position" 3 "nicht_benutzt" 2 "nicht_benutzt" 1 "Fehler" 0 "nicht_verfuegbar" ;
VAL_ 1360 AB2_Sta_BF 3 "nicht_benutzt" 2 "BF_Airbag_aktiviert" 1 "BF_Airbag_deaktiviert" 0 "keine_Anzeige" ;
VAL_ 1360 AB2_Gurt_2FaS 3 "Gurt_gesteckt" 2 "Gurt_nicht_gesteckt" 1 "Fehler" 0 "nicht_verfuegbar" ;
VAL_ 1360 AB2_Gurt_2BfS 3 "Gurt_gesteckt" 2 "Gurt_nicht_gesteckt" 1 "Fehler" 0 "nicht_verfuegbar" ;
VAL_ 1360 AB2_Gurt_2Mi 3 "Gurt_gesteckt" 2 "Gurt_nicht_gesteckt" 1 "Fehler" 0 "nicht_verfuegbar" ;
VAL_ 1360 AB2_Gurt_3BfS 3 "Gurt_gesteckt" 2 "Gurt_nicht_gesteckt" 1 "Fehler" 0 "nicht_verfuegbar" ;
VAL_ 1360 AB2_Gurt_3FaS 3 "Gurt_gesteckt" 2 "Gurt_nicht_gesteckt" 1 "Fehler" 0 "nicht_verfuegbar" ;
VAL_ 1360 AB2_Gurt_3Mi 3 "Gurt_gesteckt" 2 "Gurt_nicht_gesteckt" 1 "Fehler" 0 "nicht_verfuegbar" ;
VAL_ 1524 BCN_AntriebsVar 3 "reserviert" 2 "quattro" 1 "front" 0 "keine_Variante" ;
VAL_ 704 AL1_Sta_Kup 1 "dynamisch_nicht_erfuellbar" 0 "erfuellbar" ;
VAL_ 704 AL1_Uebertemp 1 "Uebertemperatur" 0 "keine_Uebertemperatur" ;
VAL_ 704 AL1_Kup_offen 1 "Kupplung_komplett_offen" 0 "Kupplung_nicht_komplett_offen" ;
VAL_ 704 AL1_Fehler 1 "Fehler" 0 "kein_Fehler" ;
VAL_ 704 AL1_Einheit 1 "Prozente" 0 "Nm" ;
VAL_ 704 AL1_Warnlampe 1 "Lampe_ein" 0 "Lampe_aus" ;
VAL_ 704 AL1_Limiter 1 "Geschwindigkeitsbegrenzung" 0 "keine_Begrenzung" ;
VAL_ 704 AL1_Ist_Proz 255 "Fehler" 254 "Kupplung_geschl_100_Prozent" 128 "Kupplung_offen_0_Prozent" 127 "Kupplung_schnell_offen" ;
VAL_ 704 AL1_Notlauf 1 "Notlaufbetrieb" 0 "alles_i_O" ;
VAL_ 704 AL1_Sta_PNG 7 "PNG_Fehlersignal" 6 "Low_Lock" 5 "High_Lock" 4 "Neutral" 3 "frei" 2 "Low_Unlock_PNG_in_LOW_Stellung" 1 "High_Unlock_Normal" 0 "Init" ;
VAL_ 704 AL1_Schalten 1 "Schaltung_laeuft" 0 "keine_Schaltung" ;
VAL_ 704 AL1_Quersp_Sta 3 "Diffsperre_verfaehrt" 2 "Diffsperre_offen" 1 "Diffsperre_geschl" 0 "Fehler" ;
VAL_ 704 AL1_Vorwarnung 1 "Schaltung_wird_durchgefuehrt" 0 "keine_Schaltung" ;
VAL_ 704 AL1_Fehlereintr 1 "Fehlerspeichereintrag" 0 "kein_Fehlerspeichereintrag" ;
VAL_ 704 AL1_Anz_blinken 1 "Blinken_der_PNG_Anzeige" 0 "kein_Blinken_der_PNG_Anzeige" ;
VAL_ 704 AL1_Sta_Laengssp 3 "Fehler_Verteilergetriebe" 2 "Fehler_Sperre" 1 "Sperre_vom_Fahrer_aktiviert" 0 "Sperre_im_Regelmodus" ;
VAL_ 704 AL1_Ist_Nm 255 "Fehler" 254 "Kupplung_ganz_geschl" 127 "Kupplung_schnell_offen" ;
VAL_ 704 AL1_Diff_Verbau 1 "Diffsperre_verbaut" 0 "Diffsperre_nicht_verbaut" ;
VAL_ 704 AL1_AnfVerteiler 1 "Verteiler_Anforderung" 0 "keine_Anforderung" ;
VAL_ 704 AL1_FaWu_Laengs 3 "Fehler_Fahrwerksschalter" 1 "Lockwunsch_Fahrer" 0 "Kein_Fahrerwunsch" ;
VAL_ 704 AL1_FaWu_HA 3 "Fehler_Fahrwerksschalter" 1 "Lockwunsch_Fahrer" 0 "Kein_Fahrerwunsch" ;
VAL_ 704 AL1_Limit_maxkmh 255 "Fehler" 254 "INIT" ;
VAL_ 704 AL1_KupSteifig_F 1 "Kupplungssteifigkeit_0_Prozent" 0 "Kupplungssteifigkeit_unbekannt" ;
VAL_ 704 AL1_FaWu_VA 3 "Fehler_Fahrwerksschalter" 1 "Lockwunsch_Fahrer" 0 "Kein_Fahrerwunsch" ;
VAL_ 704 AL1_Sta_VA 3 "Notlauf_VA_Sperre" 2 "Fehler_Sperre" 1 "Sperre_vom_Fahrer_aktiviert" 0 "Sperre_im_Regelmodus" ;
VAL_ 704 AL1_Sta_Quersp 3 "Fehler_Verteilergetriebe" 2 "Fehler_Sperre" 1 "Sperre_vom_Fahrer_aktiviert" 0 "Sperre_im_Regelmodus" ;
VAL_ 704 AL1_Warnton 1 "Warnton" 0 "kein_Warnton" ;
VAL_ 704 AL1_Stellung_Getr 1 "Schaltgetriebe_in_Neutralstlg" 0 "Schaltgetrieb_nicht_in_Neutrstlg" ;
VAL_ 704 AL1_KupplTemp 255 "Fehler" 254 "INIT" ;
VAL_ 704 AL1_Diff_Lampe 1 "Lampe_ein" 0 "Lampe_aus" ;
VAL_ 704 AL1_Diff_Gong 1 "Gong_ein" 0 "Gong_aus" ;
VAL_ 978 LH2_Geradeaus 1 "Geradeausfahrt" 0 "Keine_Geradeausfahrt" ;
VAL_ 978 LH2_Sta_HCA 7 "Eingriff_aktiv_ohne_Act_Ret" 5 "Eingriff_aktiv_mit_Act_Ret" 4 "Anf_abgewiesen" 3 "bereit" 2 "Anf_nicht_ausf_mit_FSP" 1 "Anf_nicht_ausf_kein_FSP" 0 "deaktiv" ;
VAL_ 978 LH2_Sta_Charisma 3 "Sport" 2 "Normal" 1 "Komfort" 0 "deaktiv" ;
VAL_ 978 LH2_aktLenkeingriff 64 "PLA" 32 "Torque_Steer" 8 "HCA" 2 "DSR" 1 "kein_Eingriff" 0 "Init" ;
VAL_ 978 LH2_Ausg_LW1 1 "aktiviert" 0 "nicht_aktiv" ;
VAL_ 978 LH2_Ausg_LW1_gue 1 "gueltig" 0 "nicht_gueltig" ;
VAL_ 976 LH1_Sicherheitslamp 1 "Lampe_ein" 0 "Lampe_aus" ;
VAL_ 976 LH1_Fehlereintr 1 "Fehlerspeichereintrag" 0 "kein_Fehlerspeichereintrag" ;
VAL_ 976 LH1_SleepInd 1 "Sleep_bereit" 0 "CAN_wird_benoetigt" ;
VAL_ 976 LH1_Fehler_LI 1 "n_iO" 0 "iO" ;
VAL_ 976 LH1_Akustiksign 1 "Akustiksignal_aktiv" 0 "Akustiksignal_nicht_aktiv" ;
VAL_ 976 LH1_NL_LeistDichte 1 "Leistungsdichtebegrenzung" ;
VAL_ 976 LH1_EPS_Diagmode 1 "aktiv" 0 "nicht_aktiv" ;
VAL_ 976 LH1_NL_ECU 1 "ECU_intern_defekt" ;
VAL_ 976 LH1_Textbits 4 "Text_3" 2 "Text_2" 1 "Text_1" 0 "kein_Text" ;
VAL_ 976 LH1_NL_Motor 1 "Servomotordefekt" ;
VAL_ 976 LH1_NL_CAN_SS 1 "CAN_Schnittstelle_Fehler" ;
VAL_ 976 LH1_NL_Sensor 1 "Sensorik_Fehler" ;
VAL_ 976 LH1_NL_Uebertemp 1 "Uebertemperatur" ;
VAL_ 976 LH1_NL_Uebersp 1 "Ueberspannung" ;
VAL_ 976 LH1_NL_Untersp 1 "Unterspannung" ;
VAL_ 976 LH1_Fehlerlampe 1 "Lampe_ein" 0 "Lampe_aus" ;
VAL_ 976 LH1_gue_ECU_Temp 1 "gueltig" 0 "ungueltig" ;
VAL_ 976 LH1_Kuehlung 1 "Anf_Kuehlung" 0 "keine_Anforderung" ;
VAL_ 976 LH1_Mode_Hybrid 1 "Mode_Hybrid_aktiv" 0 "Mode_Hybrid_nicht_aktiv" ;
VAL_ 208 LH3_BLWSign 1 "neg_VZ" 0 "pos_VZ" ;
VAL_ 208 LH3_Sta_DSR 7 "ext_MomLWeingriff_aktiv" 6 "ext_LWeingriff_aktiv" 5 "ext_Momeingriff_aktiv" 4 "DSR_Anf_abgew" 3 "EPS_funktionsbereit" 2 "Kom_ESP_gestoert" 1 "DSR_Anf_nicht_ausfuehrbar" 0 "DSR_deaktiviert" ;
VAL_ 208 LH3_LMSign 1 "neg_VZ" 0 "pos_VZ" ;
VAL_ 208 LH3_Lenkungstyp 3 "EPS_DSR2" 2 "ADS" 1 "APA" 0 "EPS_DSR1" ;
VAL_ 208 LH3_BLWValid 1 "gueltig" 0 "ungueltig" ;
VAL_ 208 LH3_LMValid 1 "gueltig" 0 "ungueltig" ;
VAL_ 416 BR1_MSR_Anf 1 "MSR_Anforderung" 0 "keine_Anforderung" ;
VAL_ 416 BR1_ESP_Eingr 1 "ESP_Eingriff" 0 "kein_ESP_Eingriff" ;
VAL_ 416 BR1_ABS_Brems 1 "ABS_Regelung" 0 "keine_ABS_Regelung" ;
VAL_ 416 BR1_ASR_Anf 1 "ASR_Anforderung" 0 "keine_Anforderung" ;
VAL_ 416 BR1_ASR_Eingr 3 "Schaltverbot" 2 "Rueckschaltung" 1 "ASR_Schaltkennfeld" 0 "keine_Anforderung" ;
VAL_ 416 BR1_EBV_Eingr 1 "EBV_Eingriff" 0 "kein_EBV_Eingriff" ;
VAL_ 416 BR1_StaDruckschw 1 "Sta_n_verf__BKV_angest__Br" 0 "Sta_guel__BKV_n_angest__k_Br" ;
VAL_ 416 BR1_Lampe_ASR 1 "Lampe_ein" 0 "Lampe_aus" ;
VAL_ 416 BR1_Lampe_BK 1 "Lampe_ein" 0 "Lampe_aus" ;
VAL_ 416 BR1_Lichtschalt 1 "Bremse_betaetigt_Schw_ueberschr" 0 "kein_Bremsen_Schw_unterschr" ;
VAL_ 416 BR1_Lampe_ABS 1 "Lampe_ein" 0 "Lampe_aus" ;
VAL_ 416 BR1_MAD 1 "Ausblendung" 0 "keine_Ausblendung" ;
VAL_ 416 BR1_Sta_MAD 1 "ungueltig" 0 "gueltig" ;
VAL_ 416 BR1_ASRMo_sl 255 "Fehler" ;
VAL_ 416 BR1_Diagnose 1 "in_Diagnose" 0 "nein" ;
VAL_ 416 BR1_ASRMo_fa 255 "Fehler" ;
VAL_ 416 BR1_MSR_Mo 255 "Fehler" ;
VAL_ 416 BR1_BKV_aktiv 1 "BKV_verbaut_und_kein_Fehler" 0 "BKV_nicht_verbaut_oder_Fehler" ;
VAL_ 416 BR1_Rad_kmh 32742 "Sensorfehler" 32725 "Unterspannung" 32708 "Init_PQ25_35_46" 32640 "Fehler_D1_BY" 0 "Init_Col_D1" ;
VAL_ 416 BR1_ESPASR_passiv 1 "ESP_oder_ASR_passiv_getastet" 0 "ESP_aktiviert" ;
VAL_ 416 BR1_Sta_ESP 1 "Fehler" 0 "ok" ;
VAL_ 416 BR1_ASR_ESP 1 "ASR_ESP_MABS" 0 "ABS_ABS_EDS" ;
VAL_ 416 BR1_Ersatz_Kmh 1 "Ersatzwert" 0 "i_O" ;
VAL_ 416 BR1_EDS_Eingr 1 "EDS_Eingriff" 0 "kein_EDS_Eingriff" ;
VAL_ 1440 BR2_mi_Radgeschw 32742 "Sensorfehler" 32725 "Unterspannung" 32708 "Init_PQ25_35_46" 32640 "Fehler_D1_BY" 0 "Init_Col_D1" ;
VAL_ 1440 BR2_QB_Querbeschl 1 "Ersatz_Init_Fehler" 0 "gueltiger_Wert" ;
VAL_ 1440 BR2_Querb_Zahn 1 "Zaehnezahl_in_Byte_1" 0 "Querbeschl_In_Byte1" ;
VAL_ 1440 BR2_Querbeschl 255 "Fehler" ;
VAL_ 1440 BR2_Ueberl_Imp 1 "mind_1mal_Ueberlauf" 0 "Reset_und_kein_Ueberlauf" ;
VAL_ 1440 BR2_Fehlereintr 1 "Fehlereintrag" 0 "kein_Fehlereintrag" ;
VAL_ 1440 BR2_LampeHDC 1 "Lampe_ein" 0 "Lampe_aus" ;
VAL_ 1440 BR2_Sta_Imp 1 "Fehler" 0 "Wegimpulse_i_O" ;
VAL_ 1440 BR2_Lampe_ASR 1 "Lampe_ein" 0 "Lampe_aus" ;
VAL_ 1440 BR2_SleepInd 1 "Sleep_bereit" 0 "CAN_wird_benoetigt" ;
VAL_ 1440 BR2_Sta_Quer 1 "gemessen" 0 "errechnet" ;
VAL_ 1440 BR2_Aku_Warn 3 "ein_Mal_Summer_2kHz" 2 "drei_Mal_Gong_Summer" 1 "ein_Mal_Gong" 0 "Kein_Gong_bzw_Summer" ;
VAL_ 1440 BR2_Lampe_ABS 1 "Lampe_ein" 0 "Lampe_aus" ;
VAL_ 1440 BR2_Lampe_BK 1 "Lampe_ein" 0 "Lampe_aus" ;
VAL_ 1440 BR2_HDC_aktiv 1 "HDC_aktiv" 0 "HDC_inaktiv" ;
VAL_ 1440 BR2_Lampe_RKA 1 "Lampe_ein" 0 "Lampe_aus" ;
VAL_ 1440 BR2_Blinkmode 1 "ein" 0 "aus" ;
VAL_ 1440 BR2_Text 13 "Reifen_pruefen" 12 "ABS_ASR_Stoerung" 11 "ASR_aktiviert" 10 "Keine_BKVerstaerkung" 9 "Stoerung_Hillholder" 8 "ESP_aktiv" 7 "ASR_deaktiv" 6 "ESP_deaktiv" 5 "ASR_Stoerung" 4 "Werkstatt_Bremse" 3 "ESP_ABS_Stoerung" 2 "ABS_Stoerung" 1 "ESP_Stoerung" 0 "Kein_Text" ;
